BO_ 2566890251 PB_BSMData_0B: 8 BSM
 SG_ VehSpeedRear : 56|8@1+ (1,0) [0|250] "km/h"  PCM
 SG_ BsmRctbFail : 54|2@1+ (1,0) [0|3] ""  PCM
 SG_ BsmAebFail : 52|2@1+ (1,0) [0|3] ""  PCM
 SG_ BsmBtnSts : 50|1@1+ (1,0) [0|1] ""  PCM
 SG_ RollerbenchActvSts : 48|2@1+ (1,0) [0|3] ""  PCM
 SG_ HbaSts : 46|2@1+ (1,0) [0|3] ""  PCM
 SG_ CwaSts : 44|2@1+ (1,0) [0|3] ""  PCM
 SG_ MsrSts : 42|2@1+ (1,0) [0|3] ""  PCM
 SG_ HhSts : 40|2@1+ (1,0) [0|3] ""  PCM
 SG_ VdcSts : 38|2@1+ (1,0) [0|3] ""  PCM
 SG_ AsrSts : 36|2@1+ (1,0) [0|3] ""  PCM
 SG_ AbsSts : 34|2@1+ (1,0) [0|3] ""  PCM
 SG_ EbdSts : 32|2@1+ (1,0) [0|3] ""  PCM
 SG_ Hdc : 28|3@1+ (1,0) [0|7] ""  PCM
 SG_ BrkSig : 26|2@1+ (1,0) [0|3] ""  PCM
 SG_ VehSoftStop : 24|2@1+ (1,0) [0|3] ""  PCM
 SG_ Eol : 31|1@0+ (1,0) [0|1] ""  PCM
 SG_ VehMov : 22|2@1+ (1,0) [0|3] ""  PCM
 SG_ ParkBrkSw : 20|2@1+ (1,0) [0|3] ""  PCM
 SG_ ParkBrkRelsInhSts : 18|2@1+ (1,0) [0|3] ""  PCM
 SG_ ParkBrkAct : 16|2@1+ (1,0) [0|3] ""  PCM
 SG_ XbrSysSts_FFA30B : 14|2@1+ (1,0) [0|3] ""  PCM
 SG_ ParkBrkActFullyActv_FFA30B : 12|2@1+ (1,0) [0|3] ""  PCM

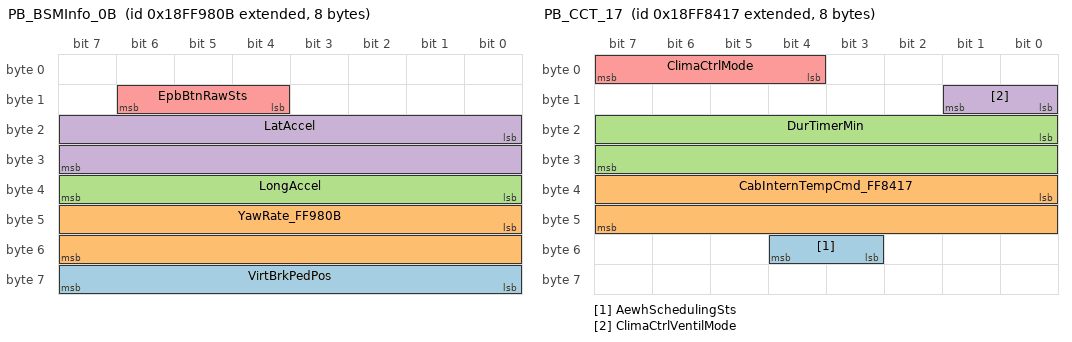
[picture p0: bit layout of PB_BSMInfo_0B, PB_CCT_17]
BO_ 2566887435 PB_BSMInfo_0B: 8 BSM
 SG_ VirtBrkPedPos : 56|8@1+ (0.4,0) [0|100] "%"  PCM
 SG_ YawRate_FF980B : 40|16@1+ (0.0001220703125,-3.92) [-3.92|3.92] "rad/s"  PCM
 SG_ LongAccel : 32|8@1+ (0.1,-12.5) [-12.5|12.5] "m/s�"  PCM
 SG_ LatAccel : 16|16@1+ (0.00048828125,-15.687) [-15.687|15.687] "m/s�"  PCM
 SG_ EpbBtnRawSts : 12|3@1+ (1,0) [0|7] ""  PCM

BO_ 2566854382 PB_CabotageRelData_EE: 32 DTCO
 SG_ LoadType : 248|8@1+ (1,0) [0|255] ""  PCM
 SG_ LastOpPlaceRecAuthenticationSts : 240|8@1+ (1,0) [0|255] ""  PCM
 SG_ LastOpPlaceRecLong : 216|24@1+ (1,180000) [-180000|180001] ""  PCM
 SG_ LastOpPlaceRecLat : 192|24@1+ (1,90000) [-90000|90001] ""  PCM
 SG_ LastOpPlaceRecGnssAccur : 184|8@1+ (1,0) [1|100] ""  PCM
 SG_ LastOpPlaceRecTs : 152|32@1+ (1,0) [0|4211081215] "sec"  PCM
 SG_ LastOpType : 144|8@1+ (1,0) [0|255] ""  PCM
 SG_ LastOpTimeStamp : 112|32@1+ (1,0) [0|4211081215] "sec"  PCM
 SG_ LastBorderCrossingPlaceRecAuthen : 104|8@1+ (1,0) [0|255] ""  PCM
 SG_ LastBorderCrossingPlaceRecLong : 80|24@1+ (1,180000) [-180000|180001] ""  PCM
 SG_ LastBorderCrossingPlaceRecLat : 56|24@1+ (1,90000) [-90000|90001] ""  PCM
 SG_ LastBorderCrossingPlaceRecGnssAc : 48|8@1+ (1,0) [1|100] ""  PCM
 SG_ LastBorderCrossingPlaceRecTs : 16|32@1+ (1,0) [0|4211081215] "sec"  PCM
 SG_ LastCntryEntered : 8|8@1+ (1,0) [0|255] ""  PCM
 SG_ LastCntryLeft : 0|8@1+ (1,0) [0|255] ""  PCM

BO_ 2566897985 PB_CallLog_41: 666 NIS_RDR
 SG_ CallLogIx10Txt : 120|8@1+ (1,0) [0|255] "ASCII"  PCM
 SG_ CallLogIx9Txt : 112|8@1+ (1,0) [0|255] "ASCII"  PCM
 SG_ CallLogIx8Txt : 104|8@1+ (1,0) [0|255] "ASCII"  PCM
 SG_ CallLogIx7Txt : 96|8@1+ (1,0) [0|255] "ASCII"  PCM
 SG_ CallLogIx6Txt : 88|8@1+ (1,0) [0|255] "ASCII"  PCM
 SG_ CallLogIx5Txt : 80|8@1+ (1,0) [0|255] "ASCII"  PCM
 SG_ CallLogIx4Txt : 72|8@1+ (1,0) [0|255] "ASCII"  PCM
 SG_ CallLogIx3Txt : 64|8@1+ (1,0) [0|255] "ASCII"  PCM
 SG_ CallLogIx2Txt : 56|8@1+ (1,0) [0|255] "ASCII"  PCM
 SG_ CallLogIx1Txt : 48|8@1+ (1,0) [0|255] "ASCII"  PCM
 SG_ CallLogIx10Type : 44|4@1+ (1,0) [0|15] ""  PCM
 SG_ CallLogIx9Type : 40|4@1+ (1,0) [0|15] ""  PCM
 SG_ CallLogIx8Type : 36|4@1+ (1,0) [0|15] ""  PCM
 SG_ CallLogIx7Type : 32|4@1+ (1,0) [0|15] ""  PCM
 SG_ CallLogIx6Type : 28|4@1+ (1,0) [0|15] ""  PCM
 SG_ CallLogIx5Type : 24|4@1+ (1,0) [0|15] ""  PCM
 SG_ CallLogIx4Type : 20|4@1+ (1,0) [0|15] ""  PCM
 SG_ CallLogIx3Type : 16|4@1+ (1,0) [0|15] ""  PCM
 SG_ CallLogIx2Type : 12|4@1+ (1,0) [0|15] ""  PCM
 SG_ CallLogIx1Type : 8|4@1+ (1,0) [0|15] ""  PCM
 SG_ CallLogEntriesNum : 4|4@1+ (1,0) [0|15] ""  PCM
 SG_ DevIx : 2|2@1+ (1,0) [0|3] ""  PCM
 SG_ TelephoneConn : 0|2@1+ (1,0) [0|3] ""  PCM

BO_ 2566882327 PB_CCT_17: 8 ICC
 SG_ AewhSchedulingSts : 51|2@1+ (1,0) [0|3] ""  PCM
 SG_ CabInternTempCmd_FF8417 : 32|16@1+ (0.03125,-273) [-273|1734.96875] "�C"  PCM
 SG_ DurTimerMin : 16|16@1+ (1,0) [0|64255] "min"  PCM
 SG_ ClimaCtrlVentilMode : 8|2@1+ (1,0) [0|3] ""  PCM
 SG_ ClimaCtrlMode : 4|4@1+ (1,0) [0|15] ""  PCM

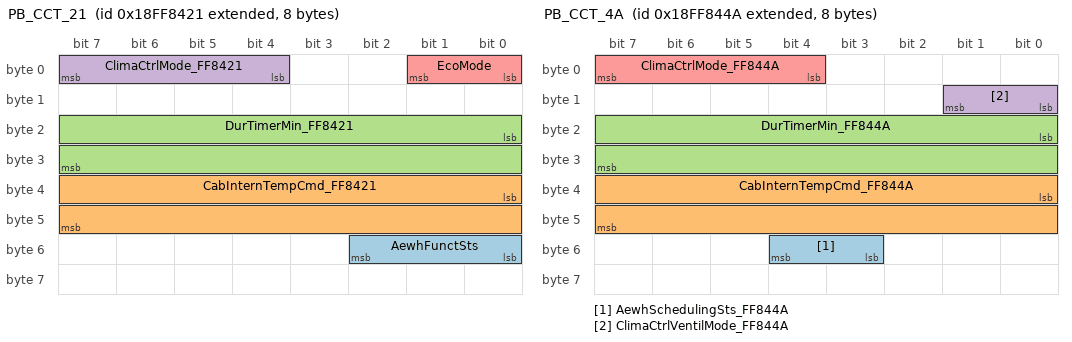
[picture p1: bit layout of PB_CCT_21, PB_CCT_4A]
BO_ 2566882337 PB_CCT_21: 8 BCM
 SG_ AewhFunctSts : 48|3@1+ (1,0) [0|7] ""  PCM
 SG_ CabInternTempCmd_FF8421 : 32|16@1+ (0.03125,-273) [-273|1734.96875] "�C"  PCM
 SG_ DurTimerMin_FF8421 : 16|16@1+ (1,0) [0|64255] "min"  PCM
 SG_ ClimaCtrlMode_FF8421 : 4|4@1+ (1,0) [0|15] ""  PCM
 SG_ EcoMode : 0|2@1+ (1,0) [0|3] ""  PCM

BO_ 2566882378 PB_CCT_4A: 8 PCM
 SG_ AewhSchedulingSts_FF844A : 51|2@1+ (1,0) [0|3] "" Vector__XXX
 SG_ CabInternTempCmd_FF844A : 32|16@1+ (0.03125,-273) [-273|1734.96875] "�C" Vector__XXX
 SG_ DurTimerMin_FF844A : 16|16@1+ (1,0) [0|64255] "min" Vector__XXX
 SG_ ClimaCtrlVentilMode_FF844A : 8|2@1+ (1,0) [0|3] "" Vector__XXX
 SG_ ClimaCtrlMode_FF844A : 4|4@1+ (1,0) [0|15] "" Vector__XXX

BO_ 2583654960 PB_CDCInfo_30: 8 CDC
 SG_ CdcActvMode : 0|4@1+ (1,0) [0|15] ""  PCM

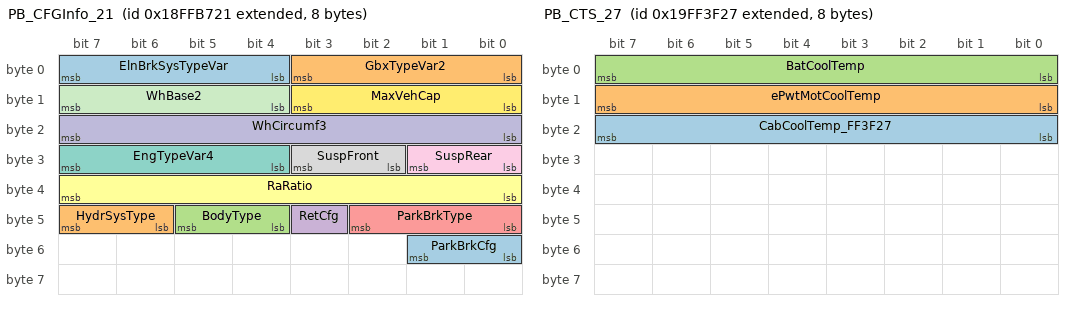
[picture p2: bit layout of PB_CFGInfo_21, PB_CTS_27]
BO_ 2566895393 PB_CFGInfo_21: 8 BCM
 SG_ ParkBrkCfg : 48|2@1+ (1,0) [0|3] ""  PCM
 SG_ HydrSysType : 46|2@1+ (1,0) [0|3] ""  PCM
 SG_ BodyType : 44|2@1+ (1,0) [0|3] ""  PCM
 SG_ RetCfg : 43|1@1+ (1,0) [0|1] ""  PCM
 SG_ ParkBrkType : 40|3@1+ (1,0) [0|7] ""  PCM
 SG_ RaRatio : 32|8@1+ (0.02,2.9) [2.9|8] ""  PCM
 SG_ EngTypeVar4 : 28|4@1+ (1,0) [0|15] ""  PCM
 SG_ SuspFront : 26|2@1+ (1,0) [0|3] ""  PCM
 SG_ SuspRear : 24|2@1+ (1,0) [0|3] ""  PCM
 SG_ WhCircumf3 : 16|8@1+ (5,1840) [1845|3115] "mm"  PCM
 SG_ WhBase2 : 12|4@1+ (1,0) [0|15] ""  PCM
 SG_ MaxVehCap : 8|4@1+ (1,0) [0|15] ""  PCM
 SG_ ElnBrkSysTypeVar : 4|4@1+ (1,0) [0|15] ""  PCM
 SG_ GbxTypeVar2 : 0|4@1+ (1,0) [0|15] ""  PCM

BO_ 2650777478 PB_CHGTC_86: 20 NODE_86
 SG_ ChgBelowNeg20_h : 144|16@1+ (1,0) [0|65535] "h"  PCM
 SG_ ChgBelowNeg10_h : 128|16@1+ (1,0) [0|65535] "h"  PCM
 SG_ ChgBelow0_h : 112|16@1+ (1,0) [0|65535] "h"  PCM
 SG_ ChgOver0_h : 96|16@1+ (1,0) [0|65535] "h"  PCM
 SG_ ChgOver15_h : 80|16@1+ (1,0) [0|65535] "h"  PCM
 SG_ ChgOver30_h : 64|16@1+ (1,0) [0|65535] "h"  PCM
 SG_ ChgOver35_h : 48|16@1+ (1,0) [0|65535] "h"  PCM
 SG_ ChgOver40_h : 32|16@1+ (1,0) [0|65535] "h"  PCM
 SG_ ChgOver45_h : 16|16@1+ (1,0) [0|65535] "h"  PCM
 SG_ ChgOver55_h : 0|16@1+ (1,0) [0|65535] "h"  PCM

BO_ 2650777479 PB_CHGTC_87: 20 NODE_87
 SG_ ChgBelowNeg20_h_FFA787 : 144|16@1+ (1,0) [0|65535] "h"  PCM
 SG_ ChgBelowNeg10_h_FFA787 : 128|16@1+ (1,0) [0|65535] "h"  PCM
 SG_ ChgBelow0_h_FFA787 : 112|16@1+ (1,0) [0|65535] "h"  PCM
 SG_ ChgOver0_h_FFA787 : 96|16@1+ (1,0) [0|65535] "h"  PCM
 SG_ ChgOver15_h_FFA787 : 80|16@1+ (1,0) [0|65535] "h"  PCM
 SG_ ChgOver30_h_FFA787 : 64|16@1+ (1,0) [0|65535] "h"  PCM
 SG_ ChgOver35_h_FFA787 : 48|16@1+ (1,0) [0|65535] "h"  PCM
 SG_ ChgOver40_h_FFA787 : 32|16@1+ (1,0) [0|65535] "h"  PCM
 SG_ ChgOver45_h_FFA787 : 16|16@1+ (1,0) [0|65535] "h"  PCM
 SG_ ChgOver55_h_FFA787 : 0|16@1+ (1,0) [0|65535] "h"  PCM

BO_ 2650777588 PB_CHGTC_F4: 20 NODE_F4
 SG_ ChgBelowNeg20_h_FFA7F4 : 144|16@1+ (1,0) [0|65535] "h"  PCM
 SG_ ChgBelowNeg10_h_FFA7F4 : 128|16@1+ (1,0) [0|65535] "h"  PCM
 SG_ ChgBelow0_h_FFA7F4 : 112|16@1+ (1,0) [0|65535] "h"  PCM
 SG_ ChgOver0_h_FFA7F4 : 96|16@1+ (1,0) [0|65535] "h"  PCM
 SG_ ChgOver15_h_FFA7F4 : 80|16@1+ (1,0) [0|65535] "h"  PCM
 SG_ ChgOver30_h_FFA7F4 : 64|16@1+ (1,0) [0|65535] "h"  PCM
 SG_ ChgOver35_h_FFA7F4 : 48|16@1+ (1,0) [0|65535] "h"  PCM
 SG_ ChgOver40_h_FFA7F4 : 32|16@1+ (1,0) [0|65535] "h"  PCM
 SG_ ChgOver45_h_FFA7F4 : 16|16@1+ (1,0) [0|65535] "h"  PCM
 SG_ ChgOver55_h_FFA7F4 : 0|16@1+ (1,0) [0|65535] "h"  PCM

BO_ 2650777589 PB_CHGTC_F5: 20 NODE_F5
 SG_ ChgBelowNeg20_h_FFA7F5 : 144|16@1+ (1,0) [0|65535] "h"  PCM
 SG_ ChgBelowNeg10_h_FFA7F5 : 128|16@1+ (1,0) [0|65535] "h"  PCM
 SG_ ChgBelow0_h_FFA7F5 : 112|16@1+ (1,0) [0|65535] "h"  PCM
 SG_ ChgOver0_h_FFA7F5 : 96|16@1+ (1,0) [0|65535] "h"  PCM
 SG_ ChgOver15_h_FFA7F5 : 80|16@1+ (1,0) [0|65535] "h"  PCM
 SG_ ChgOver30_h_FFA7F5 : 64|16@1+ (1,0) [0|65535] "h"  PCM
 SG_ ChgOver35_h_FFA7F5 : 48|16@1+ (1,0) [0|65535] "h"  PCM
 SG_ ChgOver40_h_FFA7F5 : 32|16@1+ (1,0) [0|65535] "h"  PCM
 SG_ ChgOver45_h_FFA7F5 : 16|16@1+ (1,0) [0|65535] "h"  PCM
 SG_ ChgOver55_h_FFA7F5 : 0|16@1+ (1,0) [0|65535] "h"  PCM

BO_ 2650777590 PB_CHGTC_F6: 20 NODE_F6
 SG_ ChgBelowNeg20_h_FFA7F6 : 144|16@1+ (1,0) [0|65535] "h"  PCM
 SG_ ChgBelowNeg10_h_FFA7F6 : 128|16@1+ (1,0) [0|65535] "h"  PCM
 SG_ ChgBelow0_h_FFA7F6 : 112|16@1+ (1,0) [0|65535] "h"  PCM
 SG_ ChgOver0_h_FFA7F6 : 96|16@1+ (1,0) [0|65535] "h"  PCM
 SG_ ChgOver15_h_FFA7F6 : 80|16@1+ (1,0) [0|65535] "h"  PCM
 SG_ ChgOver30_h_FFA7F6 : 64|16@1+ (1,0) [0|65535] "h"  PCM
 SG_ ChgOver35_h_FFA7F6 : 48|16@1+ (1,0) [0|65535] "h"  PCM
 SG_ ChgOver40_h_FFA7F6 : 32|16@1+ (1,0) [0|65535] "h"  PCM
 SG_ ChgOver45_h_FFA7F6 : 16|16@1+ (1,0) [0|65535] "h"  PCM
 SG_ ChgOver55_h_FFA7F6 : 0|16@1+ (1,0) [0|65535] "h"  PCM

BO_ 2583641895 PB_CTS_27: 8 VCM
 SG_ CabCoolTemp_FF3F27 : 16|8@1+ (1,-40) [-40|210] "�C"  PCM
 SG_ ePwtMotCoolTemp : 8|8@1+ (1,-40) [-40|210] "�C"  PCM
 SG_ BatCoolTemp : 0|8@1+ (1,-40) [-40|210] "�C"  PCM

BO_ 2566910273 PB_DevInf_41: 67 NIS_RDR
 SG_ DevName : 8|8@1+ (1,0) [0|255] "ASCII"  PCM
 SG_ DevIx_FFF141 : 0|2@1+ (1,0) [0|3] ""  PCM

BO_ 2566883879 PB_DPD_27: 8 VCM
 SG_ RngDeterminationRstFdbk : 24|2@1+ (1,0) [0|3] ""  PCM
 SG_ DrivProfIdFdbk : 19|3@1+ (1,0) [0|7] ""  PCM

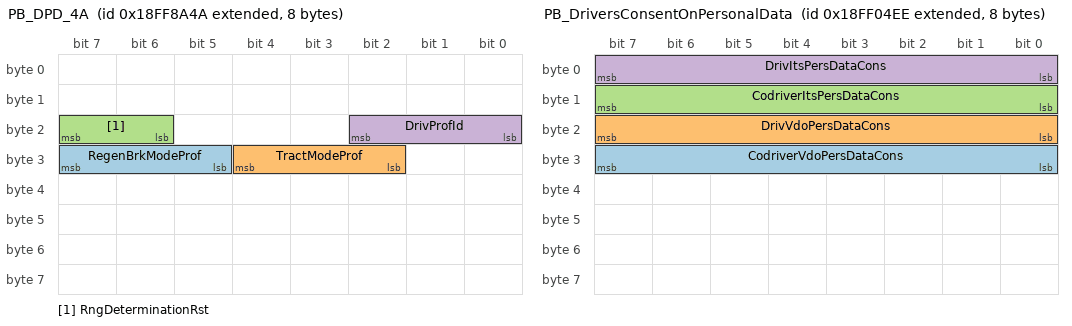
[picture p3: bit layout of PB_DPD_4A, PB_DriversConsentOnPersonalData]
BO_ 2566883914 PB_DPD_4A: 8 PCM
 SG_ RegenBrkModeProf : 29|3@1+ (1,0) [0|7] "" Vector__XXX
 SG_ TractModeProf : 26|3@1+ (1,0) [0|7] "" Vector__XXX
 SG_ RngDeterminationRst : 22|2@1+ (1,0) [0|3] "" Vector__XXX
 SG_ DrivProfId : 16|3@1+ (1,0) [0|7] "" Vector__XXX

BO_ 2566849774 PB_DriversConsentOnPersonalData: 8 DTCO
 SG_ CodriverVdoPersDataCons : 24|8@1+ (1,0) [0|250] ""  PCM
 SG_ DrivVdoPersDataCons : 16|8@1+ (1,0) [0|250] ""  PCM
 SG_ CodriverItsPersDataCons : 8|8@1+ (1,0) [0|250] ""  PCM
 SG_ DrivItsPersDataCons : 0|8@1+ (1,0) [0|250] ""  PCM

BO_ 2566865994 PB_Dse_4A: 40 PCM
 SG_ DseIxBenf_10 : 312|8@1+ (1,0) [0|100] "" Vector__XXX
 SG_ DseIxVal_10 : 304|8@1+ (1,0) [0|100] "" Vector__XXX
 SG_ DseIxFrzSts_10 : 298|2@1+ (1,0) [0|3] "" Vector__XXX
 SG_ DseIxTrend_10 : 296|2@1+ (1,0) [0|3] "" Vector__XXX
 SG_ DseIxBenf_9 : 288|8@1+ (1,0) [0|100] "" Vector__XXX
 SG_ DseIxVal_9 : 280|8@1+ (1,0) [0|100] "" Vector__XXX
 SG_ DseIxFrzSts_9 : 274|2@1+ (1,0) [0|3] "" Vector__XXX
 SG_ DseIxTrend_9 : 272|2@1+ (1,0) [0|3] "" Vector__XXX
 SG_ DseIxBenf_8 : 264|8@1+ (1,0) [0|100] "" Vector__XXX
 SG_ DseIxVal_8 : 256|8@1+ (1,0) [0|100] "" Vector__XXX
 SG_ DseIxFrzSts_8 : 250|2@1+ (1,0) [0|3] "" Vector__XXX
 SG_ DseIxTrend_8 : 248|2@1+ (1,0) [0|3] "" Vector__XXX
 SG_ DseIxBenf_7 : 240|8@1+ (1,0) [0|100] "" Vector__XXX
 SG_ DseIxVal_7 : 232|8@1+ (1,0) [0|100] "" Vector__XXX
 SG_ DseIxFrzSts_7 : 226|2@1+ (1,0) [0|3] "" Vector__XXX
 SG_ DseIxTrend_7 : 224|2@1+ (1,0) [0|3] "" Vector__XXX
 SG_ DseIxBenf_6 : 216|8@1+ (1,0) [0|100] "" Vector__XXX
 SG_ DseIxVal_6 : 208|8@1+ (1,0) [0|100] "" Vector__XXX
 SG_ DseIxFrzSts_6 : 202|2@1+ (1,0) [0|3] "" Vector__XXX
 SG_ DseIxTrend_6 : 200|2@1+ (1,0) [0|3] "" Vector__XXX
 SG_ DseIxBenf_5 : 192|8@1+ (1,0) [0|100] "" Vector__XXX
 SG_ DseIxVal_5 : 184|8@1+ (1,0) [0|100] "" Vector__XXX
 SG_ DseIxFrzSts_5 : 178|2@1+ (1,0) [0|3] "" Vector__XXX
 SG_ DseIxTrend_5 : 176|2@1+ (1,0) [0|3] "" Vector__XXX
 SG_ DseIxBenf_4 : 168|8@1+ (1,0) [0|100] "" Vector__XXX
 SG_ DseIxVal_4 : 160|8@1+ (1,0) [0|100] "" Vector__XXX
 SG_ DseIxFrzSts_4 : 154|2@1+ (1,0) [0|3] "" Vector__XXX
 SG_ DseIxTrend_4 : 152|2@1+ (1,0) [0|3] "" Vector__XXX
 SG_ DseIxBenf_3_EngUse : 144|8@1+ (1,0) [0|100] "" Vector__XXX
 SG_ DseIxVal_3_EngUse : 136|8@1+ (1,0) [0|100] "" Vector__XXX
 SG_ DseIxFrzSts_3_EngUse : 130|2@1+ (1,0) [0|3] "" Vector__XXX
 SG_ DseIxTrend_3_EngUse : 128|2@1+ (1,0) [0|3] "" Vector__XXX
 SG_ DseIxBenf_2_Decel : 120|8@1+ (1,0) [0|100] "" Vector__XXX
 SG_ DseIxVal_2_Decel : 112|8@1+ (1,0) [0|100] "" Vector__XXX
 SG_ DseIxFrzSts_2_Decel : 106|2@1+ (1,0) [0|3] "" Vector__XXX
 SG_ DseIxTrend_2_Decel : 104|2@1+ (1,0) [0|3] "" Vector__XXX
 SG_ DseIxBenf_1_Accel : 96|8@1+ (1,0) [0|100] "" Vector__XXX
 SG_ DseIxVal_1_Accel : 88|8@1+ (1,0) [0|100] "" Vector__XXX
 SG_ DseIxFrzSts_1_Accel : 82|2@1+ (1,0) [0|3] "" Vector__XXX
 SG_ DseIxTrend_1_Accel : 80|2@1+ (1,0) [0|3] "" Vector__XXX
 SG_ DseEvalTime : 64|16@1+ (1,0) [0|64255] "s" Vector__XXX
 SG_ DseEvalDist : 48|16@1+ (0.1,0) [0|6425.5] "km" Vector__XXX
 SG_ DseStartMissTs : 16|32@1+ (1,0) [0|4211081215] "" Vector__XXX
 SG_ DsePopupIx : 8|8@1+ (1,0) [0|100] "" Vector__XXX
 SG_ DsePopupIcon : 4|4@1+ (1,0) [0|15] "" Vector__XXX
 SG_ DseSts : 0|4@1+ (1,0) [0|15] "" Vector__XXX

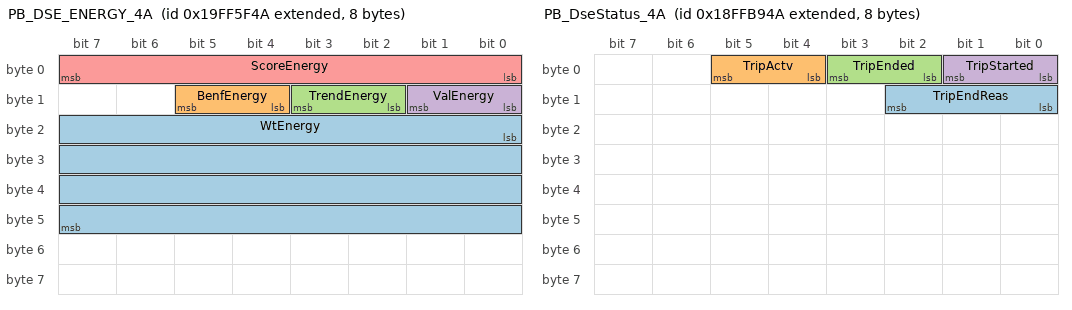
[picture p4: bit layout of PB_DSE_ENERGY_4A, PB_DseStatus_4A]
BO_ 2583650122 PB_DSE_ENERGY_4A: 8 PCM
 SG_ WtEnergy : 16|32@1+ (1,-1) [-1|4294967294] "" Vector__XXX
 SG_ BenfEnergy : 12|2@1+ (1,0) [0|3] "" Vector__XXX
 SG_ TrendEnergy : 10|2@1+ (1,-1) [-1|2] "" Vector__XXX
 SG_ ValEnergy : 8|2@1+ (1,0) [0|3] "" Vector__XXX
 SG_ ScoreEnergy : 0|8@1+ (1,-1) [-1|254] "" Vector__XXX

BO_ 2566895690 PB_DseStart_4A: 8 PCM
 SG_ TsTripStart : 32|32@1+ (1,946684800) [946684800|5157766015] "count" Vector__XXX
 SG_ OdoTripStart : 0|32@1+ (5,-1) [-1|21055406074] "m" Vector__XXX

BO_ 2566895946 PB_DseStatus_4A: 8 PCM
 SG_ TripEndReas : 8|3@1+ (1,0) [0|7] "" Vector__XXX
 SG_ TripActv : 4|2@1+ (1,0) [0|3] "" Vector__XXX
 SG_ TripEnded : 2|2@1+ (1,0) [0|3] "" Vector__XXX
 SG_ TripStarted : 0|2@1+ (1,0) [0|3] "" Vector__XXX

BO_ 2650777222 PB_DSGTC_86: 20 NODE_86
 SG_ DsgBelowNeg20_h : 144|16@1+ (1,0) [0|65535] "h"  PCM
 SG_ DsgBelowNeg10_h : 128|16@1+ (1,0) [0|65535] "h"  PCM
 SG_ DsgBelow0_h : 112|16@1+ (1,0) [0|65535] "h"  PCM
 SG_ DsgOver0_h : 96|16@1+ (1,0) [0|65535] "h"  PCM
 SG_ DsgOver15_h : 80|16@1+ (1,0) [0|65535] "h"  PCM
 SG_ DsgOver30_h : 64|16@1+ (1,0) [0|65535] "h"  PCM
 SG_ DsgOver35_h : 48|16@1+ (1,0) [0|65535] "h"  PCM
 SG_ DsgOver40_h : 32|16@1+ (1,0) [0|65535] "h"  PCM
 SG_ DsgOver45_h : 16|16@1+ (1,0) [0|65535] "h"  PCM
 SG_ DsgOver55_h : 0|16@1+ (1,0) [0|65535] "h"  PCM

BO_ 2650777223 PB_DSGTC_87: 20 NODE_87
 SG_ DsgBelowNeg20_h_FFA687 : 144|16@1+ (1,0) [0|65535] "h"  PCM
 SG_ DsgBelowNeg10_h_FFA687 : 128|16@1+ (1,0) [0|65535] "h"  PCM
 SG_ DsgBelow0_h_FFA687 : 112|16@1+ (1,0) [0|65535] "h"  PCM
 SG_ DsgOver0_h_FFA687 : 96|16@1+ (1,0) [0|65535] "h"  PCM
 SG_ DsgOver15_h_FFA687 : 80|16@1+ (1,0) [0|65535] "h"  PCM
 SG_ DsgOver30_h_FFA687 : 64|16@1+ (1,0) [0|65535] "h"  PCM
 SG_ DsgOver35_h_FFA687 : 48|16@1+ (1,0) [0|65535] "h"  PCM
 SG_ DsgOver40_h_FFA687 : 32|16@1+ (1,0) [0|65535] "h"  PCM
 SG_ DsgOver45_h_FFA687 : 16|16@1+ (1,0) [0|65535] "h"  PCM
 SG_ DsgOver55_h_FFA687 : 0|16@1+ (1,0) [0|65535] "h"  PCM

BO_ 2650777332 PB_DSGTC_F4: 20 NODE_F4
 SG_ DsgBelowNeg20_h_FFA6F4 : 144|16@1+ (1,0) [0|65535] "h"  PCM
 SG_ DsgBelowNeg10_h_FFA6F4 : 128|16@1+ (1,0) [0|65535] "h"  PCM
 SG_ DsgBelow0_h_FFA6F4 : 112|16@1+ (1,0) [0|65535] "h"  PCM
 SG_ DsgOver0_h_FFA6F4 : 96|16@1+ (1,0) [0|65535] "h"  PCM
 SG_ DsgOver15_h_FFA6F4 : 80|16@1+ (1,0) [0|65535] "h"  PCM
 SG_ DsgOver30_h_FFA6F4 : 64|16@1+ (1,0) [0|65535] "h"  PCM
 SG_ DsgOver35_h_FFA6F4 : 48|16@1+ (1,0) [0|65535] "h"  PCM
 SG_ DsgOver40_h_FFA6F4 : 32|16@1+ (1,0) [0|65535] "h"  PCM
 SG_ DsgOver45_h_FFA6F4 : 16|16@1+ (1,0) [0|65535] "h"  PCM
 SG_ DsgOver55_h_FFA6F4 : 0|16@1+ (1,0) [0|65535] "h"  PCM

BO_ 2650777333 PB_DSGTC_F5: 20 NODE_F5
 SG_ DsgBelowNeg20_h_FFA6F5 : 144|16@1+ (1,0) [0|65535] "h"  PCM
 SG_ DsgBelowNeg10_h_FFA6F5 : 128|16@1+ (1,0) [0|65535] "h"  PCM
 SG_ DsgBelow0_h_FFA6F5 : 112|16@1+ (1,0) [0|65535] "h"  PCM
 SG_ DsgOver0_h_FFA6F5 : 96|16@1+ (1,0) [0|65535] "h"  PCM
 SG_ DsgOver15_h_FFA6F5 : 80|16@1+ (1,0) [0|65535] "h"  PCM
 SG_ DsgOver30_h_FFA6F5 : 64|16@1+ (1,0) [0|65535] "h"  PCM
 SG_ DsgOver35_h_FFA6F5 : 48|16@1+ (1,0) [0|65535] "h"  PCM
 SG_ DsgOver40_h_FFA6F5 : 32|16@1+ (1,0) [0|65535] "h"  PCM
 SG_ DsgOver45_h_FFA6F5 : 16|16@1+ (1,0) [0|65535] "h"  PCM
 SG_ DsgOver55_h_FFA6F5 : 0|16@1+ (1,0) [0|65535] "h"  PCM

BO_ 2650777334 PB_DSGTC_F6: 20 NODE_F6
 SG_ DsgBelowNeg20_h_FFA6F6 : 144|16@1+ (1,0) [0|65535] "h"  PCM
 SG_ DsgBelowNeg10_h_FFA6F6 : 128|16@1+ (1,0) [0|65535] "h"  PCM
 SG_ DsgBelow0_h_FFA6F6 : 112|16@1+ (1,0) [0|65535] "h"  PCM
 SG_ DsgOver0_h_FFA6F6 : 96|16@1+ (1,0) [0|65535] "h"  PCM
 SG_ DsgOver15_h_FFA6F6 : 80|16@1+ (1,0) [0|65535] "h"  PCM
 SG_ DsgOver30_h_FFA6F6 : 64|16@1+ (1,0) [0|65535] "h"  PCM
 SG_ DsgOver35_h_FFA6F6 : 48|16@1+ (1,0) [0|65535] "h"  PCM
 SG_ DsgOver40_h_FFA6F6 : 32|16@1+ (1,0) [0|65535] "h"  PCM
 SG_ DsgOver45_h_FFA6F6 : 16|16@1+ (1,0) [0|65535] "h"  PCM
 SG_ DsgOver55_h_FFA6F6 : 0|16@1+ (1,0) [0|65535] "h"  PCM

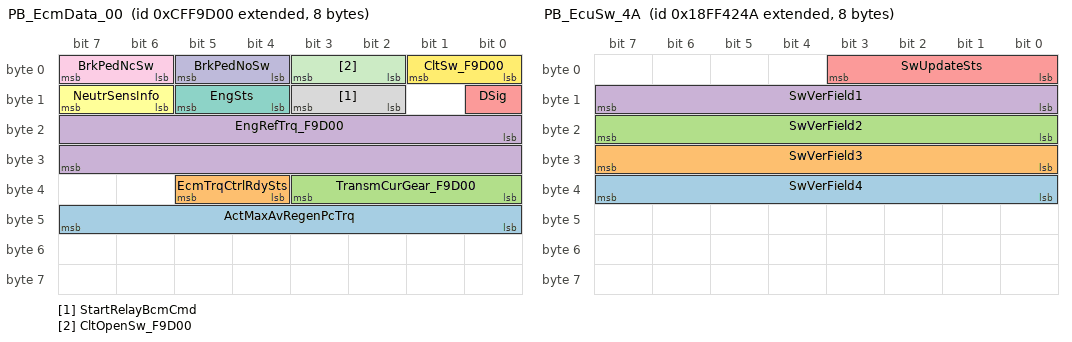
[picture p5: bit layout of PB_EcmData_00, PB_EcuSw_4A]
BO_ 2365562112 PB_EcmData_00: 8 ECM
 SG_ ActMaxAvRegenPcTrq : 40|8@1+ (0.4,0) [0|100] "%"  PCM
 SG_ EcmTrqCtrlRdySts : 36|2@1+ (1,0) [0|3] ""  PCM
 SG_ TransmCurGear_F9D00 : 32|4@1+ (1,0) [0|15] ""  PCM
 SG_ EngRefTrq_F9D00 : 16|16@1+ (1,0) [0|64255] "Nm"  PCM
 SG_ DSig : 8|1@0+ (1,0) [0|1] ""  PCM
 SG_ NeutrSensInfo : 14|2@1+ (1,0) [0|3] ""  PCM
 SG_ EngSts : 12|2@1+ (1,0) [0|3] ""  PCM
 SG_ StartRelayBcmCmd : 10|2@1+ (1,0) [0|3] ""  PCM
 SG_ BrkPedNcSw : 6|2@1+ (1,0) [0|3] ""  PCM
 SG_ BrkPedNoSw : 4|2@1+ (1,0) [0|3] ""  PCM
 SG_ CltOpenSw_F9D00 : 2|2@1+ (1,0) [0|3] ""  PCM
 SG_ CltSw_F9D00 : 0|2@1+ (1,0) [0|3] ""  PCM

BO_ 2566865482 PB_EcuSw_4A: 8 PCM
 SG_ SwVerField4 : 32|8@1+ (1,0) [0|250] "" Vector__XXX
 SG_ SwVerField3 : 24|8@1+ (1,0) [0|250] "" Vector__XXX
 SG_ SwVerField2 : 16|8@1+ (1,0) [0|250] "" Vector__XXX
 SG_ SwVerField1 : 8|8@1+ (1,0) [0|250] "" Vector__XXX
 SG_ SwUpdateSts : 0|4@1+ (1,0) [0|15] "" Vector__XXX

BO_ 2583638311 PB_ED1_27: 8 VCM
 SG_ TotHvacEnergyConsHeatBat : 32|32@1+ (0.1,0) [0|421108121.5] "kWh"  PCM
 SG_ TotHvacEnergyConsHeatCab : 0|32@1+ (0.1,0) [0|421108121.5] "kWh"  PCM

BO_ 2583638567 PB_ED2_27: 8 VCM
 SG_ TotEnergyRecharged : 32|32@1+ (0.1,0) [0|421108121.5] "kWh"  PCM
 SG_ TotHvacEnergyConsCool : 0|32@1+ (0.1,0) [0|421108121.5] "kWh"  PCM

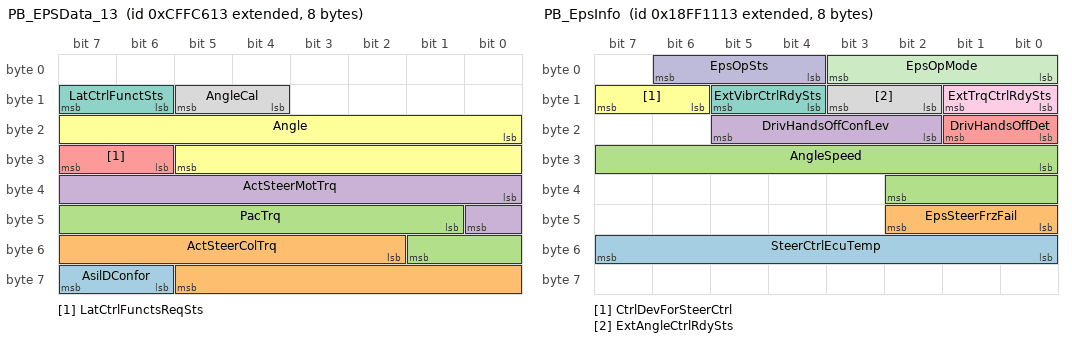
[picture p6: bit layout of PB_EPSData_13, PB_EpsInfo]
BO_ 2365572627 PB_EPSData_13: 8 NODE_13
 SG_ AsilDConfor : 62|2@1+ (1,0) [0|3] ""  PCM
 SG_ ActSteerColTrq : 50|12@1+ (0.005,-10) [-10|10.075] "Nm"  PCM
 SG_ PacTrq : 41|9@1+ (0.04,-10) [-10|10.24] "Nm"  PCM
 SG_ ActSteerMotTrq : 32|9@1+ (0.04,-10) [-10|10.24] "Nm"  PCM
 SG_ LatCtrlFunctsReqSts : 30|2@1+ (1,0) [0|3] ""  PCM
 SG_ Angle : 16|14@1+ (0.1,-818.9) [-818.9|818.9] "deg"  PCM
 SG_ LatCtrlFunctSts : 14|2@1+ (1,0) [0|3] ""  PCM
 SG_ AngleCal : 12|2@1+ (1,0) [0|3] ""  PCM

BO_ 2566852883 PB_EpsInfo: 8 NODE_13
 SG_ SteerCtrlEcuTemp : 48|8@1+ (1,-40) [-40|210] "�C"  PCM
 SG_ EpsSteerFrzFail : 40|3@1+ (1,0) [0|7] ""  PCM
 SG_ AngleSpeed : 24|11@1+ (1,-1021) [-1021|1021] "deg/s"  PCM
 SG_ DrivHandsOffConfLev : 18|4@1+ (1,0) [0|15] ""  PCM
 SG_ DrivHandsOffDet : 16|2@1+ (1,0) [0|3] ""  PCM
 SG_ CtrlDevForSteerCtrl : 14|2@1+ (1,0) [0|3] ""  PCM
 SG_ ExtVibrCtrlRdySts : 12|2@1+ (1,0) [0|3] ""  PCM
 SG_ ExtAngleCtrlRdySts : 10|2@1+ (1,0) [0|3] ""  PCM
 SG_ ExtTrqCtrlRdySts : 8|2@1+ (1,0) [0|3] ""  PCM
 SG_ EpsOpSts : 4|3@1+ (1,0) [0|7] ""  PCM
 SG_ EpsOpMode : 0|4@1+ (1,0) [0|15] ""  PCM

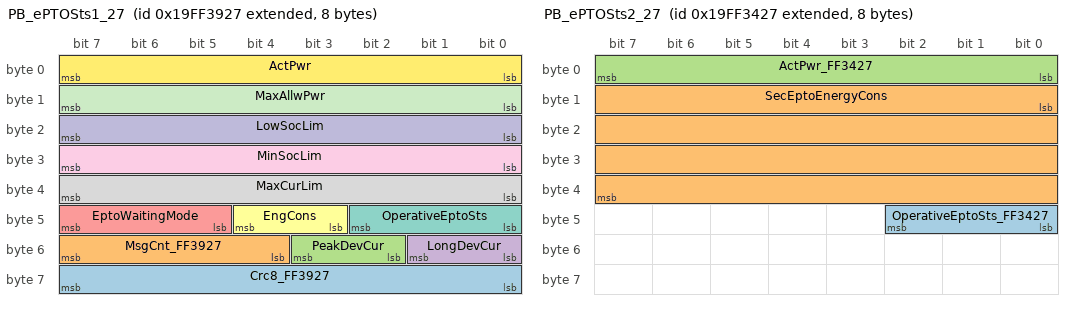
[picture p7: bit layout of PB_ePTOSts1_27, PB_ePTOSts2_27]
BO_ 2583640359 PB_ePTOSts1_27: 8 VCM
 SG_ Crc8_FF3927 : 56|8@1+ (1,0) [0|255] ""  PCM
 SG_ MsgCnt_FF3927 : 52|4@1+ (1,0) [0|15] "count"  PCM
 SG_ PeakDevCur : 50|2@1+ (1,0) [0|3] ""  PCM
 SG_ LongDevCur : 48|2@1+ (1,0) [0|3] ""  PCM
 SG_ EptoWaitingMode : 45|3@1+ (1,0) [0|7] ""  PCM
 SG_ EngCons : 43|2@1+ (1,0) [0|3] ""  PCM
 SG_ OperativeEptoSts : 40|3@1+ (1,0) [0|7] ""  PCM
 SG_ MaxCurLim : 32|8@1+ (0.5,0) [0|125] "A"  PCM
 SG_ MinSocLim : 24|8@1+ (0.4,0) [0|100] "%"  PCM
 SG_ LowSocLim : 16|8@1+ (0.4,0) [0|100] "%"  PCM
 SG_ MaxAllwPwr : 8|8@1+ (0.5,0) [0|125] "kW"  PCM
 SG_ ActPwr : 0|8@1+ (0.5,0) [0|125] "kW"  PCM

BO_ 2583639079 PB_ePTOSts2_27: 8 VCM
 SG_ OperativeEptoSts_FF3427 : 40|3@1+ (1,0) [0|7] ""  PCM
 SG_ SecEptoEnergyCons : 8|32@1+ (0.1,0) [0|421108121.5] "kWh"  PCM
 SG_ ActPwr_FF3427 : 0|8@1+ (0.5,0) [0|125] "kW"  PCM

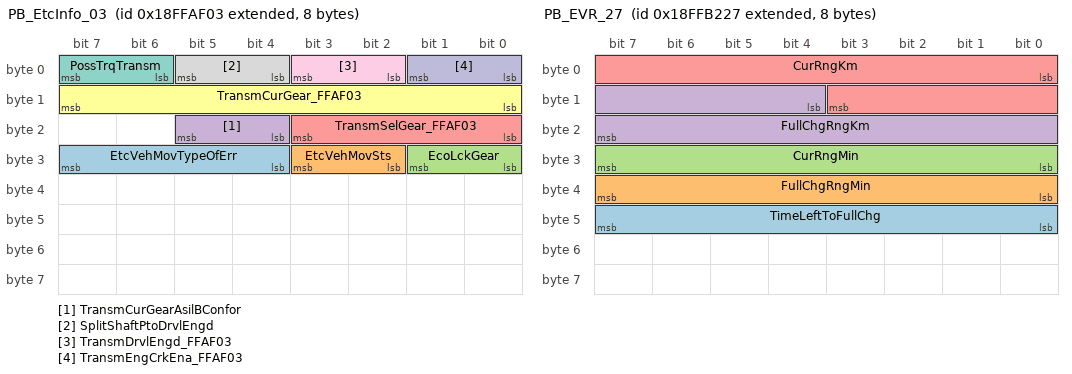
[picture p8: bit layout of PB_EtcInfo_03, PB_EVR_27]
BO_ 2566893315 PB_EtcInfo_03: 8 AI_G5_TCM
 SG_ EtcVehMovTypeOfErr : 28|4@1+ (1,0) [0|15] ""  PCM
 SG_ EtcVehMovSts : 26|2@1+ (1,0) [0|3] ""  PCM
 SG_ EcoLckGear : 24|2@1+ (1,0) [0|3] ""  PCM
 SG_ TransmCurGearAsilBConfor : 20|2@1+ (1,0) [0|3] ""  PCM
 SG_ TransmSelGear_FFAF03 : 16|4@1+ (1,0) [0|15] ""  PCM
 SG_ TransmCurGear_FFAF03 : 8|8@1+ (1,-125) [-125|125] "gear value"  PCM
 SG_ PossTrqTransm : 6|2@1+ (1,0) [0|3] ""  PCM
 SG_ SplitShaftPtoDrvlEngd : 4|2@1+ (1,0) [0|3] ""  PCM
 SG_ TransmDrvlEngd_FFAF03 : 2|2@1+ (1,0) [0|3] ""  PCM
 SG_ TransmEngCrkEna_FFAF03 : 0|2@1+ (1,0) [0|3] ""  PCM

BO_ 2566894119 PB_EVR_27: 8 VCM
 SG_ TimeLeftToFullChg : 40|8@1+ (5,0) [0|1250] "min"  PCM
 SG_ FullChgRngMin : 32|8@1+ (2,0) [0|500] "min"  PCM
 SG_ CurRngMin : 24|8@1+ (2,0) [0|500] "min"  PCM
 SG_ FullChgRngKm : 12|12@1+ (1,0) [0|4095] "km"  PCM
 SG_ CurRngKm : 0|12@1+ (1,0) [0|4095] "km"  PCM

BO_ 2566886730 PB_FMRS_4A: 8 PCM
 SG_ FmsIAccMan_AutoCfg : 48|3@1+ (1,0) [0|7] "" Vector__XXX
 SG_ FmsIsaAcousticWarnCfg : 46|2@1+ (1,0) [0|3] "" Vector__XXX
 SG_ FmsISACfg : 44|2@1+ (1,0) [0|3] "" Vector__XXX
 SG_ FmsLkaCfg : 42|2@1+ (1,0) [0|3] "" Vector__XXX
 SG_ FmsAhbcCfg : 40|2@1+ (1,0) [0|3] "" Vector__XXX
 SG_ FmsIsaSpeedLimCfg : 37|3@1+ (1,0) [0|7] "" Vector__XXX
 SG_ FmsAebsSensCfg : 34|3@1+ (1,0) [0|7] "" Vector__XXX
 SG_ FmsDistWarnCfg : 32|2@1+ (1,0) [0|3] "" Vector__XXX
 SG_ FmsAEBSCfg : 30|2@1+ (1,0) [0|3] "" Vector__XXX
 SG_ FmsDdawSensCfg : 28|2@1+ (1,0) [0|3] "" Vector__XXX
 SG_ FmsDdawWarnCfg : 26|2@1+ (1,0) [0|3] "" Vector__XXX
 SG_ FmsDoorOpenWarnFunctCfg : 24|2@1+ (1,0) [0|3] "" Vector__XXX
 SG_ FmsBsisAcousticWarnCfg : 22|2@1+ (1,0) [0|3] "" Vector__XXX
 SG_ FmsMoisFunctCfg : 20|2@1+ (1,0) [0|3] "" Vector__XXX
 SG_ FmsRCTFunctCfg : 18|2@1+ (1,0) [0|3] "" Vector__XXX
 SG_ FmsRCTAcousticWarnCfg : 16|2@1+ (1,0) [0|3] "" Vector__XXX
 SG_ FmsBlindSpotFunctCfg : 14|2@1+ (1,0) [0|3] "" Vector__XXX
 SG_ FmsBlindSpotAcousticWarnCfg : 12|2@1+ (1,0) [0|3] "" Vector__XXX

BO_ 2566886935 PB_FMRSF_17: 8 ICC
 SG_ IsaSpeedLimCfgFmsFdbk : 48|2@1+ (1,0) [0|3] ""  PCM
 SG_ IAccCfgFmsFdbk : 44|2@1+ (1,0) [0|3] ""  PCM
 SG_ IsaAcousticWarnCfgFmsFdbk : 42|2@1+ (1,0) [0|3] ""  PCM
 SG_ ISACfgFmsFdbk : 40|2@1+ (1,0) [0|3] ""  PCM
 SG_ LkaCfgFmsFdbk : 38|2@1+ (1,0) [0|3] ""  PCM
 SG_ AhbcCfgFmsFdbk : 36|2@1+ (1,0) [0|3] ""  PCM
 SG_ DistWarnCfgFmsFdbk : 34|2@1+ (1,0) [0|3] ""  PCM
 SG_ AebsSensCfgFmsFdbk : 32|2@1+ (1,0) [0|3] ""  PCM
 SG_ AEBSCfgFmsFdbk : 30|2@1+ (1,0) [0|3] ""  PCM
 SG_ DdawSensCfgFmsFdbk : 28|2@1+ (1,0) [0|3] ""  PCM
 SG_ DdawWarnCfgFmsFdbk : 26|2@1+ (1,0) [0|3] ""  PCM
 SG_ DoorOpenWarnFunctCfgFmsFdbk : 24|2@1+ (1,0) [0|3] ""  PCM
 SG_ BsisAcousticWarnCfgFmsFdbk : 22|2@1+ (1,0) [0|3] ""  PCM
 SG_ MoisFunctCfgFmsFdbk : 20|2@1+ (1,0) [0|3] ""  PCM
 SG_ RCTAFunctCfgFmsFdbk : 18|2@1+ (1,0) [0|3] ""  PCM
 SG_ RCTAcousticWarnCfgFmsFdbk : 16|2@1+ (1,0) [0|3] ""  PCM
 SG_ BlindSpotFunctCfgFmsFdbk : 14|2@1+ (1,0) [0|3] ""  PCM
 SG_ BlindSpotAcousticWarnCfgFmsFdbk : 12|2@1+ (1,0) [0|3] ""  PCM

BO_ 2583655201 PB_GenCtrl_21: 8 BCM
 SG_ WndLifterLeftSts : 61|3@1+ (1,0) [0|7] ""  PCM
 SG_ WndLifterRightSts : 58|3@1+ (1,0) [0|7] ""  PCM
 SG_ LowBatDev : 56|2@1+ (1,0) [0|3] ""  PCM
 SG_ TurnSigSw_FF7321 : 52|4@1+ (1,0) [0|15] ""  PCM
 SG_ HandBrkSts : 50|2@1+ (1,0) [0|3] ""  PCM
 SG_ LckUnlckReqSrc : 48|2@1+ (1,0) [0|3] ""  PCM
 SG_ ParkBrkCmd : 43|2@1+ (1,0) [0|3] ""  PCM
 SG_ DevSts : 40|3@1+ (1,0) [0|7] ""  PCM
 SG_ KeyCylSts : 38|2@1+ (1,0) [0|3] ""  PCM
 SG_ OpenStsOfDoor7 : 36|2@1+ (1,0) [0|3] ""  PCM
 SG_ LckStsOfDoor7 : 34|2@1+ (1,0) [0|3] ""  PCM
 SG_ OpenStsOfDoor6 : 32|2@1+ (1,0) [0|3] ""  PCM
 SG_ OpenStsOfDoor5 : 30|2@1+ (1,0) [0|3] ""  PCM
 SG_ OpenStsOfDoor4 : 28|2@1+ (1,0) [0|3] ""  PCM
 SG_ OpenStsOfDoor3 : 26|2@1+ (1,0) [0|3] ""  PCM
 SG_ OpenStsOfDoor2 : 24|2@1+ (1,0) [0|3] ""  PCM
 SG_ OpenStsOfDoor1 : 22|2@1+ (1,0) [0|3] ""  PCM
 SG_ LckStsOfDoor5 : 20|2@1+ (1,0) [0|3] ""  PCM
 SG_ LckStsOfDoor4 : 18|2@1+ (1,0) [0|3] ""  PCM
 SG_ LckStsOfDoor3 : 16|2@1+ (1,0) [0|3] ""  PCM
 SG_ LckStsOfDoor2 : 14|2@1+ (1,0) [0|3] ""  PCM
 SG_ LckStsOfDoor1 : 12|2@1+ (1,0) [0|3] ""  PCM

CM_ SG_ 2566890251 ParkBrkSw "- 01 when the operator (or an external source) requests Park Brake activation
-  EPB Button Status";
CM_ SG_ 2566890251 ParkBrkRelsInhSts "- 01b when release is inhibited because Service Brake has not been applied";
CM_ SG_ 2566890251 ParkBrkActFullyActv_FFA30B "- EPB Status";
CM_ SG_ 2566887435 YawRate_FF980B "- Compensated Yaw Rate Value";
CM_ BO_ 2566897985 "- All log items always sent, for text only delimiter for if empty
-  Multipacket message handled by SAE Transport Protocol with Connection and Control Flow (J1939/21, par 5.10, with TP.CM RTS/CTS/EndOfMsgAck/Conn_Abor)
-  Sent at each Ignition on and after any log change. Retried up to 3 times, every 1s if not acknowledged (Transport Protocol EndOfMsgAck/).
-  Transport Protocol packets sent every 10ms
-  Variable Message Length, maximum value used for dbc generation";
CM_ SG_ 2566897985 CallLogIx10Txt "- Variable signal length, 8 bits used for dbc generation only";
CM_ SG_ 2566897985 CallLogIx9Txt "- Variable signal length, 8 bits used for dbc generation only";
CM_ SG_ 2566897985 CallLogIx8Txt "- Variable signal length, 8 bits used for dbc generation only";
CM_ SG_ 2566897985 CallLogIx7Txt "- Variable signal length, 8 bits used for dbc generation only";
CM_ SG_ 2566897985 CallLogIx6Txt "- Variable signal length, 8 bits used for dbc generation only";
CM_ SG_ 2566897985 CallLogIx5Txt "- Variable signal length, 8 bits used for dbc generation only";
CM_ SG_ 2566897985 CallLogIx4Txt "- Variable signal length, 8 bits used for dbc generation only";
CM_ SG_ 2566897985 CallLogIx3Txt "- Variable signal length, 8 bits used for dbc generation only";
CM_ SG_ 2566897985 CallLogIx2Txt "- Variable signal length, 8 bits used for dbc generation only";
CM_ SG_ 2566897985 CallLogIx1Txt "- Variable signal length, 8 bits used for dbc generation only";
CM_ SG_ 2566910273 DevName "- Variable signal length, 8 bits used for dbc generation only";
CM_ BO_ 2566865994 "- Multipacket message handled by SAE Transport Protocol (J1939/21, par 5.10, Multipacket Broadcast with TP.CM/BAM, TP.DT)";
CM_ BO_ 2365562112 "- 10 ms or 20 ms as calibration on MY24
-  Disabled as calibration on MY21";
CM_ BO_ 2583640359 "- Primary ePTO Data";
CM_ SG_ 2583640359 Crc8_FF3927 "- CRC only - No Data ID Applied";
CM_ SG_ 2583640359 PeakDevCur "- Primary ePTO";
CM_ SG_ 2583640359 LongDevCur "- Primary ePTO";
CM_ SG_ 2583640359 EptoWaitingMode "- Primary ePTO";
CM_ SG_ 2583640359 EngCons "- Primary ePTO";
CM_ SG_ 2583640359 OperativeEptoSts "- Primary ePTO";
CM_ SG_ 2583640359 MaxCurLim "- Primary ePTO";
CM_ SG_ 2583640359 MinSocLim "- Primary ePTO";
CM_ SG_ 2583640359 LowSocLim "- Primary ePTO";
CM_ SG_ 2583640359 MaxAllwPwr "- Primary ePTO";
CM_ SG_ 2583640359 ActPwr "- Primary ePTO";
CM_ BO_ 2583639079 "- Secondary ePTO Data";
CM_ SG_ 2583639079 OperativeEptoSts_FF3427 "- Secondary ePTO";
CM_ SG_ 2583639079 SecEptoEnergyCons "- Secondary ePTO";
CM_ SG_ 2583639079 ActPwr_FF3427 "- Secondary ePTO";
CM_ SG_ 2583655201 HandBrkSts "- Hand Brake + EPB Status";
CM_ SG_ 2583655201 LckUnlckReqSrc "- not used";
CM_ SG_ 2583655201 OpenStsOfDoor7 "- 6-th Door (not Used)";
CM_ SG_ 2583655201 LckStsOfDoor7 "- 6-th Door (not Used)";
CM_ SG_ 2583655201 OpenStsOfDoor6 "- Bonnet Door";
CM_ SG_ 2583655201 OpenStsOfDoor5 "- Hinged/Rear Door";
CM_ SG_ 2583655201 OpenStsOfDoor4 "- Lateral Door Passenger Side/Roto Door";
CM_ SG_ 2583655201 OpenStsOfDoor3 "- Lateral Door Driver Side";
CM_ SG_ 2583655201 OpenStsOfDoor2 "- Passenger Door";
CM_ SG_ 2583655201 OpenStsOfDoor1 "- Driver Door";
CM_ SG_ 2583655201 LckStsOfDoor5 "- Hinged/Rear Door";
CM_ SG_ 2583655201 LckStsOfDoor4 "- Lateral Door Passenger Side/Roto Door";
CM_ SG_ 2583655201 LckStsOfDoor3 "- Lateral Door Driver Side";
CM_ SG_ 2583655201 LckStsOfDoor2 "- Passenger Door";
CM_ SG_ 2583655201 LckStsOfDoor1 "- Driver Door";
BA_DEF_ BO_  "CI_MsgDefinition" STRING ;
BA_DEF_ BO_  "CI_MsgId" INT 0 2147483647;
BA_DEF_ BO_  "CI_MsgName" STRING ;
BA_DEF_ BO_  "GenMsgCycleTime" INT 0 3600000;
BA_DEF_ BO_  "GenMsgCycleTimeFast" INT 0 3600000;
BA_DEF_ BO_  "GenMsgDelayTime" INT 0 3600000;
BA_DEF_ BO_  "GenMsgILSupport" ENUM  "No","Yes";
BA_DEF_ BO_  "GenMsgNrOfRepetition" INT 0 1000000;
BA_DEF_ BO_  "GenMsgRequestable" INT 0 1;
BA_DEF_ BO_  "GenMsgSendType" ENUM  "cyclic","NotUsed","NotUsed","NotUsed","NotUsed","NotUsed","NotUsed","IfActive","noMsgSendType";
BA_DEF_ BO_  "GenMsgStartDelayTime" INT 0 100000;
BA_DEF_ BO_  "TpJ1939VarDlc" ENUM  "No","Yes";
BA_DEF_ BO_  "VFrameFormat" ENUM  "StandardCAN","ExtendedCAN","reserved","J1939PG";
BA_DEF_ SG_  "CI_ParId" STRING ;
BA_DEF_ SG_  "CI_SigId" INT 0 2147483647;
BA_DEF_ SG_  "CI_SigName" STRING ;
BA_DEF_ SG_  "GenSigEVName" STRING ;
BA_DEF_ SG_  "GenSigILSupport" ENUM  "No","Yes";
BA_DEF_ SG_  "GenSigInactiveValue" INT 0 2147483647;
BA_DEF_ SG_  "GenSigSendType" ENUM  "Cyclic","OnWrite","OnWriteWithRepetition","OnChange","OnChangeWithRepetition","IfActive","IfActiveWithRepetition","NoSigSendType";
BA_DEF_ SG_  "GenSigStartValue" INT 0 2147483647;
BA_DEF_ SG_  "GenSigTimeoutTime_PCM" INT 0 3600000;
BA_DEF_ SG_  "GenSigTimeoutTime_SGW" INT 0 3600000;
BA_DEF_ SG_  "SPN" INT 0 524287;
BA_DEF_ SG_  "SigType" ENUM  "Default","Range","RangeSigned","ASCII","Discrete","Control","ReferencePGN","DTC","StringDelimiter","StringLength","StringLengthControl";
BA_DEF_DEF_  "CI_MsgDefinition" "";
BA_DEF_DEF_  "CI_MsgId" 0;
BA_DEF_DEF_  "CI_MsgName" "";
BA_DEF_DEF_  "GenMsgCycleTime" 0;
BA_DEF_DEF_  "GenMsgCycleTimeFast" 0;
BA_DEF_DEF_  "GenMsgDelayTime" 1;
BA_DEF_DEF_  "GenMsgILSupport" "Yes";
BA_DEF_DEF_  "GenMsgNrOfRepetition" 0;
BA_DEF_DEF_  "GenMsgRequestable" 0;
BA_DEF_DEF_  "GenMsgSendType" "noMsgSendType";
BA_DEF_DEF_  "GenMsgStartDelayTime" 0;
BA_DEF_DEF_  "TpJ1939VarDlc" "No";
BA_DEF_DEF_  "VFrameFormat" "J1939PG";
BA_DEF_DEF_  "CI_ParId" "";
BA_DEF_DEF_  "CI_SigId" 0;
BA_DEF_DEF_  "CI_SigName" "";
BA_DEF_DEF_  "GenSigEVName" "Env@Nodename_@Signame";
BA_DEF_DEF_  "GenSigILSupport" "Yes";
BA_DEF_DEF_  "GenSigInactiveValue" 0;
BA_DEF_DEF_  "GenSigSendType" "NoSigSendType";
BA_DEF_DEF_  "GenSigStartValue" 0;
BA_DEF_DEF_  "GenSigTimeoutTime_PCM" 0;
BA_DEF_DEF_  "GenSigTimeoutTime_SGW" 0;
BA_DEF_DEF_  "SPN" 0;
BA_DEF_DEF_  "SigType" "Default";
BA_ "CI_MsgDefinition" BO_ 2566890251 "Iveco Proprietary";
BA_ "CI_MsgId" BO_ 2566890251 42742;
BA_ "CI_MsgName" BO_ 2566890251 "PB_BSMData_0B - Proprietary B - Braking System Module Data";
BA_ "GenMsgCycleTime" BO_ 2566890251 100;
BA_ "GenMsgCycleTimeFast" BO_ 2566890251 100;
BA_ "GenMsgDelayTime" BO_ 2566890251 20;
BA_ "GenMsgSendType" BO_ 2566890251 0;
BA_ "GenMsgStartDelayTime" BO_ 2566890251 82;
BA_ "CI_MsgDefinition" BO_ 2566887435 "Iveco Proprietary";
BA_ "CI_MsgId" BO_ 2566887435 42734;
BA_ "CI_MsgName" BO_ 2566887435 "PB_BSMInfo_0B - Proprietary B - Braking System Module Information";
BA_ "GenMsgCycleTime" BO_ 2566887435 20;
BA_ "GenMsgCycleTimeFast" BO_ 2566887435 20;
BA_ "GenMsgDelayTime" BO_ 2566887435 10;
BA_ "GenMsgSendType" BO_ 2566887435 0;
BA_ "GenMsgStartDelayTime" BO_ 2566887435 24;
BA_ "CI_MsgDefinition" BO_ 2566854382 "Continental Proprietary";
BA_ "CI_MsgId" BO_ 2566854382 45718;
BA_ "CI_MsgName" BO_ 2566854382 "PB_CabotageRelData_EE - Proprietary B - Cabotage Related Data";
BA_ "GenMsgCycleTime" BO_ 2566854382 60000;
BA_ "GenMsgCycleTimeFast" BO_ 2566854382 60000;
BA_ "GenMsgDelayTime" BO_ 2566854382 500;
BA_ "GenMsgSendType" BO_ 2566854382 0;
BA_ "GenMsgStartDelayTime" BO_ 2566854382 364;
BA_ "CI_MsgDefinition" BO_ 2566897985 "Iveco Proprietary";
BA_ "CI_MsgId" BO_ 2566897985 44865;
BA_ "CI_MsgName" BO_ 2566897985 "PB_CallLog_41 - Telephone Call Log";
BA_ "GenMsgDelayTime" BO_ 2566897985 1000;
BA_ "TpJ1939VarDlc" BO_ 2566897985 1;
BA_ "CI_MsgDefinition" BO_ 2566882327 "Iveco Proprietary";
BA_ "CI_MsgId" BO_ 2566882327 44592;
BA_ "CI_MsgName" BO_ 2566882327 "PB_CCT_17 - Proprietary B - Climate Control Timer";
BA_ "GenMsgDelayTime" BO_ 2566882327 100;
BA_ "CI_MsgDefinition" BO_ 2566882337 "Iveco Proprietary";
BA_ "CI_MsgId" BO_ 2566882337 8602;
BA_ "CI_MsgName" BO_ 2566882337 "PB_CCT_21 - Proprietary B - Climate Control Timer";
BA_ "GenMsgCycleTime" BO_ 2566882337 1000;
BA_ "GenMsgCycleTimeFast" BO_ 2566882337 1000;
BA_ "GenMsgDelayTime" BO_ 2566882337 100;
BA_ "GenMsgSendType" BO_ 2566882337 0;
BA_ "GenMsgStartDelayTime" BO_ 2566882337 255;
BA_ "CI_MsgDefinition" BO_ 2566882378 "Iveco Proprietary";
BA_ "CI_MsgId" BO_ 2566882378 43765;
BA_ "CI_MsgName" BO_ 2566882378 "PB_CCT_4A - Proprietary B - Climate Control Timer";
BA_ "GenMsgDelayTime" BO_ 2566882378 100;
BA_ "CI_MsgDefinition" BO_ 2583654960 "Iveco Daily";
BA_ "CI_MsgId" BO_ 2583654960 35141;
BA_ "CI_MsgName" BO_ 2583654960 "PB_CDCInfo_30 - Proprietary B - CDC Information";
BA_ "GenMsgCycleTime" BO_ 2583654960 10000;
BA_ "GenMsgCycleTimeFast" BO_ 2583654960 10000;
BA_ "GenMsgDelayTime" BO_ 2583654960 100;
BA_ "GenMsgSendType" BO_ 2583654960 0;
BA_ "GenMsgStartDelayTime" BO_ 2583654960 363;
BA_ "CI_MsgDefinition" BO_ 2566895393 "Iveco Daily Proprietary";
BA_ "CI_MsgId" BO_ 2566895393 42163;
BA_ "CI_MsgName" BO_ 2566895393 "PB_CFGInfo_21 - Proprietary B - Configuration Information";
BA_ "GenMsgCycleTime" BO_ 2566895393 2000;
BA_ "GenMsgCycleTimeFast" BO_ 2566895393 2000;
BA_ "GenMsgDelayTime" BO_ 2566895393 1000;
BA_ "GenMsgSendType" BO_ 2566895393 0;
BA_ "GenMsgStartDelayTime" BO_ 2566895393 331;
BA_ "CI_MsgDefinition" BO_ 2650777478 "Iveco Daily Electric";
BA_ "CI_MsgId" BO_ 2650777478 44131;
BA_ "CI_MsgName" BO_ 2650777478 "PB_CHGTC_86 - Proprietary B - CHG Time Counter";
BA_ "GenMsgCycleTime" BO_ 2650777478 600000;
BA_ "GenMsgCycleTimeFast" BO_ 2650777478 600000;
BA_ "GenMsgDelayTime" BO_ 2650777478 300000;
BA_ "GenMsgSendType" BO_ 2650777478 0;
BA_ "GenMsgStartDelayTime" BO_ 2650777478 392;
BA_ "CI_MsgDefinition" BO_ 2650777479 "Iveco Daily Electric";
BA_ "CI_MsgId" BO_ 2650777479 44142;
BA_ "CI_MsgName" BO_ 2650777479 "PB_CHGTC_87 - Proprietary B - CHG Time Counter";
BA_ "GenMsgCycleTime" BO_ 2650777479 600000;
BA_ "GenMsgCycleTimeFast" BO_ 2650777479 600000;
BA_ "GenMsgDelayTime" BO_ 2650777479 300000;
BA_ "GenMsgSendType" BO_ 2650777479 0;
BA_ "GenMsgStartDelayTime" BO_ 2650777479 393;
BA_ "CI_MsgDefinition" BO_ 2650777588 "Iveco Daily Electric";
BA_ "CI_MsgId" BO_ 2650777588 44098;
BA_ "CI_MsgName" BO_ 2650777588 "PB_CHGTC_F4 - Proprietary B - CHG Time Counter";
BA_ "GenMsgCycleTime" BO_ 2650777588 600000;
BA_ "GenMsgCycleTimeFast" BO_ 2650777588 600000;
BA_ "GenMsgDelayTime" BO_ 2650777588 300000;
BA_ "GenMsgSendType" BO_ 2650777588 0;
BA_ "GenMsgStartDelayTime" BO_ 2650777588 394;
BA_ "CI_MsgDefinition" BO_ 2650777589 "Iveco Daily Electric";
BA_ "CI_MsgId" BO_ 2650777589 44109;
BA_ "CI_MsgName" BO_ 2650777589 "PB_CHGTC_F5 - Proprietary B - CHG Time Counter";
BA_ "GenMsgCycleTime" BO_ 2650777589 600000;
BA_ "GenMsgCycleTimeFast" BO_ 2650777589 600000;
BA_ "GenMsgDelayTime" BO_ 2650777589 300000;
BA_ "GenMsgSendType" BO_ 2650777589 0;
BA_ "GenMsgStartDelayTime" BO_ 2650777589 395;
BA_ "CI_MsgDefinition" BO_ 2650777590 "Iveco Daily Electric";
BA_ "CI_MsgId" BO_ 2650777590 44120;
BA_ "CI_MsgName" BO_ 2650777590 "PB_CHGTC_F6 - Proprietary B - CHG Time Counter";
BA_ "GenMsgCycleTime" BO_ 2650777590 600000;
BA_ "GenMsgCycleTimeFast" BO_ 2650777590 600000;
BA_ "GenMsgDelayTime" BO_ 2650777590 300000;
BA_ "GenMsgSendType" BO_ 2650777590 0;
BA_ "GenMsgStartDelayTime" BO_ 2650777590 396;
BA_ "CI_MsgDefinition" BO_ 2583641895 "Iveco Daily Electric";
BA_ "CI_MsgId" BO_ 2583641895 39846;
BA_ "CI_MsgName" BO_ 2583641895 "PB_CTS_27 - Proprietary B - Coefficient Sensor Temperature";
BA_ "GenMsgCycleTime" BO_ 2583641895 1000;
BA_ "GenMsgCycleTimeFast" BO_ 2583641895 1000;
BA_ "GenMsgDelayTime" BO_ 2583641895 500;
BA_ "GenMsgSendType" BO_ 2583641895 0;
BA_ "GenMsgStartDelayTime" BO_ 2583641895 286;
BA_ "CI_MsgDefinition" BO_ 2566910273 "Iveco Proprietary";
BA_ "CI_MsgId" BO_ 2566910273 42152;
BA_ "CI_MsgName" BO_ 2566910273 "PB_DevInf_41 - Proprietary B - Device Information";
BA_ "GenMsgDelayTime" BO_ 2566910273 500;
BA_ "TpJ1939VarDlc" BO_ 2566910273 1;
BA_ "CI_MsgDefinition" BO_ 2566883879 "Iveco Proprietary";
BA_ "CI_MsgId" BO_ 2566883879 45734;
BA_ "CI_MsgName" BO_ 2566883879 "PB_DPD_27 - Proprietary B - Driver Profile Data";
BA_ "GenMsgCycleTime" BO_ 2566883879 2000;
BA_ "GenMsgCycleTimeFast" BO_ 2566883879 2000;
BA_ "GenMsgDelayTime" BO_ 2566883879 100;
BA_ "GenMsgSendType" BO_ 2566883879 0;
BA_ "GenMsgStartDelayTime" BO_ 2566883879 329;
BA_ "CI_MsgDefinition" BO_ 2566883914 "Iveco Proprietary";
BA_ "CI_MsgId" BO_ 2566883914 45713;
BA_ "CI_MsgName" BO_ 2566883914 "PB_DPD_4A - Proprietary B - Driver Profile Data";
BA_ "GenMsgDelayTime" BO_ 2566883914 100;
BA_ "CI_MsgDefinition" BO_ 2566849774 "Continental Proprietary";
BA_ "CI_MsgId" BO_ 2566849774 1776;
BA_ "CI_MsgName" BO_ 2566849774 "PB_DriversConsentOnPersonalData - DriversConsentOnPersonalData (Continental Proprietary)";
BA_ "CI_MsgDefinition" BO_ 2566865994 "Iveco Proprietary";
BA_ "CI_MsgId" BO_ 2566865994 4921;
BA_ "CI_MsgName" BO_ 2566865994 "PB_Dse_4A - Proprietary B - Driving Style Evaluation";
BA_ "GenMsgCycleTimeFast" BO_ 2566865994 10000;
BA_ "GenMsgDelayTime" BO_ 2566865994 1000;
BA_ "GenMsgSendType" BO_ 2566865994 0;
BA_ "GenMsgStartDelayTime" BO_ 2566865994 44;
BA_ "TpJ1939VarDlc" BO_ 2566865994 1;
BA_ "CI_MsgDefinition" BO_ 2583650122 "Iveco Daily Electric";
BA_ "CI_MsgId" BO_ 2583650122 39150;
BA_ "CI_MsgName" BO_ 2583650122 "PB_DSE_ENERGY_4A - Proprietary B - Driving Style Evaluation ENERGY";
BA_ "GenMsgCycleTimeFast" BO_ 2583650122 1000;
BA_ "GenMsgDelayTime" BO_ 2583650122 500;
BA_ "GenMsgSendType" BO_ 2583650122 0;
BA_ "GenMsgStartDelayTime" BO_ 2583650122 32;
BA_ "CI_MsgDefinition" BO_ 2566895690 "Iveco Proprietary";
BA_ "CI_MsgId" BO_ 2566895690 4973;
BA_ "CI_MsgName" BO_ 2566895690 "PB_DseStart_4A - Proprietary B - DSE Start";
BA_ "GenMsgCycleTimeFast" BO_ 2566895690 1000;
BA_ "GenMsgDelayTime" BO_ 2566895690 500;
BA_ "GenMsgStartDelayTime" BO_ 2566895690 26;
BA_ "CI_MsgDefinition" BO_ 2566895946 "Iveco Proprietary";
BA_ "CI_MsgId" BO_ 2566895946 4968;
BA_ "CI_MsgName" BO_ 2566895946 "PB_DseStatus_4A - Proprietary B - DSE Status";
BA_ "GenMsgCycleTimeFast" BO_ 2566895946 1000;
BA_ "GenMsgDelayTime" BO_ 2566895946 500;
BA_ "GenMsgStartDelayTime" BO_ 2566895946 28;
BA_ "CI_MsgDefinition" BO_ 2650777222 "Iveco Daily Electric";
BA_ "CI_MsgId" BO_ 2650777222 44076;
BA_ "CI_MsgName" BO_ 2650777222 "PB_DSGTC_86 - Proprietary B - DSG Time Counter";
BA_ "GenMsgCycleTime" BO_ 2650777222 600000;
BA_ "GenMsgCycleTimeFast" BO_ 2650777222 600000;
BA_ "GenMsgDelayTime" BO_ 2650777222 300000;
BA_ "GenMsgSendType" BO_ 2650777222 0;
BA_ "GenMsgStartDelayTime" BO_ 2650777222 386;
BA_ "CI_MsgDefinition" BO_ 2650777223 "Iveco Daily Electric";
BA_ "CI_MsgId" BO_ 2650777223 44087;
BA_ "CI_MsgName" BO_ 2650777223 "PB_DSGTC_87 - Proprietary B - DSG Time Counter";
BA_ "GenMsgCycleTime" BO_ 2650777223 600000;
BA_ "GenMsgCycleTimeFast" BO_ 2650777223 600000;
BA_ "GenMsgDelayTime" BO_ 2650777223 300000;
BA_ "GenMsgSendType" BO_ 2650777223 0;
BA_ "GenMsgStartDelayTime" BO_ 2650777223 387;
BA_ "CI_MsgDefinition" BO_ 2650777332 "Iveco Daily Electric";
BA_ "CI_MsgId" BO_ 2650777332 44043;
BA_ "CI_MsgName" BO_ 2650777332 "PB_DSGTC_F4 - Proprietary B - DSG Time Counter";
BA_ "GenMsgCycleTime" BO_ 2650777332 600000;
BA_ "GenMsgCycleTimeFast" BO_ 2650777332 600000;
BA_ "GenMsgDelayTime" BO_ 2650777332 300000;
BA_ "GenMsgSendType" BO_ 2650777332 0;
BA_ "GenMsgStartDelayTime" BO_ 2650777332 388;
BA_ "CI_MsgDefinition" BO_ 2650777333 "Iveco Daily Electric";
BA_ "CI_MsgId" BO_ 2650777333 44054;
BA_ "CI_MsgName" BO_ 2650777333 "PB_DSGTC_F5 - Proprietary B - DSG Time Counter";
BA_ "GenMsgCycleTime" BO_ 2650777333 600000;
BA_ "GenMsgCycleTimeFast" BO_ 2650777333 600000;
BA_ "GenMsgDelayTime" BO_ 2650777333 300000;
BA_ "GenMsgSendType" BO_ 2650777333 0;
BA_ "GenMsgStartDelayTime" BO_ 2650777333 389;
BA_ "CI_MsgDefinition" BO_ 2650777334 "Iveco Daily Electric";
BA_ "CI_MsgId" BO_ 2650777334 44065;
BA_ "CI_MsgName" BO_ 2650777334 "PB_DSGTC_F6 - Proprietary B - DSG Time Counter";
BA_ "GenMsgCycleTime" BO_ 2650777334 600000;
BA_ "GenMsgCycleTimeFast" BO_ 2650777334 600000;
BA_ "GenMsgDelayTime" BO_ 2650777334 300000;
BA_ "GenMsgSendType" BO_ 2650777334 0;
BA_ "GenMsgStartDelayTime" BO_ 2650777334 391;
BA_ "CI_MsgDefinition" BO_ 2365562112 "Iveco Proprietary";
BA_ "CI_MsgId" BO_ 2365562112 39852;
BA_ "CI_MsgName" BO_ 2365562112 "PB_EcmData_00 - Proprietary B - Ecm Data";
BA_ "GenMsgCycleTime" BO_ 2365562112 10;
BA_ "GenMsgCycleTimeFast" BO_ 2365562112 10;
BA_ "GenMsgDelayTime" BO_ 2365562112 5;
BA_ "GenMsgSendType" BO_ 2365562112 0;
BA_ "GenMsgStartDelayTime" BO_ 2365562112 6;
BA_ "CI_MsgDefinition" BO_ 2566865482 "Iveco Proprietary";
BA_ "CI_MsgId" BO_ 2566865482 4915;
BA_ "CI_MsgName" BO_ 2566865482 "PB_EcuSw_4A - Proprietary B - ECU Software Information";
BA_ "GenMsgCycleTime" BO_ 2566865482 10000;
BA_ "GenMsgCycleTimeFast" BO_ 2566865482 10000;
BA_ "GenMsgDelayTime" BO_ 2566865482 1000;
BA_ "GenMsgSendType" BO_ 2566865482 0;
BA_ "GenMsgStartDelayTime" BO_ 2566865482 42;
BA_ "CI_MsgDefinition" BO_ 2583638311 "Iveco Daily Electric";
BA_ "CI_MsgId" BO_ 2583638311 41811;
BA_ "CI_MsgName" BO_ 2583638311 "PB_ED1_27 - Proprietary B - Energy Data 1";
BA_ "GenMsgCycleTime" BO_ 2583638311 10000;
BA_ "GenMsgCycleTimeFast" BO_ 2583638311 10000;
BA_ "GenMsgDelayTime" BO_ 2583638311 5000;
BA_ "GenMsgSendType" BO_ 2583638311 0;
BA_ "GenMsgStartDelayTime" BO_ 2583638311 357;
BA_ "CI_MsgDefinition" BO_ 2583638567 "Iveco Daily Electric";
BA_ "CI_MsgId" BO_ 2583638567 41814;
BA_ "CI_MsgName" BO_ 2583638567 "PB_ED2_27 - Proprietary B - Energy Data 2";
BA_ "GenMsgCycleTime" BO_ 2583638567 10000;
BA_ "GenMsgCycleTimeFast" BO_ 2583638567 10000;
BA_ "GenMsgDelayTime" BO_ 2583638567 5000;
BA_ "GenMsgSendType" BO_ 2583638567 0;
BA_ "GenMsgStartDelayTime" BO_ 2583638567 358;
BA_ "CI_MsgDefinition" BO_ 2365572627 "Iveco Daily Proprietary";
BA_ "CI_MsgId" BO_ 2365572627 42157;
BA_ "CI_MsgName" BO_ 2365572627 "PB_EPSData_13 - Proprietary B - Electronic Power Steering Data";
BA_ "GenMsgCycleTime" BO_ 2365572627 10;
BA_ "GenMsgCycleTimeFast" BO_ 2365572627 10;
BA_ "GenMsgDelayTime" BO_ 2365572627 5;
BA_ "GenMsgSendType" BO_ 2365572627 0;
BA_ "GenMsgStartDelayTime" BO_ 2365572627 8;
BA_ "CI_MsgDefinition" BO_ 2566852883 "Iveco Proprietary";
BA_ "CI_MsgId" BO_ 2566852883 43734;
BA_ "CI_MsgName" BO_ 2566852883 "PB_EpsInfo - Proprietary B - Electronic Power Steering Info";
BA_ "GenMsgCycleTime" BO_ 2566852883 50;
BA_ "GenMsgCycleTimeFast" BO_ 2566852883 50;
BA_ "GenMsgDelayTime" BO_ 2566852883 25;
BA_ "GenMsgSendType" BO_ 2566852883 0;
BA_ "GenMsgStartDelayTime" BO_ 2566852883 43;
BA_ "CI_MsgDefinition" BO_ 2583640359 "Iveco Daily Electric";
BA_ "CI_MsgId" BO_ 2583640359 45659;
BA_ "CI_MsgName" BO_ 2583640359 "PB_ePTOSts1_27 - Proprietary B - ePTO Status 1";
BA_ "GenMsgCycleTime" BO_ 2583640359 250;
BA_ "GenMsgCycleTimeFast" BO_ 2583640359 250;
BA_ "GenMsgDelayTime" BO_ 2583640359 125;
BA_ "GenMsgSendType" BO_ 2583640359 0;
BA_ "GenMsgStartDelayTime" BO_ 2583640359 121;
BA_ "CI_MsgDefinition" BO_ 2583639079 "Iveco Daily Electric";
BA_ "CI_MsgId" BO_ 2583639079 45660;
BA_ "CI_MsgName" BO_ 2583639079 "PB_ePTOSts2_27 - Proprietary B - ePTO Status 2";
BA_ "GenMsgCycleTime" BO_ 2583639079 250;
BA_ "GenMsgCycleTimeFast" BO_ 2583639079 250;
BA_ "GenMsgDelayTime" BO_ 2583639079 125;
BA_ "GenMsgSendType" BO_ 2583639079 0;
BA_ "GenMsgStartDelayTime" BO_ 2583639079 119;
BA_ "CI_MsgDefinition" BO_ 2566893315 "Iveco Proprietary";
BA_ "CI_MsgId" BO_ 2566893315 33409;
BA_ "CI_MsgName" BO_ 2566893315 "PB_EtcInfo_03 - Proprietary B - ETC Information";
BA_ "GenMsgCycleTime" BO_ 2566893315 100;
BA_ "GenMsgCycleTimeFast" BO_ 2566893315 100;
BA_ "GenMsgDelayTime" BO_ 2566893315 50;
BA_ "GenMsgSendType" BO_ 2566893315 0;
BA_ "GenMsgStartDelayTime" BO_ 2566893315 84;
BA_ "CI_MsgDefinition" BO_ 2566894119 "Iveco Proprietary";
BA_ "CI_MsgId" BO_ 2566894119 4065;
BA_ "CI_MsgName" BO_ 2566894119 "PB_EVR_27 - Electric Vehicle Range";
BA_ "GenMsgCycleTime" BO_ 2566894119 1000;
BA_ "GenMsgCycleTimeFast" BO_ 2566894119 1000;
BA_ "GenMsgDelayTime" BO_ 2566894119 100;
BA_ "GenMsgSendType" BO_ 2566894119 0;
BA_ "GenMsgStartDelayTime" BO_ 2566894119 263;
BA_ "CI_MsgDefinition" BO_ 2566886730 "Iveco Proprietary";
BA_ "CI_MsgId" BO_ 2566886730 44527;
BA_ "CI_MsgName" BO_ 2566886730 "PB_FMRS_4A - Proprietary B - Fleet Manager Remote Settings";
BA_ "GenMsgDelayTime" BO_ 2566886730 100;
BA_ "CI_MsgDefinition" BO_ 2566886935 "Iveco Proprietary";
BA_ "CI_MsgId" BO_ 2566886935 44548;
BA_ "CI_MsgName" BO_ 2566886935 "PB_FMRSF_17 - Proprietary B - Fleet Manager Remote Settings Feedback";
BA_ "GenMsgCycleTime" BO_ 2566886935 1000;
BA_ "GenMsgCycleTimeFast" BO_ 2566886935 1000;
BA_ "GenMsgDelayTime" BO_ 2566886935 100;
BA_ "GenMsgSendType" BO_ 2566886935 0;
BA_ "GenMsgStartDelayTime" BO_ 2566886935 257;
BA_ "CI_MsgDefinition" BO_ 2583655201 "Iveco Daily";
BA_ "CI_MsgId" BO_ 2583655201 41937;
BA_ "CI_MsgName" BO_ 2583655201 "PB_GenCtrl_21 - Proprietary B - Generic Controls";
BA_ "GenMsgCycleTime" BO_ 2583655201 100;
BA_ "GenMsgCycleTimeFast" BO_ 2583655201 100;
BA_ "GenMsgDelayTime" BO_ 2583655201 50;
BA_ "GenMsgSendType" BO_ 2583655201 0;
BA_ "GenMsgStartDelayTime" BO_ 2583655201 95;
BA_ "CI_ParId" SG_ 2566890251 VehSpeedRear "ID2306";
BA_ "CI_SigId" SG_ 2566890251 VehSpeedRear 42761;
BA_ "CI_SigName" SG_ 2566890251 VehSpeedRear "Vehicle Speed Rear";
BA_ "GenSigSendType" SG_ 2566890251 VehSpeedRear 3;
BA_ "GenSigTimeoutTime_PCM" SG_ 2566890251 VehSpeedRear 500;
BA_ "SigType" SG_ 2566890251 VehSpeedRear 1;
BA_ "CI_ParId" SG_ 2566890251 BsmRctbFail "ID2431";
BA_ "CI_SigId" SG_ 2566890251 BsmRctbFail 44426;
BA_ "CI_SigName" SG_ 2566890251 BsmRctbFail "BSM RCTB Failure Status";
BA_ "GenSigSendType" SG_ 2566890251 BsmRctbFail 3;
BA_ "GenSigTimeoutTime_PCM" SG_ 2566890251 BsmRctbFail 500;
BA_ "SigType" SG_ 2566890251 BsmRctbFail 4;
BA_ "CI_ParId" SG_ 2566890251 BsmAebFail "ID2430";
BA_ "CI_SigId" SG_ 2566890251 BsmAebFail 44425;
BA_ "CI_SigName" SG_ 2566890251 BsmAebFail "BSM AEB Failure Status";
BA_ "GenSigSendType" SG_ 2566890251 BsmAebFail 3;
BA_ "GenSigTimeoutTime_PCM" SG_ 2566890251 BsmAebFail 500;
BA_ "SigType" SG_ 2566890251 BsmAebFail 4;
BA_ "CI_ParId" SG_ 2566890251 BsmBtnSts "ID2383";
BA_ "CI_SigId" SG_ 2566890251 BsmBtnSts 42760;
BA_ "CI_SigName" SG_ 2566890251 BsmBtnSts "BSM Button Status";
BA_ "GenSigSendType" SG_ 2566890251 BsmBtnSts 3;
BA_ "GenSigTimeoutTime_PCM" SG_ 2566890251 BsmBtnSts 500;
BA_ "CI_ParId" SG_ 2566890251 RollerbenchActvSts "ID2307";
BA_ "CI_SigId" SG_ 2566890251 RollerbenchActvSts 42759;
BA_ "CI_SigName" SG_ 2566890251 RollerbenchActvSts "RollerBench Active Status";
BA_ "GenSigSendType" SG_ 2566890251 RollerbenchActvSts 3;
BA_ "GenSigTimeoutTime_PCM" SG_ 2566890251 RollerbenchActvSts 500;
BA_ "SigType" SG_ 2566890251 RollerbenchActvSts 4;
BA_ "CI_ParId" SG_ 2566890251 HbaSts "ID2382";
BA_ "CI_SigId" SG_ 2566890251 HbaSts 42758;
BA_ "CI_SigName" SG_ 2566890251 HbaSts "HBA Status";
BA_ "GenSigSendType" SG_ 2566890251 HbaSts 3;
BA_ "GenSigTimeoutTime_PCM" SG_ 2566890251 HbaSts 500;
BA_ "SigType" SG_ 2566890251 HbaSts 4;
BA_ "CI_ParId" SG_ 2566890251 CwaSts "ID2381";
BA_ "CI_SigId" SG_ 2566890251 CwaSts 42757;
BA_ "CI_SigName" SG_ 2566890251 CwaSts "CWA Status";
BA_ "GenSigSendType" SG_ 2566890251 CwaSts 3;
BA_ "GenSigTimeoutTime_PCM" SG_ 2566890251 CwaSts 500;
BA_ "SigType" SG_ 2566890251 CwaSts 4;
BA_ "CI_ParId" SG_ 2566890251 MsrSts "ID2380";
BA_ "CI_SigId" SG_ 2566890251 MsrSts 42756;
BA_ "CI_SigName" SG_ 2566890251 MsrSts "MSR Status";
BA_ "GenSigSendType" SG_ 2566890251 MsrSts 3;
BA_ "GenSigTimeoutTime_PCM" SG_ 2566890251 MsrSts 500;
BA_ "SigType" SG_ 2566890251 MsrSts 4;
BA_ "CI_ParId" SG_ 2566890251 HhSts "ID2379";
BA_ "CI_SigId" SG_ 2566890251 HhSts 42755;
BA_ "CI_SigName" SG_ 2566890251 HhSts "Hill Holder Status";
BA_ "GenSigSendType" SG_ 2566890251 HhSts 3;
BA_ "GenSigTimeoutTime_PCM" SG_ 2566890251 HhSts 500;
BA_ "SigType" SG_ 2566890251 HhSts 4;
BA_ "CI_ParId" SG_ 2566890251 VdcSts "ID2378";
BA_ "CI_SigId" SG_ 2566890251 VdcSts 42754;
BA_ "CI_SigName" SG_ 2566890251 VdcSts "VDC Status";
BA_ "GenSigSendType" SG_ 2566890251 VdcSts 3;
BA_ "GenSigTimeoutTime_PCM" SG_ 2566890251 VdcSts 500;
BA_ "SigType" SG_ 2566890251 VdcSts 4;
BA_ "CI_ParId" SG_ 2566890251 AsrSts "ID2377";
BA_ "CI_SigId" SG_ 2566890251 AsrSts 42753;
BA_ "CI_SigName" SG_ 2566890251 AsrSts "ASR Status";
BA_ "GenSigSendType" SG_ 2566890251 AsrSts 3;
BA_ "GenSigTimeoutTime_PCM" SG_ 2566890251 AsrSts 500;
BA_ "SigType" SG_ 2566890251 AsrSts 4;
BA_ "CI_ParId" SG_ 2566890251 AbsSts "ID2376";
BA_ "CI_SigId" SG_ 2566890251 AbsSts 42752;
BA_ "CI_SigName" SG_ 2566890251 AbsSts "ABS Status";
BA_ "GenSigSendType" SG_ 2566890251 AbsSts 3;
BA_ "GenSigTimeoutTime_PCM" SG_ 2566890251 AbsSts 500;
BA_ "SigType" SG_ 2566890251 AbsSts 4;
BA_ "CI_ParId" SG_ 2566890251 EbdSts "ID2375";
BA_ "CI_SigId" SG_ 2566890251 EbdSts 42751;
BA_ "CI_SigName" SG_ 2566890251 EbdSts "EBD Status";
BA_ "GenSigSendType" SG_ 2566890251 EbdSts 3;
BA_ "GenSigTimeoutTime_PCM" SG_ 2566890251 EbdSts 500;
BA_ "SigType" SG_ 2566890251 EbdSts 4;
BA_ "CI_ParId" SG_ 2566890251 Hdc "I398";
BA_ "CI_SigId" SG_ 2566890251 Hdc 42749;
BA_ "CI_SigName" SG_ 2566890251 Hdc "Hill Descent Control";
BA_ "GenSigSendType" SG_ 2566890251 Hdc 3;
BA_ "GenSigTimeoutTime_PCM" SG_ 2566890251 Hdc 500;
BA_ "CI_ParId" SG_ 2566890251 BrkSig "I809";
BA_ "CI_SigId" SG_ 2566890251 BrkSig 42748;
BA_ "CI_SigName" SG_ 2566890251 BrkSig "Brake Signal";
BA_ "GenSigSendType" SG_ 2566890251 BrkSig 3;
BA_ "GenSigTimeoutTime_PCM" SG_ 2566890251 BrkSig 500;
BA_ "SigType" SG_ 2566890251 BrkSig 4;
BA_ "CI_ParId" SG_ 2566890251 VehSoftStop "I255";
BA_ "CI_SigId" SG_ 2566890251 VehSoftStop 42747;
BA_ "CI_SigName" SG_ 2566890251 VehSoftStop "Vehicle Soft Stop";
BA_ "GenSigSendType" SG_ 2566890251 VehSoftStop 3;
BA_ "GenSigTimeoutTime_PCM" SG_ 2566890251 VehSoftStop 500;
BA_ "SigType" SG_ 2566890251 VehSoftStop 4;
BA_ "CI_ParId" SG_ 2566890251 Eol "ID0308";
BA_ "CI_SigId" SG_ 2566890251 Eol 42750;
BA_ "CI_SigName" SG_ 2566890251 Eol "EOL";
BA_ "GenSigSendType" SG_ 2566890251 Eol 3;
BA_ "GenSigTimeoutTime_PCM" SG_ 2566890251 Eol 500;
BA_ "CI_ParId" SG_ 2566890251 VehMov "I185";
BA_ "CI_SigId" SG_ 2566890251 VehMov 42746;
BA_ "CI_SigName" SG_ 2566890251 VehMov "Vehicle Moving";
BA_ "GenSigSendType" SG_ 2566890251 VehMov 3;
BA_ "GenSigTimeoutTime_PCM" SG_ 2566890251 VehMov 500;
BA_ "SigType" SG_ 2566890251 VehMov 4;
BA_ "CI_ParId" SG_ 2566890251 ParkBrkSw "70";
BA_ "CI_SigId" SG_ 2566890251 ParkBrkSw 42745;
BA_ "CI_SigName" SG_ 2566890251 ParkBrkSw "Parking Brake Switch";
BA_ "GenSigSendType" SG_ 2566890251 ParkBrkSw 3;
BA_ "GenSigTimeoutTime_PCM" SG_ 2566890251 ParkBrkSw 500;
BA_ "SPN" SG_ 2566890251 ParkBrkSw 70;
BA_ "SigType" SG_ 2566890251 ParkBrkSw 4;
BA_ "CI_ParId" SG_ 2566890251 ParkBrkRelsInhSts "3808";
BA_ "CI_SigId" SG_ 2566890251 ParkBrkRelsInhSts 42744;
BA_ "CI_SigName" SG_ 2566890251 ParkBrkRelsInhSts "Park Brake Release Inhibit Status";
BA_ "GenSigSendType" SG_ 2566890251 ParkBrkRelsInhSts 3;
BA_ "GenSigTimeoutTime_PCM" SG_ 2566890251 ParkBrkRelsInhSts 500;
BA_ "SPN" SG_ 2566890251 ParkBrkRelsInhSts 3808;
BA_ "SigType" SG_ 2566890251 ParkBrkRelsInhSts 4;
BA_ "CI_ParId" SG_ 2566890251 ParkBrkAct "619";
BA_ "CI_SigId" SG_ 2566890251 ParkBrkAct 42743;
BA_ "CI_SigName" SG_ 2566890251 ParkBrkAct "Parking Brake Actuator";
BA_ "GenSigSendType" SG_ 2566890251 ParkBrkAct 3;
BA_ "GenSigTimeoutTime_PCM" SG_ 2566890251 ParkBrkAct 500;
BA_ "SPN" SG_ 2566890251 ParkBrkAct 619;
BA_ "SigType" SG_ 2566890251 ParkBrkAct 4;
BA_ "CI_ParId" SG_ 2566890251 XbrSysSts_FFA30B "2917";
BA_ "CI_SigId" SG_ 2566890251 XbrSysSts_FFA30B 44311;
BA_ "CI_SigName" SG_ 2566890251 XbrSysSts_FFA30B "XBR System State";
BA_ "GenSigSendType" SG_ 2566890251 XbrSysSts_FFA30B 3;
BA_ "GenSigTimeoutTime_PCM" SG_ 2566890251 XbrSysSts_FFA30B 500;
BA_ "SPN" SG_ 2566890251 XbrSysSts_FFA30B 2917;
BA_ "SigType" SG_ 2566890251 XbrSysSts_FFA30B 4;
BA_ "CI_ParId" SG_ 2566890251 ParkBrkActFullyActv_FFA30B "5275";
BA_ "CI_SigId" SG_ 2566890251 ParkBrkActFullyActv_FFA30B 44310;
BA_ "CI_SigName" SG_ 2566890251 ParkBrkActFullyActv_FFA30B "Parking Brake Actuator Fully Activated";
BA_ "GenSigSendType" SG_ 2566890251 ParkBrkActFullyActv_FFA30B 3;
BA_ "GenSigTimeoutTime_PCM" SG_ 2566890251 ParkBrkActFullyActv_FFA30B 500;
BA_ "SPN" SG_ 2566890251 ParkBrkActFullyActv_FFA30B 5275;
BA_ "SigType" SG_ 2566890251 ParkBrkActFullyActv_FFA30B 4;
BA_ "CI_ParId" SG_ 2566887435 VirtBrkPedPos "ID2314";
BA_ "CI_SigId" SG_ 2566887435 VirtBrkPedPos 42791;
BA_ "CI_SigName" SG_ 2566887435 VirtBrkPedPos "Virtual Brake Pedal Position";
BA_ "GenSigTimeoutTime_PCM" SG_ 2566887435 VirtBrkPedPos 500;
BA_ "SigType" SG_ 2566887435 VirtBrkPedPos 1;
BA_ "CI_ParId" SG_ 2566887435 YawRate_FF980B "1808";
BA_ "CI_SigId" SG_ 2566887435 YawRate_FF980B 42739;
BA_ "CI_SigName" SG_ 2566887435 YawRate_FF980B "Yaw Rate";
BA_ "GenSigTimeoutTime_PCM" SG_ 2566887435 YawRate_FF980B 500;
BA_ "SPN" SG_ 2566887435 YawRate_FF980B 1808;
BA_ "SigType" SG_ 2566887435 YawRate_FF980B 1;
BA_ "CI_ParId" SG_ 2566887435 LongAccel "1810";
BA_ "CI_SigId" SG_ 2566887435 LongAccel 42738;
BA_ "CI_SigName" SG_ 2566887435 LongAccel "Longitudinal Acceleration";
BA_ "GenSigTimeoutTime_PCM" SG_ 2566887435 LongAccel 500;
BA_ "SPN" SG_ 2566887435 LongAccel 1810;
BA_ "SigType" SG_ 2566887435 LongAccel 1;
BA_ "CI_ParId" SG_ 2566887435 LatAccel "1809";
BA_ "CI_SigId" SG_ 2566887435 LatAccel 42737;
BA_ "CI_SigName" SG_ 2566887435 LatAccel "Lateral Acceleration";
BA_ "GenSigTimeoutTime_PCM" SG_ 2566887435 LatAccel 500;
BA_ "SPN" SG_ 2566887435 LatAccel 1809;
BA_ "SigType" SG_ 2566887435 LatAccel 1;
BA_ "CI_ParId" SG_ 2566887435 EpbBtnRawSts "ID2555";
BA_ "CI_SigId" SG_ 2566887435 EpbBtnRawSts 45122;
BA_ "CI_SigName" SG_ 2566887435 EpbBtnRawSts "EPB Button Raw Status";
BA_ "GenSigTimeoutTime_PCM" SG_ 2566887435 EpbBtnRawSts 500;
BA_ "CI_ParId" SG_ 2566854382 LoadType "V576";
BA_ "CI_SigId" SG_ 2566854382 LoadType 45733;
BA_ "CI_SigName" SG_ 2566854382 LoadType "Load Type";
BA_ "GenSigSendType" SG_ 2566854382 LoadType 3;
BA_ "GenSigTimeoutTime_PCM" SG_ 2566854382 LoadType 300000;
BA_ "CI_ParId" SG_ 2566854382 LastOpPlaceRecAuthenticationSts "V575";
BA_ "CI_SigId" SG_ 2566854382 LastOpPlaceRecAuthenticationSts 45732;
BA_ "CI_SigName" SG_ 2566854382 LastOpPlaceRecAuthenticationSts "Last Operation Place Record - Authentication Status";
BA_ "GenSigSendType" SG_ 2566854382 LastOpPlaceRecAuthenticationSts 3;
BA_ "GenSigTimeoutTime_PCM" SG_ 2566854382 LastOpPlaceRecAuthenticationSts 300000;
BA_ "CI_ParId" SG_ 2566854382 LastOpPlaceRecLong "V574";
BA_ "CI_SigId" SG_ 2566854382 LastOpPlaceRecLong 45731;
BA_ "CI_SigName" SG_ 2566854382 LastOpPlaceRecLong "Last Operation Place Record - Longitude";
BA_ "GenSigSendType" SG_ 2566854382 LastOpPlaceRecLong 3;
BA_ "GenSigTimeoutTime_PCM" SG_ 2566854382 LastOpPlaceRecLong 300000;
BA_ "CI_ParId" SG_ 2566854382 LastOpPlaceRecLat "V573";
BA_ "CI_SigId" SG_ 2566854382 LastOpPlaceRecLat 45730;
BA_ "CI_SigName" SG_ 2566854382 LastOpPlaceRecLat "Last Operation Place Record - Latitude";
BA_ "GenSigSendType" SG_ 2566854382 LastOpPlaceRecLat 3;
BA_ "GenSigTimeoutTime_PCM" SG_ 2566854382 LastOpPlaceRecLat 300000;
BA_ "CI_ParId" SG_ 2566854382 LastOpPlaceRecGnssAccur "V572";
BA_ "CI_SigId" SG_ 2566854382 LastOpPlaceRecGnssAccur 45729;
BA_ "CI_SigName" SG_ 2566854382 LastOpPlaceRecGnssAccur "Last Operation Place Record - GNSS Accuracy";
BA_ "GenSigSendType" SG_ 2566854382 LastOpPlaceRecGnssAccur 3;
BA_ "GenSigStartValue" SG_ 2566854382 LastOpPlaceRecGnssAccur 1;
BA_ "GenSigTimeoutTime_PCM" SG_ 2566854382 LastOpPlaceRecGnssAccur 300000;
BA_ "CI_ParId" SG_ 2566854382 LastOpPlaceRecTs "V571";
BA_ "CI_SigId" SG_ 2566854382 LastOpPlaceRecTs 45728;
BA_ "CI_SigName" SG_ 2566854382 LastOpPlaceRecTs "Last Operation Place Record - Timestamp";
BA_ "GenSigSendType" SG_ 2566854382 LastOpPlaceRecTs 3;
BA_ "GenSigTimeoutTime_PCM" SG_ 2566854382 LastOpPlaceRecTs 300000;
BA_ "SigType" SG_ 2566854382 LastOpPlaceRecTs 1;
BA_ "CI_ParId" SG_ 2566854382 LastOpType "V570";
BA_ "CI_SigId" SG_ 2566854382 LastOpType 45727;
BA_ "CI_SigName" SG_ 2566854382 LastOpType "Last Operation Type";
BA_ "GenSigSendType" SG_ 2566854382 LastOpType 3;
BA_ "GenSigTimeoutTime_PCM" SG_ 2566854382 LastOpType 300000;
BA_ "CI_ParId" SG_ 2566854382 LastOpTimeStamp "V569";
BA_ "CI_SigId" SG_ 2566854382 LastOpTimeStamp 45726;
BA_ "CI_SigName" SG_ 2566854382 LastOpTimeStamp "Last Operation Time Stamp";
BA_ "GenSigSendType" SG_ 2566854382 LastOpTimeStamp 3;
BA_ "GenSigTimeoutTime_PCM" SG_ 2566854382 LastOpTimeStamp 300000;
BA_ "SigType" SG_ 2566854382 LastOpTimeStamp 1;
BA_ "CI_ParId" SG_ 2566854382 LastBorderCrossingPlaceRecAuthen "V568";
BA_ "CI_SigId" SG_ 2566854382 LastBorderCrossingPlaceRecAuthen 45725;
BA_ "CI_SigName" SG_ 2566854382 LastBorderCrossingPlaceRecAuthen "Last Border Crossing Place Record - Authentication Status";
BA_ "GenSigSendType" SG_ 2566854382 LastBorderCrossingPlaceRecAuthen 3;
BA_ "GenSigTimeoutTime_PCM" SG_ 2566854382 LastBorderCrossingPlaceRecAuthen 300000;
BA_ "CI_ParId" SG_ 2566854382 LastBorderCrossingPlaceRecLong "V567";
BA_ "CI_SigId" SG_ 2566854382 LastBorderCrossingPlaceRecLong 45724;
BA_ "CI_SigName" SG_ 2566854382 LastBorderCrossingPlaceRecLong "Last Border Crossing Place Record - Longitude";
BA_ "GenSigSendType" SG_ 2566854382 LastBorderCrossingPlaceRecLong 3;
BA_ "GenSigTimeoutTime_PCM" SG_ 2566854382 LastBorderCrossingPlaceRecLong 300000;
BA_ "CI_ParId" SG_ 2566854382 LastBorderCrossingPlaceRecLat "V566";
BA_ "CI_SigId" SG_ 2566854382 LastBorderCrossingPlaceRecLat 45723;
BA_ "CI_SigName" SG_ 2566854382 LastBorderCrossingPlaceRecLat "Last Border Crossing Place Record - Latitude";
BA_ "GenSigSendType" SG_ 2566854382 LastBorderCrossingPlaceRecLat 3;
BA_ "GenSigTimeoutTime_PCM" SG_ 2566854382 LastBorderCrossingPlaceRecLat 300000;
BA_ "CI_ParId" SG_ 2566854382 LastBorderCrossingPlaceRecGnssAc "V565";
BA_ "CI_SigId" SG_ 2566854382 LastBorderCrossingPlaceRecGnssAc 45722;
BA_ "CI_SigName" SG_ 2566854382 LastBorderCrossingPlaceRecGnssAc "Last Border Crossing Place Record - GNSS Accuracy";
BA_ "GenSigSendType" SG_ 2566854382 LastBorderCrossingPlaceRecGnssAc 3;
BA_ "GenSigStartValue" SG_ 2566854382 LastBorderCrossingPlaceRecGnssAc 1;
BA_ "GenSigTimeoutTime_PCM" SG_ 2566854382 LastBorderCrossingPlaceRecGnssAc 300000;
BA_ "CI_ParId" SG_ 2566854382 LastBorderCrossingPlaceRecTs "V564";
BA_ "CI_SigId" SG_ 2566854382 LastBorderCrossingPlaceRecTs 45721;
BA_ "CI_SigName" SG_ 2566854382 LastBorderCrossingPlaceRecTs "Last Border Crossing Place Record - Timestamp";
BA_ "GenSigSendType" SG_ 2566854382 LastBorderCrossingPlaceRecTs 3;
BA_ "GenSigTimeoutTime_PCM" SG_ 2566854382 LastBorderCrossingPlaceRecTs 300000;
BA_ "SigType" SG_ 2566854382 LastBorderCrossingPlaceRecTs 1;
BA_ "CI_ParId" SG_ 2566854382 LastCntryEntered "V563";
BA_ "CI_SigId" SG_ 2566854382 LastCntryEntered 45720;
BA_ "CI_SigName" SG_ 2566854382 LastCntryEntered "Last Country Entered";
BA_ "GenSigSendType" SG_ 2566854382 LastCntryEntered 3;
BA_ "GenSigTimeoutTime_PCM" SG_ 2566854382 LastCntryEntered 300000;
BA_ "CI_ParId" SG_ 2566854382 LastCntryLeft "V562";
BA_ "CI_SigId" SG_ 2566854382 LastCntryLeft 45719;
BA_ "CI_SigName" SG_ 2566854382 LastCntryLeft "Last Country Left";
BA_ "GenSigSendType" SG_ 2566854382 LastCntryLeft 3;
BA_ "GenSigTimeoutTime_PCM" SG_ 2566854382 LastCntryLeft 300000;
BA_ "CI_ParId" SG_ 2566897985 CallLogIx10Txt "I482";
BA_ "CI_SigId" SG_ 2566897985 CallLogIx10Txt 44875;
BA_ "CI_SigName" SG_ 2566897985 CallLogIx10Txt "Call Log Index 10 Text";
BA_ "SigType" SG_ 2566897985 CallLogIx10Txt 8;
BA_ "CI_ParId" SG_ 2566897985 CallLogIx9Txt "I481";
BA_ "CI_SigId" SG_ 2566897985 CallLogIx9Txt 44874;
BA_ "CI_SigName" SG_ 2566897985 CallLogIx9Txt "Call Log Index 9 Text";
BA_ "SigType" SG_ 2566897985 CallLogIx9Txt 8;
BA_ "CI_ParId" SG_ 2566897985 CallLogIx8Txt "I480";
BA_ "CI_SigId" SG_ 2566897985 CallLogIx8Txt 44873;
BA_ "CI_SigName" SG_ 2566897985 CallLogIx8Txt "Call Log Index 8 Text";
BA_ "SigType" SG_ 2566897985 CallLogIx8Txt 8;
BA_ "CI_ParId" SG_ 2566897985 CallLogIx7Txt "I479";
BA_ "CI_SigId" SG_ 2566897985 CallLogIx7Txt 44872;
BA_ "CI_SigName" SG_ 2566897985 CallLogIx7Txt "Call Log Index 7 Text";
BA_ "SigType" SG_ 2566897985 CallLogIx7Txt 8;
BA_ "CI_ParId" SG_ 2566897985 CallLogIx6Txt "I478";
BA_ "CI_SigId" SG_ 2566897985 CallLogIx6Txt 44871;
BA_ "CI_SigName" SG_ 2566897985 CallLogIx6Txt "Call Log Index 6 Text";
BA_ "SigType" SG_ 2566897985 CallLogIx6Txt 8;
BA_ "CI_ParId" SG_ 2566897985 CallLogIx5Txt "I477";
BA_ "CI_SigId" SG_ 2566897985 CallLogIx5Txt 44870;
BA_ "CI_SigName" SG_ 2566897985 CallLogIx5Txt "Call Log Index 5 Text";
BA_ "SigType" SG_ 2566897985 CallLogIx5Txt 8;
BA_ "CI_ParId" SG_ 2566897985 CallLogIx4Txt "I476";
BA_ "CI_SigId" SG_ 2566897985 CallLogIx4Txt 44869;
BA_ "CI_SigName" SG_ 2566897985 CallLogIx4Txt "Call Log Index 4 Text";
BA_ "SigType" SG_ 2566897985 CallLogIx4Txt 8;
BA_ "CI_ParId" SG_ 2566897985 CallLogIx3Txt "I475";
BA_ "CI_SigId" SG_ 2566897985 CallLogIx3Txt 44868;
BA_ "CI_SigName" SG_ 2566897985 CallLogIx3Txt "Call Log Index 3 Text";
BA_ "SigType" SG_ 2566897985 CallLogIx3Txt 8;
BA_ "CI_ParId" SG_ 2566897985 CallLogIx2Txt "I474";
BA_ "CI_SigId" SG_ 2566897985 CallLogIx2Txt 44867;
BA_ "CI_SigName" SG_ 2566897985 CallLogIx2Txt "Call Log Index 2 Text";
BA_ "SigType" SG_ 2566897985 CallLogIx2Txt 8;
BA_ "CI_ParId" SG_ 2566897985 CallLogIx1Txt "I473";
BA_ "CI_SigId" SG_ 2566897985 CallLogIx1Txt 44866;
BA_ "CI_SigName" SG_ 2566897985 CallLogIx1Txt "Call Log Index 1 Text";
BA_ "SigType" SG_ 2566897985 CallLogIx1Txt 8;
BA_ "CI_ParId" SG_ 2566897985 CallLogIx10Type "I472";
BA_ "CI_SigId" SG_ 2566897985 CallLogIx10Type 9738;
BA_ "CI_SigName" SG_ 2566897985 CallLogIx10Type "Call Log Index 10 Type";
BA_ "CI_ParId" SG_ 2566897985 CallLogIx9Type "I471";
BA_ "CI_SigId" SG_ 2566897985 CallLogIx9Type 9737;
BA_ "CI_SigName" SG_ 2566897985 CallLogIx9Type "Call Log Index 9 Type";
BA_ "CI_ParId" SG_ 2566897985 CallLogIx8Type "I470";
BA_ "CI_SigId" SG_ 2566897985 CallLogIx8Type 9736;
BA_ "CI_SigName" SG_ 2566897985 CallLogIx8Type "Call Log Index 8 Type";
BA_ "CI_ParId" SG_ 2566897985 CallLogIx7Type "I469";
BA_ "CI_SigId" SG_ 2566897985 CallLogIx7Type 9735;
BA_ "CI_SigName" SG_ 2566897985 CallLogIx7Type "Call Log Index 7 Type";
BA_ "CI_ParId" SG_ 2566897985 CallLogIx6Type "I468";
BA_ "CI_SigId" SG_ 2566897985 CallLogIx6Type 9734;
BA_ "CI_SigName" SG_ 2566897985 CallLogIx6Type "Call Log Index 6 Type";
BA_ "CI_ParId" SG_ 2566897985 CallLogIx5Type "I467";
BA_ "CI_SigId" SG_ 2566897985 CallLogIx5Type 9733;
BA_ "CI_SigName" SG_ 2566897985 CallLogIx5Type "Call Log Index 5 Type";
BA_ "CI_ParId" SG_ 2566897985 CallLogIx4Type "I466";
BA_ "CI_SigId" SG_ 2566897985 CallLogIx4Type 9732;
BA_ "CI_SigName" SG_ 2566897985 CallLogIx4Type "Call Log Index 4 Type";
BA_ "CI_ParId" SG_ 2566897985 CallLogIx3Type "I465";
BA_ "CI_SigId" SG_ 2566897985 CallLogIx3Type 9731;
BA_ "CI_SigName" SG_ 2566897985 CallLogIx3Type "Call Log Index 3 Type";
BA_ "CI_ParId" SG_ 2566897985 CallLogIx2Type "I464";
BA_ "CI_SigId" SG_ 2566897985 CallLogIx2Type 9730;
BA_ "CI_SigName" SG_ 2566897985 CallLogIx2Type "Call Log Index 2 Type";
BA_ "CI_ParId" SG_ 2566897985 CallLogIx1Type "I463";
BA_ "CI_SigId" SG_ 2566897985 CallLogIx1Type 9729;
BA_ "CI_SigName" SG_ 2566897985 CallLogIx1Type "Call Log Index 1 Type";
BA_ "CI_ParId" SG_ 2566897985 CallLogEntriesNum "I462";
BA_ "CI_SigId" SG_ 2566897985 CallLogEntriesNum 9728;
BA_ "CI_SigName" SG_ 2566897985 CallLogEntriesNum "Call Log Entries Number";
BA_ "CI_ParId" SG_ 2566897985 DevIx "I1001";
BA_ "CI_SigId" SG_ 2566897985 DevIx 42034;
BA_ "CI_SigName" SG_ 2566897985 DevIx "Device Index";
BA_ "SigType" SG_ 2566897985 DevIx 4;
BA_ "CI_ParId" SG_ 2566897985 TelephoneConn "I461";
BA_ "CI_SigId" SG_ 2566897985 TelephoneConn 9727;
BA_ "CI_SigName" SG_ 2566897985 TelephoneConn "Telephone Connected";
BA_ "SigType" SG_ 2566897985 TelephoneConn 4;
BA_ "CI_ParId" SG_ 2566882327 AewhSchedulingSts "ID2547";
BA_ "CI_SigId" SG_ 2566882327 AewhSchedulingSts 44886;
BA_ "CI_SigName" SG_ 2566882327 AewhSchedulingSts "AEWH Scheduling Status";
BA_ "SigType" SG_ 2566882327 AewhSchedulingSts 4;
BA_ "CI_ParId" SG_ 2566882327 CabInternTempCmd_FF8417 "1691";
BA_ "CI_SigId" SG_ 2566882327 CabInternTempCmd_FF8417 8594;
BA_ "CI_SigName" SG_ 2566882327 CabInternTempCmd_FF8417 "Cab Interior Temperature Command";
BA_ "SPN" SG_ 2566882327 CabInternTempCmd_FF8417 1691;
BA_ "SigType" SG_ 2566882327 CabInternTempCmd_FF8417 1;
BA_ "CI_ParId" SG_ 2566882327 DurTimerMin "I496";
BA_ "CI_SigId" SG_ 2566882327 DurTimerMin 8593;
BA_ "CI_SigName" SG_ 2566882327 DurTimerMin "Duration Timer, Minutes";
BA_ "SigType" SG_ 2566882327 DurTimerMin 1;
BA_ "CI_ParId" SG_ 2566882327 ClimaCtrlVentilMode "I495";
BA_ "CI_SigId" SG_ 2566882327 ClimaCtrlVentilMode 8590;
BA_ "CI_SigName" SG_ 2566882327 ClimaCtrlVentilMode "Climate Control Ventilation Mode";
BA_ "SigType" SG_ 2566882327 ClimaCtrlVentilMode 4;
BA_ "CI_ParId" SG_ 2566882327 ClimaCtrlMode "I494";
BA_ "CI_SigId" SG_ 2566882327 ClimaCtrlMode 8589;
BA_ "CI_SigName" SG_ 2566882327 ClimaCtrlMode "Climate Control Mode";
BA_ "CI_ParId" SG_ 2566882337 AewhFunctSts "ID2546";
BA_ "CI_SigId" SG_ 2566882337 AewhFunctSts 44885;
BA_ "CI_SigName" SG_ 2566882337 AewhFunctSts "AEWH Functional Status";
BA_ "GenSigSendType" SG_ 2566882337 AewhFunctSts 3;
BA_ "GenSigTimeoutTime_PCM" SG_ 2566882337 AewhFunctSts 5000;
BA_ "CI_ParId" SG_ 2566882337 CabInternTempCmd_FF8421 "1691";
BA_ "CI_SigId" SG_ 2566882337 CabInternTempCmd_FF8421 8609;
BA_ "CI_SigName" SG_ 2566882337 CabInternTempCmd_FF8421 "Cab Interior Temperature Command";
BA_ "GenSigSendType" SG_ 2566882337 CabInternTempCmd_FF8421 3;
BA_ "GenSigTimeoutTime_PCM" SG_ 2566882337 CabInternTempCmd_FF8421 5000;
BA_ "SPN" SG_ 2566882337 CabInternTempCmd_FF8421 1691;
BA_ "SigType" SG_ 2566882337 CabInternTempCmd_FF8421 1;
BA_ "CI_ParId" SG_ 2566882337 DurTimerMin_FF8421 "I496";
BA_ "CI_SigId" SG_ 2566882337 DurTimerMin_FF8421 8608;
BA_ "CI_SigName" SG_ 2566882337 DurTimerMin_FF8421 "Duration Timer, Minutes";
BA_ "GenSigSendType" SG_ 2566882337 DurTimerMin_FF8421 3;
BA_ "GenSigTimeoutTime_PCM" SG_ 2566882337 DurTimerMin_FF8421 5000;
BA_ "SigType" SG_ 2566882337 DurTimerMin_FF8421 1;
BA_ "CI_ParId" SG_ 2566882337 ClimaCtrlMode_FF8421 "I494";
BA_ "CI_SigId" SG_ 2566882337 ClimaCtrlMode_FF8421 8604;
BA_ "CI_SigName" SG_ 2566882337 ClimaCtrlMode_FF8421 "Climate Control Mode";
BA_ "GenSigSendType" SG_ 2566882337 ClimaCtrlMode_FF8421 3;
BA_ "GenSigTimeoutTime_PCM" SG_ 2566882337 ClimaCtrlMode_FF8421 5000;
BA_ "CI_ParId" SG_ 2566882337 EcoMode "I808";
BA_ "CI_SigId" SG_ 2566882337 EcoMode 8603;
BA_ "CI_SigName" SG_ 2566882337 EcoMode "Eco Mode";
BA_ "GenSigSendType" SG_ 2566882337 EcoMode 3;
BA_ "GenSigTimeoutTime_PCM" SG_ 2566882337 EcoMode 5000;
BA_ "SigType" SG_ 2566882337 EcoMode 4;
BA_ "CI_ParId" SG_ 2566882378 AewhSchedulingSts_FF844A "ID2547";
BA_ "CI_SigId" SG_ 2566882378 AewhSchedulingSts_FF844A 44887;
BA_ "CI_SigName" SG_ 2566882378 AewhSchedulingSts_FF844A "AEWH Scheduling Status";
BA_ "SigType" SG_ 2566882378 AewhSchedulingSts_FF844A 4;
BA_ "CI_ParId" SG_ 2566882378 CabInternTempCmd_FF844A "1691";
BA_ "CI_SigId" SG_ 2566882378 CabInternTempCmd_FF844A 8601;
BA_ "CI_SigName" SG_ 2566882378 CabInternTempCmd_FF844A "Cab Interior Temperature Command";
BA_ "SPN" SG_ 2566882378 CabInternTempCmd_FF844A 1691;
BA_ "SigType" SG_ 2566882378 CabInternTempCmd_FF844A 1;
BA_ "CI_ParId" SG_ 2566882378 DurTimerMin_FF844A "I496";
BA_ "CI_SigId" SG_ 2566882378 DurTimerMin_FF844A 8600;
BA_ "CI_SigName" SG_ 2566882378 DurTimerMin_FF844A "Duration Timer, Minutes";
BA_ "SigType" SG_ 2566882378 DurTimerMin_FF844A 1;
BA_ "CI_ParId" SG_ 2566882378 ClimaCtrlVentilMode_FF844A "I495";
BA_ "CI_SigId" SG_ 2566882378 ClimaCtrlVentilMode_FF844A 8597;
BA_ "CI_SigName" SG_ 2566882378 ClimaCtrlVentilMode_FF844A "Climate Control Ventilation Mode";
BA_ "SigType" SG_ 2566882378 ClimaCtrlVentilMode_FF844A 4;
BA_ "CI_ParId" SG_ 2566882378 ClimaCtrlMode_FF844A "I494";
BA_ "CI_SigId" SG_ 2566882378 ClimaCtrlMode_FF844A 8596;
BA_ "CI_SigName" SG_ 2566882378 ClimaCtrlMode_FF844A "Climate Control Mode";
BA_ "CI_ParId" SG_ 2583654960 CdcActvMode "ID0978";
BA_ "CI_SigId" SG_ 2583654960 CdcActvMode 35142;
BA_ "CI_SigName" SG_ 2583654960 CdcActvMode "CDC Active Mode";
BA_ "GenSigSendType" SG_ 2583654960 CdcActvMode 3;
BA_ "GenSigTimeoutTime_PCM" SG_ 2583654960 CdcActvMode 50000;
BA_ "CI_ParId" SG_ 2566895393 ParkBrkCfg "ID2185";
BA_ "CI_SigId" SG_ 2566895393 ParkBrkCfg 42177;
BA_ "CI_SigName" SG_ 2566895393 ParkBrkCfg "Parking Brake Configuration";
BA_ "GenSigTimeoutTime_PCM" SG_ 2566895393 ParkBrkCfg 10000;
BA_ "SigType" SG_ 2566895393 ParkBrkCfg 4;
BA_ "CI_ParId" SG_ 2566895393 HydrSysType "ID2183";
BA_ "CI_SigId" SG_ 2566895393 HydrSysType 42176;
BA_ "CI_SigName" SG_ 2566895393 HydrSysType "Hydraulic System Type";
BA_ "GenSigTimeoutTime_PCM" SG_ 2566895393 HydrSysType 10000;
BA_ "SigType" SG_ 2566895393 HydrSysType 4;
BA_ "CI_ParId" SG_ 2566895393 BodyType "ID2182";
BA_ "CI_SigId" SG_ 2566895393 BodyType 42175;
BA_ "CI_SigName" SG_ 2566895393 BodyType "Body Type";
BA_ "GenSigTimeoutTime_PCM" SG_ 2566895393 BodyType 10000;
BA_ "SigType" SG_ 2566895393 BodyType 4;
BA_ "CI_ParId" SG_ 2566895393 RetCfg "ID2181";
BA_ "CI_SigId" SG_ 2566895393 RetCfg 42174;
BA_ "CI_SigName" SG_ 2566895393 RetCfg "Retarder Configuration";
BA_ "GenSigTimeoutTime_PCM" SG_ 2566895393 RetCfg 10000;
BA_ "CI_ParId" SG_ 2566895393 ParkBrkType "ID2180";
BA_ "CI_SigId" SG_ 2566895393 ParkBrkType 42173;
BA_ "CI_SigName" SG_ 2566895393 ParkBrkType "Parking Brake Type";
BA_ "GenSigTimeoutTime_PCM" SG_ 2566895393 ParkBrkType 10000;
BA_ "CI_ParId" SG_ 2566895393 RaRatio "ID2184";
BA_ "CI_SigId" SG_ 2566895393 RaRatio 42172;
BA_ "CI_SigName" SG_ 2566895393 RaRatio "Rear Axle Ratio";
BA_ "GenSigTimeoutTime_PCM" SG_ 2566895393 RaRatio 10000;
BA_ "CI_ParId" SG_ 2566895393 EngTypeVar4 "ID2179";
BA_ "CI_SigId" SG_ 2566895393 EngTypeVar4 42171;
BA_ "CI_SigName" SG_ 2566895393 EngTypeVar4 "Engine Type Variant 4";
BA_ "GenSigTimeoutTime_PCM" SG_ 2566895393 EngTypeVar4 10000;
BA_ "CI_ParId" SG_ 2566895393 SuspFront "ID2178";
BA_ "CI_SigId" SG_ 2566895393 SuspFront 42170;
BA_ "CI_SigName" SG_ 2566895393 SuspFront "Suspension Front";
BA_ "GenSigTimeoutTime_PCM" SG_ 2566895393 SuspFront 10000;
BA_ "SigType" SG_ 2566895393 SuspFront 4;
BA_ "CI_ParId" SG_ 2566895393 SuspRear "ID2177";
BA_ "CI_SigId" SG_ 2566895393 SuspRear 42169;
BA_ "CI_SigName" SG_ 2566895393 SuspRear "Suspension Rear";
BA_ "GenSigTimeoutTime_PCM" SG_ 2566895393 SuspRear 10000;
BA_ "SigType" SG_ 2566895393 SuspRear 4;
BA_ "CI_ParId" SG_ 2566895393 WhCircumf3 "ID2176";
BA_ "CI_SigId" SG_ 2566895393 WhCircumf3 42168;
BA_ "CI_SigName" SG_ 2566895393 WhCircumf3 "Wheel Circumference 3";
BA_ "GenSigStartValue" SG_ 2566895393 WhCircumf3 1;
BA_ "GenSigTimeoutTime_PCM" SG_ 2566895393 WhCircumf3 10000;
BA_ "SigType" SG_ 2566895393 WhCircumf3 1;
BA_ "CI_ParId" SG_ 2566895393 WhBase2 "ID2175";
BA_ "CI_SigId" SG_ 2566895393 WhBase2 42167;
BA_ "CI_SigName" SG_ 2566895393 WhBase2 "Wheel Base 2";
BA_ "GenSigTimeoutTime_PCM" SG_ 2566895393 WhBase2 10000;
BA_ "CI_ParId" SG_ 2566895393 MaxVehCap "ID2174";
BA_ "CI_SigId" SG_ 2566895393 MaxVehCap 42166;
BA_ "CI_SigName" SG_ 2566895393 MaxVehCap "Max Vehicle Capacity";
BA_ "GenSigTimeoutTime_PCM" SG_ 2566895393 MaxVehCap 10000;
BA_ "CI_ParId" SG_ 2566895393 ElnBrkSysTypeVar "ID2173";
BA_ "CI_SigId" SG_ 2566895393 ElnBrkSysTypeVar 42165;
BA_ "CI_SigName" SG_ 2566895393 ElnBrkSysTypeVar "Electronic Brake System Type Variant";
BA_ "GenSigTimeoutTime_PCM" SG_ 2566895393 ElnBrkSysTypeVar 10000;
BA_ "CI_ParId" SG_ 2566895393 GbxTypeVar2 "ID2172";
BA_ "CI_SigId" SG_ 2566895393 GbxTypeVar2 42164;
BA_ "CI_SigName" SG_ 2566895393 GbxTypeVar2 "GearBox Type Variant 2";
BA_ "GenSigTimeoutTime_PCM" SG_ 2566895393 GbxTypeVar2 10000;
BA_ "CI_ParId" SG_ 2650777478 ChgBelowNeg20_h "MV031";
BA_ "CI_SigId" SG_ 2650777478 ChgBelowNeg20_h 44141;
BA_ "CI_SigName" SG_ 2650777478 ChgBelowNeg20_h "ChgBelowNeg20_h";
BA_ "GenSigTimeoutTime_PCM" SG_ 2650777478 ChgBelowNeg20_h 3000000;
BA_ "SigType" SG_ 2650777478 ChgBelowNeg20_h 1;
BA_ "CI_ParId" SG_ 2650777478 ChgBelowNeg10_h "MV030";
BA_ "CI_SigId" SG_ 2650777478 ChgBelowNeg10_h 44140;
BA_ "CI_SigName" SG_ 2650777478 ChgBelowNeg10_h "ChgBelowNeg10_h";
BA_ "GenSigTimeoutTime_PCM" SG_ 2650777478 ChgBelowNeg10_h 3000000;
BA_ "SigType" SG_ 2650777478 ChgBelowNeg10_h 1;
BA_ "CI_ParId" SG_ 2650777478 ChgBelow0_h "MV029";
BA_ "CI_SigId" SG_ 2650777478 ChgBelow0_h 44139;
BA_ "CI_SigName" SG_ 2650777478 ChgBelow0_h "ChgBelow0_h";
BA_ "GenSigTimeoutTime_PCM" SG_ 2650777478 ChgBelow0_h 3000000;
BA_ "SigType" SG_ 2650777478 ChgBelow0_h 1;
BA_ "CI_ParId" SG_ 2650777478 ChgOver0_h "MV028";
BA_ "CI_SigId" SG_ 2650777478 ChgOver0_h 44138;
BA_ "CI_SigName" SG_ 2650777478 ChgOver0_h "ChgOver0_h";
BA_ "GenSigTimeoutTime_PCM" SG_ 2650777478 ChgOver0_h 3000000;
BA_ "SigType" SG_ 2650777478 ChgOver0_h 1;
BA_ "CI_ParId" SG_ 2650777478 ChgOver15_h "MV027";
BA_ "CI_SigId" SG_ 2650777478 ChgOver15_h 44137;
BA_ "CI_SigName" SG_ 2650777478 ChgOver15_h "ChgOver15_h";
BA_ "GenSigTimeoutTime_PCM" SG_ 2650777478 ChgOver15_h 3000000;
BA_ "SigType" SG_ 2650777478 ChgOver15_h 1;
BA_ "CI_ParId" SG_ 2650777478 ChgOver30_h "MV026";
BA_ "CI_SigId" SG_ 2650777478 ChgOver30_h 44136;
BA_ "CI_SigName" SG_ 2650777478 ChgOver30_h "ChgOver30_h";
BA_ "GenSigTimeoutTime_PCM" SG_ 2650777478 ChgOver30_h 3000000;
BA_ "SigType" SG_ 2650777478 ChgOver30_h 1;
BA_ "CI_ParId" SG_ 2650777478 ChgOver35_h "MV025";
BA_ "CI_SigId" SG_ 2650777478 ChgOver35_h 44135;
BA_ "CI_SigName" SG_ 2650777478 ChgOver35_h "ChgOver35_h";
BA_ "GenSigTimeoutTime_PCM" SG_ 2650777478 ChgOver35_h 3000000;
BA_ "SigType" SG_ 2650777478 ChgOver35_h 1;
BA_ "CI_ParId" SG_ 2650777478 ChgOver40_h "MV024";
BA_ "CI_SigId" SG_ 2650777478 ChgOver40_h 44134;
BA_ "CI_SigName" SG_ 2650777478 ChgOver40_h "ChgOver40_h";
BA_ "GenSigTimeoutTime_PCM" SG_ 2650777478 ChgOver40_h 3000000;
BA_ "SigType" SG_ 2650777478 ChgOver40_h 1;
BA_ "CI_ParId" SG_ 2650777478 ChgOver45_h "MV023";
BA_ "CI_SigId" SG_ 2650777478 ChgOver45_h 44133;
BA_ "CI_SigName" SG_ 2650777478 ChgOver45_h "ChgOver45_h";
BA_ "GenSigTimeoutTime_PCM" SG_ 2650777478 ChgOver45_h 3000000;
BA_ "SigType" SG_ 2650777478 ChgOver45_h 1;
BA_ "CI_ParId" SG_ 2650777478 ChgOver55_h "MV022";
BA_ "CI_SigId" SG_ 2650777478 ChgOver55_h 44132;
BA_ "CI_SigName" SG_ 2650777478 ChgOver55_h "ChgOver55_h";
BA_ "GenSigTimeoutTime_PCM" SG_ 2650777478 ChgOver55_h 3000000;
BA_ "SigType" SG_ 2650777478 ChgOver55_h 1;
BA_ "CI_ParId" SG_ 2650777479 ChgBelowNeg20_h_FFA787 "MV031";
BA_ "CI_SigId" SG_ 2650777479 ChgBelowNeg20_h_FFA787 44152;
BA_ "CI_SigName" SG_ 2650777479 ChgBelowNeg20_h_FFA787 "ChgBelowNeg20_h";
BA_ "GenSigTimeoutTime_PCM" SG_ 2650777479 ChgBelowNeg20_h_FFA787 3000000;
BA_ "SigType" SG_ 2650777479 ChgBelowNeg20_h_FFA787 1;
BA_ "CI_ParId" SG_ 2650777479 ChgBelowNeg10_h_FFA787 "MV030";
BA_ "CI_SigId" SG_ 2650777479 ChgBelowNeg10_h_FFA787 44151;
BA_ "CI_SigName" SG_ 2650777479 ChgBelowNeg10_h_FFA787 "ChgBelowNeg10_h";
BA_ "GenSigTimeoutTime_PCM" SG_ 2650777479 ChgBelowNeg10_h_FFA787 3000000;
BA_ "SigType" SG_ 2650777479 ChgBelowNeg10_h_FFA787 1;
BA_ "CI_ParId" SG_ 2650777479 ChgBelow0_h_FFA787 "MV029";
BA_ "CI_SigId" SG_ 2650777479 ChgBelow0_h_FFA787 44150;
BA_ "CI_SigName" SG_ 2650777479 ChgBelow0_h_FFA787 "ChgBelow0_h";
BA_ "GenSigTimeoutTime_PCM" SG_ 2650777479 ChgBelow0_h_FFA787 3000000;
BA_ "SigType" SG_ 2650777479 ChgBelow0_h_FFA787 1;
BA_ "CI_ParId" SG_ 2650777479 ChgOver0_h_FFA787 "MV028";
BA_ "CI_SigId" SG_ 2650777479 ChgOver0_h_FFA787 44149;
BA_ "CI_SigName" SG_ 2650777479 ChgOver0_h_FFA787 "ChgOver0_h";
BA_ "GenSigTimeoutTime_PCM" SG_ 2650777479 ChgOver0_h_FFA787 3000000;
BA_ "SigType" SG_ 2650777479 ChgOver0_h_FFA787 1;
BA_ "CI_ParId" SG_ 2650777479 ChgOver15_h_FFA787 "MV027";
BA_ "CI_SigId" SG_ 2650777479 ChgOver15_h_FFA787 44148;
BA_ "CI_SigName" SG_ 2650777479 ChgOver15_h_FFA787 "ChgOver15_h";
BA_ "GenSigTimeoutTime_PCM" SG_ 2650777479 ChgOver15_h_FFA787 3000000;
BA_ "SigType" SG_ 2650777479 ChgOver15_h_FFA787 1;
BA_ "CI_ParId" SG_ 2650777479 ChgOver30_h_FFA787 "MV026";
BA_ "CI_SigId" SG_ 2650777479 ChgOver30_h_FFA787 44147;
BA_ "CI_SigName" SG_ 2650777479 ChgOver30_h_FFA787 "ChgOver30_h";
BA_ "GenSigTimeoutTime_PCM" SG_ 2650777479 ChgOver30_h_FFA787 3000000;
BA_ "SigType" SG_ 2650777479 ChgOver30_h_FFA787 1;
BA_ "CI_ParId" SG_ 2650777479 ChgOver35_h_FFA787 "MV025";
BA_ "CI_SigId" SG_ 2650777479 ChgOver35_h_FFA787 44146;
BA_ "CI_SigName" SG_ 2650777479 ChgOver35_h_FFA787 "ChgOver35_h";
BA_ "GenSigTimeoutTime_PCM" SG_ 2650777479 ChgOver35_h_FFA787 3000000;
BA_ "SigType" SG_ 2650777479 ChgOver35_h_FFA787 1;
BA_ "CI_ParId" SG_ 2650777479 ChgOver40_h_FFA787 "MV024";
BA_ "CI_SigId" SG_ 2650777479 ChgOver40_h_FFA787 44145;
BA_ "CI_SigName" SG_ 2650777479 ChgOver40_h_FFA787 "ChgOver40_h";
BA_ "GenSigTimeoutTime_PCM" SG_ 2650777479 ChgOver40_h_FFA787 3000000;
BA_ "SigType" SG_ 2650777479 ChgOver40_h_FFA787 1;
BA_ "CI_ParId" SG_ 2650777479 ChgOver45_h_FFA787 "MV023";
BA_ "CI_SigId" SG_ 2650777479 ChgOver45_h_FFA787 44144;
BA_ "CI_SigName" SG_ 2650777479 ChgOver45_h_FFA787 "ChgOver45_h";
BA_ "GenSigTimeoutTime_PCM" SG_ 2650777479 ChgOver45_h_FFA787 3000000;
BA_ "SigType" SG_ 2650777479 ChgOver45_h_FFA787 1;
BA_ "CI_ParId" SG_ 2650777479 ChgOver55_h_FFA787 "MV022";
BA_ "CI_SigId" SG_ 2650777479 ChgOver55_h_FFA787 44143;
BA_ "CI_SigName" SG_ 2650777479 ChgOver55_h_FFA787 "ChgOver55_h";
BA_ "GenSigTimeoutTime_PCM" SG_ 2650777479 ChgOver55_h_FFA787 3000000;
BA_ "SigType" SG_ 2650777479 ChgOver55_h_FFA787 1;
BA_ "CI_ParId" SG_ 2650777588 ChgBelowNeg20_h_FFA7F4 "MV031";
BA_ "CI_SigId" SG_ 2650777588 ChgBelowNeg20_h_FFA7F4 44108;
BA_ "CI_SigName" SG_ 2650777588 ChgBelowNeg20_h_FFA7F4 "ChgBelowNeg20_h";
BA_ "GenSigTimeoutTime_PCM" SG_ 2650777588 ChgBelowNeg20_h_FFA7F4 3000000;
BA_ "SigType" SG_ 2650777588 ChgBelowNeg20_h_FFA7F4 1;
BA_ "CI_ParId" SG_ 2650777588 ChgBelowNeg10_h_FFA7F4 "MV030";
BA_ "CI_SigId" SG_ 2650777588 ChgBelowNeg10_h_FFA7F4 44107;
BA_ "CI_SigName" SG_ 2650777588 ChgBelowNeg10_h_FFA7F4 "ChgBelowNeg10_h";
BA_ "GenSigTimeoutTime_PCM" SG_ 2650777588 ChgBelowNeg10_h_FFA7F4 3000000;
BA_ "SigType" SG_ 2650777588 ChgBelowNeg10_h_FFA7F4 1;
BA_ "CI_ParId" SG_ 2650777588 ChgBelow0_h_FFA7F4 "MV029";
BA_ "CI_SigId" SG_ 2650777588 ChgBelow0_h_FFA7F4 44106;
BA_ "CI_SigName" SG_ 2650777588 ChgBelow0_h_FFA7F4 "ChgBelow0_h";
BA_ "GenSigTimeoutTime_PCM" SG_ 2650777588 ChgBelow0_h_FFA7F4 3000000;
BA_ "SigType" SG_ 2650777588 ChgBelow0_h_FFA7F4 1;
BA_ "CI_ParId" SG_ 2650777588 ChgOver0_h_FFA7F4 "MV028";
BA_ "CI_SigId" SG_ 2650777588 ChgOver0_h_FFA7F4 44105;
BA_ "CI_SigName" SG_ 2650777588 ChgOver0_h_FFA7F4 "ChgOver0_h";
BA_ "GenSigTimeoutTime_PCM" SG_ 2650777588 ChgOver0_h_FFA7F4 3000000;
BA_ "SigType" SG_ 2650777588 ChgOver0_h_FFA7F4 1;
BA_ "CI_ParId" SG_ 2650777588 ChgOver15_h_FFA7F4 "MV027";
BA_ "CI_SigId" SG_ 2650777588 ChgOver15_h_FFA7F4 44104;
BA_ "CI_SigName" SG_ 2650777588 ChgOver15_h_FFA7F4 "ChgOver15_h";
BA_ "GenSigTimeoutTime_PCM" SG_ 2650777588 ChgOver15_h_FFA7F4 3000000;
BA_ "SigType" SG_ 2650777588 ChgOver15_h_FFA7F4 1;
BA_ "CI_ParId" SG_ 2650777588 ChgOver30_h_FFA7F4 "MV026";
BA_ "CI_SigId" SG_ 2650777588 ChgOver30_h_FFA7F4 44103;
BA_ "CI_SigName" SG_ 2650777588 ChgOver30_h_FFA7F4 "ChgOver30_h";
BA_ "GenSigTimeoutTime_PCM" SG_ 2650777588 ChgOver30_h_FFA7F4 3000000;
BA_ "SigType" SG_ 2650777588 ChgOver30_h_FFA7F4 1;
BA_ "CI_ParId" SG_ 2650777588 ChgOver35_h_FFA7F4 "MV025";
BA_ "CI_SigId" SG_ 2650777588 ChgOver35_h_FFA7F4 44102;
BA_ "CI_SigName" SG_ 2650777588 ChgOver35_h_FFA7F4 "ChgOver35_h";
BA_ "GenSigTimeoutTime_PCM" SG_ 2650777588 ChgOver35_h_FFA7F4 3000000;
BA_ "SigType" SG_ 2650777588 ChgOver35_h_FFA7F4 1;
BA_ "CI_ParId" SG_ 2650777588 ChgOver40_h_FFA7F4 "MV024";
BA_ "CI_SigId" SG_ 2650777588 ChgOver40_h_FFA7F4 44101;
BA_ "CI_SigName" SG_ 2650777588 ChgOver40_h_FFA7F4 "ChgOver40_h";
BA_ "GenSigTimeoutTime_PCM" SG_ 2650777588 ChgOver40_h_FFA7F4 3000000;
BA_ "SigType" SG_ 2650777588 ChgOver40_h_FFA7F4 1;
BA_ "CI_ParId" SG_ 2650777588 ChgOver45_h_FFA7F4 "MV023";
BA_ "CI_SigId" SG_ 2650777588 ChgOver45_h_FFA7F4 44100;
BA_ "CI_SigName" SG_ 2650777588 ChgOver45_h_FFA7F4 "ChgOver45_h";
BA_ "GenSigTimeoutTime_PCM" SG_ 2650777588 ChgOver45_h_FFA7F4 3000000;
BA_ "SigType" SG_ 2650777588 ChgOver45_h_FFA7F4 1;
BA_ "CI_ParId" SG_ 2650777588 ChgOver55_h_FFA7F4 "MV022";
BA_ "CI_SigId" SG_ 2650777588 ChgOver55_h_FFA7F4 44099;
BA_ "CI_SigName" SG_ 2650777588 ChgOver55_h_FFA7F4 "ChgOver55_h";
BA_ "GenSigTimeoutTime_PCM" SG_ 2650777588 ChgOver55_h_FFA7F4 3000000;
BA_ "SigType" SG_ 2650777588 ChgOver55_h_FFA7F4 1;
BA_ "CI_ParId" SG_ 2650777589 ChgBelowNeg20_h_FFA7F5 "MV031";
BA_ "CI_SigId" SG_ 2650777589 ChgBelowNeg20_h_FFA7F5 44119;
BA_ "CI_SigName" SG_ 2650777589 ChgBelowNeg20_h_FFA7F5 "ChgBelowNeg20_h";
BA_ "GenSigTimeoutTime_PCM" SG_ 2650777589 ChgBelowNeg20_h_FFA7F5 3000000;
BA_ "SigType" SG_ 2650777589 ChgBelowNeg20_h_FFA7F5 1;
BA_ "CI_ParId" SG_ 2650777589 ChgBelowNeg10_h_FFA7F5 "MV030";
BA_ "CI_SigId" SG_ 2650777589 ChgBelowNeg10_h_FFA7F5 44118;
BA_ "CI_SigName" SG_ 2650777589 ChgBelowNeg10_h_FFA7F5 "ChgBelowNeg10_h";
BA_ "GenSigTimeoutTime_PCM" SG_ 2650777589 ChgBelowNeg10_h_FFA7F5 3000000;
BA_ "SigType" SG_ 2650777589 ChgBelowNeg10_h_FFA7F5 1;
BA_ "CI_ParId" SG_ 2650777589 ChgBelow0_h_FFA7F5 "MV029";
BA_ "CI_SigId" SG_ 2650777589 ChgBelow0_h_FFA7F5 44117;
BA_ "CI_SigName" SG_ 2650777589 ChgBelow0_h_FFA7F5 "ChgBelow0_h";
BA_ "GenSigTimeoutTime_PCM" SG_ 2650777589 ChgBelow0_h_FFA7F5 3000000;
BA_ "SigType" SG_ 2650777589 ChgBelow0_h_FFA7F5 1;
BA_ "CI_ParId" SG_ 2650777589 ChgOver0_h_FFA7F5 "MV028";
BA_ "CI_SigId" SG_ 2650777589 ChgOver0_h_FFA7F5 44116;
BA_ "CI_SigName" SG_ 2650777589 ChgOver0_h_FFA7F5 "ChgOver0_h";
BA_ "GenSigTimeoutTime_PCM" SG_ 2650777589 ChgOver0_h_FFA7F5 3000000;
BA_ "SigType" SG_ 2650777589 ChgOver0_h_FFA7F5 1;
BA_ "CI_ParId" SG_ 2650777589 ChgOver15_h_FFA7F5 "MV027";
BA_ "CI_SigId" SG_ 2650777589 ChgOver15_h_FFA7F5 44115;
BA_ "CI_SigName" SG_ 2650777589 ChgOver15_h_FFA7F5 "ChgOver15_h";
BA_ "GenSigTimeoutTime_PCM" SG_ 2650777589 ChgOver15_h_FFA7F5 3000000;
BA_ "SigType" SG_ 2650777589 ChgOver15_h_FFA7F5 1;
BA_ "CI_ParId" SG_ 2650777589 ChgOver30_h_FFA7F5 "MV026";
BA_ "CI_SigId" SG_ 2650777589 ChgOver30_h_FFA7F5 44114;
BA_ "CI_SigName" SG_ 2650777589 ChgOver30_h_FFA7F5 "ChgOver30_h";
BA_ "GenSigTimeoutTime_PCM" SG_ 2650777589 ChgOver30_h_FFA7F5 3000000;
BA_ "SigType" SG_ 2650777589 ChgOver30_h_FFA7F5 1;
BA_ "CI_ParId" SG_ 2650777589 ChgOver35_h_FFA7F5 "MV025";
BA_ "CI_SigId" SG_ 2650777589 ChgOver35_h_FFA7F5 44113;
BA_ "CI_SigName" SG_ 2650777589 ChgOver35_h_FFA7F5 "ChgOver35_h";
BA_ "GenSigTimeoutTime_PCM" SG_ 2650777589 ChgOver35_h_FFA7F5 3000000;
BA_ "SigType" SG_ 2650777589 ChgOver35_h_FFA7F5 1;
BA_ "CI_ParId" SG_ 2650777589 ChgOver40_h_FFA7F5 "MV024";
BA_ "CI_SigId" SG_ 2650777589 ChgOver40_h_FFA7F5 44112;
BA_ "CI_SigName" SG_ 2650777589 ChgOver40_h_FFA7F5 "ChgOver40_h";
BA_ "GenSigTimeoutTime_PCM" SG_ 2650777589 ChgOver40_h_FFA7F5 3000000;
BA_ "SigType" SG_ 2650777589 ChgOver40_h_FFA7F5 1;
BA_ "CI_ParId" SG_ 2650777589 ChgOver45_h_FFA7F5 "MV023";
BA_ "CI_SigId" SG_ 2650777589 ChgOver45_h_FFA7F5 44111;
BA_ "CI_SigName" SG_ 2650777589 ChgOver45_h_FFA7F5 "ChgOver45_h";
BA_ "GenSigTimeoutTime_PCM" SG_ 2650777589 ChgOver45_h_FFA7F5 3000000;
BA_ "SigType" SG_ 2650777589 ChgOver45_h_FFA7F5 1;
BA_ "CI_ParId" SG_ 2650777589 ChgOver55_h_FFA7F5 "MV022";
BA_ "CI_SigId" SG_ 2650777589 ChgOver55_h_FFA7F5 44110;
BA_ "CI_SigName" SG_ 2650777589 ChgOver55_h_FFA7F5 "ChgOver55_h";
BA_ "GenSigTimeoutTime_PCM" SG_ 2650777589 ChgOver55_h_FFA7F5 3000000;
BA_ "SigType" SG_ 2650777589 ChgOver55_h_FFA7F5 1;
BA_ "CI_ParId" SG_ 2650777590 ChgBelowNeg20_h_FFA7F6 "MV031";
BA_ "CI_SigId" SG_ 2650777590 ChgBelowNeg20_h_FFA7F6 44130;
BA_ "CI_SigName" SG_ 2650777590 ChgBelowNeg20_h_FFA7F6 "ChgBelowNeg20_h";
BA_ "GenSigTimeoutTime_PCM" SG_ 2650777590 ChgBelowNeg20_h_FFA7F6 3000000;
BA_ "SigType" SG_ 2650777590 ChgBelowNeg20_h_FFA7F6 1;
BA_ "CI_ParId" SG_ 2650777590 ChgBelowNeg10_h_FFA7F6 "MV030";
BA_ "CI_SigId" SG_ 2650777590 ChgBelowNeg10_h_FFA7F6 44129;
BA_ "CI_SigName" SG_ 2650777590 ChgBelowNeg10_h_FFA7F6 "ChgBelowNeg10_h";
BA_ "GenSigTimeoutTime_PCM" SG_ 2650777590 ChgBelowNeg10_h_FFA7F6 3000000;
BA_ "SigType" SG_ 2650777590 ChgBelowNeg10_h_FFA7F6 1;
BA_ "CI_ParId" SG_ 2650777590 ChgBelow0_h_FFA7F6 "MV029";
BA_ "CI_SigId" SG_ 2650777590 ChgBelow0_h_FFA7F6 44128;
BA_ "CI_SigName" SG_ 2650777590 ChgBelow0_h_FFA7F6 "ChgBelow0_h";
BA_ "GenSigTimeoutTime_PCM" SG_ 2650777590 ChgBelow0_h_FFA7F6 3000000;
BA_ "SigType" SG_ 2650777590 ChgBelow0_h_FFA7F6 1;
BA_ "CI_ParId" SG_ 2650777590 ChgOver0_h_FFA7F6 "MV028";
BA_ "CI_SigId" SG_ 2650777590 ChgOver0_h_FFA7F6 44127;
BA_ "CI_SigName" SG_ 2650777590 ChgOver0_h_FFA7F6 "ChgOver0_h";
BA_ "GenSigTimeoutTime_PCM" SG_ 2650777590 ChgOver0_h_FFA7F6 3000000;
BA_ "SigType" SG_ 2650777590 ChgOver0_h_FFA7F6 1;
BA_ "CI_ParId" SG_ 2650777590 ChgOver15_h_FFA7F6 "MV027";
BA_ "CI_SigId" SG_ 2650777590 ChgOver15_h_FFA7F6 44126;
BA_ "CI_SigName" SG_ 2650777590 ChgOver15_h_FFA7F6 "ChgOver15_h";
BA_ "GenSigTimeoutTime_PCM" SG_ 2650777590 ChgOver15_h_FFA7F6 3000000;
BA_ "SigType" SG_ 2650777590 ChgOver15_h_FFA7F6 1;
BA_ "CI_ParId" SG_ 2650777590 ChgOver30_h_FFA7F6 "MV026";
BA_ "CI_SigId" SG_ 2650777590 ChgOver30_h_FFA7F6 44125;
BA_ "CI_SigName" SG_ 2650777590 ChgOver30_h_FFA7F6 "ChgOver30_h";
BA_ "GenSigTimeoutTime_PCM" SG_ 2650777590 ChgOver30_h_FFA7F6 3000000;
BA_ "SigType" SG_ 2650777590 ChgOver30_h_FFA7F6 1;
BA_ "CI_ParId" SG_ 2650777590 ChgOver35_h_FFA7F6 "MV025";
BA_ "CI_SigId" SG_ 2650777590 ChgOver35_h_FFA7F6 44124;
BA_ "CI_SigName" SG_ 2650777590 ChgOver35_h_FFA7F6 "ChgOver35_h";
BA_ "GenSigTimeoutTime_PCM" SG_ 2650777590 ChgOver35_h_FFA7F6 3000000;
BA_ "SigType" SG_ 2650777590 ChgOver35_h_FFA7F6 1;
BA_ "CI_ParId" SG_ 2650777590 ChgOver40_h_FFA7F6 "MV024";
BA_ "CI_SigId" SG_ 2650777590 ChgOver40_h_FFA7F6 44123;
BA_ "CI_SigName" SG_ 2650777590 ChgOver40_h_FFA7F6 "ChgOver40_h";
BA_ "GenSigTimeoutTime_PCM" SG_ 2650777590 ChgOver40_h_FFA7F6 3000000;
BA_ "SigType" SG_ 2650777590 ChgOver40_h_FFA7F6 1;
BA_ "CI_ParId" SG_ 2650777590 ChgOver45_h_FFA7F6 "MV023";
BA_ "CI_SigId" SG_ 2650777590 ChgOver45_h_FFA7F6 44122;
BA_ "CI_SigName" SG_ 2650777590 ChgOver45_h_FFA7F6 "ChgOver45_h";
BA_ "GenSigTimeoutTime_PCM" SG_ 2650777590 ChgOver45_h_FFA7F6 3000000;
BA_ "SigType" SG_ 2650777590 ChgOver45_h_FFA7F6 1;
BA_ "CI_ParId" SG_ 2650777590 ChgOver55_h_FFA7F6 "MV022";
BA_ "CI_SigId" SG_ 2650777590 ChgOver55_h_FFA7F6 44121;
BA_ "CI_SigName" SG_ 2650777590 ChgOver55_h_FFA7F6 "ChgOver55_h";
BA_ "GenSigTimeoutTime_PCM" SG_ 2650777590 ChgOver55_h_FFA7F6 3000000;
BA_ "SigType" SG_ 2650777590 ChgOver55_h_FFA7F6 1;
BA_ "CI_ParId" SG_ 2583641895 CabCoolTemp_FF3F27 "ID2025";
BA_ "CI_SigId" SG_ 2583641895 CabCoolTemp_FF3F27 39849;
BA_ "CI_SigName" SG_ 2583641895 CabCoolTemp_FF3F27 "Cabin Coolant Temperature";
BA_ "GenSigTimeoutTime_PCM" SG_ 2583641895 CabCoolTemp_FF3F27 5000;
BA_ "SigType" SG_ 2583641895 CabCoolTemp_FF3F27 1;
BA_ "CI_ParId" SG_ 2583641895 ePwtMotCoolTemp "ID2024";
BA_ "CI_SigId" SG_ 2583641895 ePwtMotCoolTemp 39848;
BA_ "CI_SigName" SG_ 2583641895 ePwtMotCoolTemp "ePowertrain Motor Coolant Temperature";
BA_ "GenSigTimeoutTime_PCM" SG_ 2583641895 ePwtMotCoolTemp 5000;
BA_ "SigType" SG_ 2583641895 ePwtMotCoolTemp 1;
BA_ "CI_ParId" SG_ 2583641895 BatCoolTemp "ID2023";
BA_ "CI_SigId" SG_ 2583641895 BatCoolTemp 39847;
BA_ "CI_SigName" SG_ 2583641895 BatCoolTemp "Battery Coolant Temperature";
BA_ "GenSigTimeoutTime_PCM" SG_ 2583641895 BatCoolTemp 5000;
BA_ "SigType" SG_ 2583641895 BatCoolTemp 1;
BA_ "CI_ParId" SG_ 2566910273 DevName "I1000";
BA_ "CI_SigId" SG_ 2566910273 DevName 42154;
BA_ "CI_SigName" SG_ 2566910273 DevName "Device Name";
BA_ "SigType" SG_ 2566910273 DevName 8;
BA_ "CI_ParId" SG_ 2566910273 DevIx_FFF141 "I1001";
BA_ "CI_SigId" SG_ 2566910273 DevIx_FFF141 42153;
BA_ "CI_SigName" SG_ 2566910273 DevIx_FFF141 "Device Index";
BA_ "SigType" SG_ 2566910273 DevIx_FFF141 4;
BA_ "CI_ParId" SG_ 2566883879 RngDeterminationRstFdbk "ID2616";
BA_ "CI_SigId" SG_ 2566883879 RngDeterminationRstFdbk 45736;
BA_ "CI_SigName" SG_ 2566883879 RngDeterminationRstFdbk "Range Determination Reset Feedback";
BA_ "GenSigSendType" SG_ 2566883879 RngDeterminationRstFdbk 3;
BA_ "GenSigTimeoutTime_PCM" SG_ 2566883879 RngDeterminationRstFdbk 10000;
BA_ "SigType" SG_ 2566883879 RngDeterminationRstFdbk 4;
BA_ "CI_ParId" SG_ 2566883879 DrivProfIdFdbk "ID2615";
BA_ "CI_SigId" SG_ 2566883879 DrivProfIdFdbk 45735;
BA_ "CI_SigName" SG_ 2566883879 DrivProfIdFdbk "Driver Profile ID Feedback";
BA_ "GenSigSendType" SG_ 2566883879 DrivProfIdFdbk 3;
BA_ "GenSigTimeoutTime_PCM" SG_ 2566883879 DrivProfIdFdbk 10000;
BA_ "CI_ParId" SG_ 2566883914 RegenBrkModeProf "ID2614";
BA_ "CI_SigId" SG_ 2566883914 RegenBrkModeProf 45717;
BA_ "CI_SigName" SG_ 2566883914 RegenBrkModeProf "Regenerative Brake Mode Profile";
BA_ "CI_ParId" SG_ 2566883914 TractModeProf "ID2613";
BA_ "CI_SigId" SG_ 2566883914 TractModeProf 45716;
BA_ "CI_SigName" SG_ 2566883914 TractModeProf "Traction Mode Profile";
BA_ "CI_ParId" SG_ 2566883914 RngDeterminationRst "ID2612";
BA_ "CI_SigId" SG_ 2566883914 RngDeterminationRst 45715;
BA_ "CI_SigName" SG_ 2566883914 RngDeterminationRst "Range Determination Reset";
BA_ "SigType" SG_ 2566883914 RngDeterminationRst 4;
BA_ "CI_ParId" SG_ 2566883914 DrivProfId "ID2611";
BA_ "CI_SigId" SG_ 2566883914 DrivProfId 45714;
BA_ "CI_SigName" SG_ 2566883914 DrivProfId "Driver Profile ID";
BA_ "CI_ParId" SG_ 2566849774 CodriverVdoPersDataCons "V098";
BA_ "CI_SigId" SG_ 2566849774 CodriverVdoPersDataCons 1780;
BA_ "CI_SigName" SG_ 2566849774 CodriverVdoPersDataCons "Codriver VDO Personal Data Consent";
BA_ "CI_ParId" SG_ 2566849774 DrivVdoPersDataCons "V097";
BA_ "CI_SigId" SG_ 2566849774 DrivVdoPersDataCons 1779;
BA_ "CI_SigName" SG_ 2566849774 DrivVdoPersDataCons "Driver VDO Personal Data Consent";
BA_ "CI_ParId" SG_ 2566849774 CodriverItsPersDataCons "V096";
BA_ "CI_SigId" SG_ 2566849774 CodriverItsPersDataCons 1778;
BA_ "CI_SigName" SG_ 2566849774 CodriverItsPersDataCons "Codriver ITS Personal Data Consent";
BA_ "CI_ParId" SG_ 2566849774 DrivItsPersDataCons "V095";
BA_ "CI_SigId" SG_ 2566849774 DrivItsPersDataCons 1777;
BA_ "CI_SigName" SG_ 2566849774 DrivItsPersDataCons "Driver ITS Personal Data Consent";
BA_ "CI_ParId" SG_ 2566865994 DseIxBenf_10 "I794";
BA_ "CI_SigId" SG_ 2566865994 DseIxBenf_10 4967;
BA_ "CI_SigName" SG_ 2566865994 DseIxBenf_10 "DSE Index - Benefit � 10";
BA_ "GenSigSendType" SG_ 2566865994 DseIxBenf_10 3;
BA_ "GenSigTimeoutTime_SGW" SG_ 2566865994 DseIxBenf_10 50000;
BA_ "CI_ParId" SG_ 2566865994 DseIxVal_10 "I784";
BA_ "CI_SigId" SG_ 2566865994 DseIxVal_10 4966;
BA_ "CI_SigName" SG_ 2566865994 DseIxVal_10 "DSE Index - Value � 10";
BA_ "GenSigSendType" SG_ 2566865994 DseIxVal_10 3;
BA_ "GenSigTimeoutTime_SGW" SG_ 2566865994 DseIxVal_10 50000;
BA_ "CI_ParId" SG_ 2566865994 DseIxFrzSts_10 "I774";
BA_ "CI_SigId" SG_ 2566865994 DseIxFrzSts_10 4965;
BA_ "CI_SigName" SG_ 2566865994 DseIxFrzSts_10 "DSE Index - Freeze Status � 10";
BA_ "GenSigSendType" SG_ 2566865994 DseIxFrzSts_10 3;
BA_ "GenSigTimeoutTime_SGW" SG_ 2566865994 DseIxFrzSts_10 50000;
BA_ "SigType" SG_ 2566865994 DseIxFrzSts_10 4;
BA_ "CI_ParId" SG_ 2566865994 DseIxTrend_10 "I764";
BA_ "CI_SigId" SG_ 2566865994 DseIxTrend_10 4964;
BA_ "CI_SigName" SG_ 2566865994 DseIxTrend_10 "DSE Index - Trend � 10";
BA_ "GenSigSendType" SG_ 2566865994 DseIxTrend_10 3;
BA_ "GenSigTimeoutTime_SGW" SG_ 2566865994 DseIxTrend_10 50000;
BA_ "SigType" SG_ 2566865994 DseIxTrend_10 4;
BA_ "CI_ParId" SG_ 2566865994 DseIxBenf_9 "I793";
BA_ "CI_SigId" SG_ 2566865994 DseIxBenf_9 4963;
BA_ "CI_SigName" SG_ 2566865994 DseIxBenf_9 "DSE Index - Benefit � 9";
BA_ "GenSigSendType" SG_ 2566865994 DseIxBenf_9 3;
BA_ "GenSigTimeoutTime_SGW" SG_ 2566865994 DseIxBenf_9 50000;
BA_ "CI_ParId" SG_ 2566865994 DseIxVal_9 "I783";
BA_ "CI_SigId" SG_ 2566865994 DseIxVal_9 4962;
BA_ "CI_SigName" SG_ 2566865994 DseIxVal_9 "DSE Index - Value � 9";
BA_ "GenSigSendType" SG_ 2566865994 DseIxVal_9 3;
BA_ "GenSigTimeoutTime_SGW" SG_ 2566865994 DseIxVal_9 50000;
BA_ "CI_ParId" SG_ 2566865994 DseIxFrzSts_9 "I773";
BA_ "CI_SigId" SG_ 2566865994 DseIxFrzSts_9 4961;
BA_ "CI_SigName" SG_ 2566865994 DseIxFrzSts_9 "DSE Index - Freeze Status � 9";
BA_ "GenSigSendType" SG_ 2566865994 DseIxFrzSts_9 3;
BA_ "GenSigTimeoutTime_SGW" SG_ 2566865994 DseIxFrzSts_9 50000;
BA_ "SigType" SG_ 2566865994 DseIxFrzSts_9 4;
BA_ "CI_ParId" SG_ 2566865994 DseIxTrend_9 "I763";
BA_ "CI_SigId" SG_ 2566865994 DseIxTrend_9 4960;
BA_ "CI_SigName" SG_ 2566865994 DseIxTrend_9 "DSE Index - Trend � 9";
BA_ "GenSigSendType" SG_ 2566865994 DseIxTrend_9 3;
BA_ "GenSigTimeoutTime_SGW" SG_ 2566865994 DseIxTrend_9 50000;
BA_ "SigType" SG_ 2566865994 DseIxTrend_9 4;
BA_ "CI_ParId" SG_ 2566865994 DseIxBenf_8 "I792";
BA_ "CI_SigId" SG_ 2566865994 DseIxBenf_8 4959;
BA_ "CI_SigName" SG_ 2566865994 DseIxBenf_8 "DSE Index - Benefit � 8";
BA_ "GenSigSendType" SG_ 2566865994 DseIxBenf_8 3;
BA_ "GenSigTimeoutTime_SGW" SG_ 2566865994 DseIxBenf_8 50000;
BA_ "CI_ParId" SG_ 2566865994 DseIxVal_8 "I782";
BA_ "CI_SigId" SG_ 2566865994 DseIxVal_8 4958;
BA_ "CI_SigName" SG_ 2566865994 DseIxVal_8 "DSE Index - Value � 8";
BA_ "GenSigSendType" SG_ 2566865994 DseIxVal_8 3;
BA_ "GenSigTimeoutTime_SGW" SG_ 2566865994 DseIxVal_8 50000;
BA_ "CI_ParId" SG_ 2566865994 DseIxFrzSts_8 "I772";
BA_ "CI_SigId" SG_ 2566865994 DseIxFrzSts_8 4957;
BA_ "CI_SigName" SG_ 2566865994 DseIxFrzSts_8 "DSE Index - Freeze Status � 8";
BA_ "GenSigSendType" SG_ 2566865994 DseIxFrzSts_8 3;
BA_ "GenSigTimeoutTime_SGW" SG_ 2566865994 DseIxFrzSts_8 50000;
BA_ "SigType" SG_ 2566865994 DseIxFrzSts_8 4;
BA_ "CI_ParId" SG_ 2566865994 DseIxTrend_8 "I762";
BA_ "CI_SigId" SG_ 2566865994 DseIxTrend_8 4956;
BA_ "CI_SigName" SG_ 2566865994 DseIxTrend_8 "DSE Index - Trend � 8";
BA_ "GenSigSendType" SG_ 2566865994 DseIxTrend_8 3;
BA_ "GenSigTimeoutTime_SGW" SG_ 2566865994 DseIxTrend_8 50000;
BA_ "SigType" SG_ 2566865994 DseIxTrend_8 4;
BA_ "CI_ParId" SG_ 2566865994 DseIxBenf_7 "I791";
BA_ "CI_SigId" SG_ 2566865994 DseIxBenf_7 4955;
BA_ "CI_SigName" SG_ 2566865994 DseIxBenf_7 "DSE Index - Benefit � 7";
BA_ "GenSigSendType" SG_ 2566865994 DseIxBenf_7 3;
BA_ "GenSigTimeoutTime_SGW" SG_ 2566865994 DseIxBenf_7 50000;
BA_ "CI_ParId" SG_ 2566865994 DseIxVal_7 "I781";
BA_ "CI_SigId" SG_ 2566865994 DseIxVal_7 4954;
BA_ "CI_SigName" SG_ 2566865994 DseIxVal_7 "DSE Index - Value � 7";
BA_ "GenSigSendType" SG_ 2566865994 DseIxVal_7 3;
BA_ "GenSigTimeoutTime_SGW" SG_ 2566865994 DseIxVal_7 50000;
BA_ "CI_ParId" SG_ 2566865994 DseIxFrzSts_7 "I771";
BA_ "CI_SigId" SG_ 2566865994 DseIxFrzSts_7 4953;
BA_ "CI_SigName" SG_ 2566865994 DseIxFrzSts_7 "DSE Index - Freeze Status � 7";
BA_ "GenSigSendType" SG_ 2566865994 DseIxFrzSts_7 3;
BA_ "GenSigTimeoutTime_SGW" SG_ 2566865994 DseIxFrzSts_7 50000;
BA_ "SigType" SG_ 2566865994 DseIxFrzSts_7 4;
BA_ "CI_ParId" SG_ 2566865994 DseIxTrend_7 "I761";
BA_ "CI_SigId" SG_ 2566865994 DseIxTrend_7 4952;
BA_ "CI_SigName" SG_ 2566865994 DseIxTrend_7 "DSE Index - Trend � 7";
BA_ "GenSigSendType" SG_ 2566865994 DseIxTrend_7 3;
BA_ "GenSigTimeoutTime_SGW" SG_ 2566865994 DseIxTrend_7 50000;
BA_ "SigType" SG_ 2566865994 DseIxTrend_7 4;
BA_ "CI_ParId" SG_ 2566865994 DseIxBenf_6 "I790";
BA_ "CI_SigId" SG_ 2566865994 DseIxBenf_6 4951;
BA_ "CI_SigName" SG_ 2566865994 DseIxBenf_6 "DSE Index - Benefit � 6";
BA_ "GenSigSendType" SG_ 2566865994 DseIxBenf_6 3;
BA_ "GenSigTimeoutTime_SGW" SG_ 2566865994 DseIxBenf_6 50000;
BA_ "CI_ParId" SG_ 2566865994 DseIxVal_6 "I780";
BA_ "CI_SigId" SG_ 2566865994 DseIxVal_6 4950;
BA_ "CI_SigName" SG_ 2566865994 DseIxVal_6 "DSE Index - Value � 6";
BA_ "GenSigSendType" SG_ 2566865994 DseIxVal_6 3;
BA_ "GenSigTimeoutTime_SGW" SG_ 2566865994 DseIxVal_6 50000;
BA_ "CI_ParId" SG_ 2566865994 DseIxFrzSts_6 "I770";
BA_ "CI_SigId" SG_ 2566865994 DseIxFrzSts_6 4949;
BA_ "CI_SigName" SG_ 2566865994 DseIxFrzSts_6 "DSE Index - Freeze Status � 6";
BA_ "GenSigSendType" SG_ 2566865994 DseIxFrzSts_6 3;
BA_ "GenSigTimeoutTime_SGW" SG_ 2566865994 DseIxFrzSts_6 50000;
BA_ "SigType" SG_ 2566865994 DseIxFrzSts_6 4;
BA_ "CI_ParId" SG_ 2566865994 DseIxTrend_6 "I760";
BA_ "CI_SigId" SG_ 2566865994 DseIxTrend_6 4948;
BA_ "CI_SigName" SG_ 2566865994 DseIxTrend_6 "DSE Index - Trend � 6";
BA_ "GenSigSendType" SG_ 2566865994 DseIxTrend_6 3;
BA_ "GenSigTimeoutTime_SGW" SG_ 2566865994 DseIxTrend_6 50000;
BA_ "SigType" SG_ 2566865994 DseIxTrend_6 4;
BA_ "CI_ParId" SG_ 2566865994 DseIxBenf_5 "I789";
BA_ "CI_SigId" SG_ 2566865994 DseIxBenf_5 4947;
BA_ "CI_SigName" SG_ 2566865994 DseIxBenf_5 "DSE Index - Benefit � 5";
BA_ "GenSigSendType" SG_ 2566865994 DseIxBenf_5 3;
BA_ "GenSigTimeoutTime_SGW" SG_ 2566865994 DseIxBenf_5 50000;
BA_ "CI_ParId" SG_ 2566865994 DseIxVal_5 "I779";
BA_ "CI_SigId" SG_ 2566865994 DseIxVal_5 4946;
BA_ "CI_SigName" SG_ 2566865994 DseIxVal_5 "DSE Index - Value � 5";
BA_ "GenSigSendType" SG_ 2566865994 DseIxVal_5 3;
BA_ "GenSigTimeoutTime_SGW" SG_ 2566865994 DseIxVal_5 50000;
BA_ "CI_ParId" SG_ 2566865994 DseIxFrzSts_5 "I769";
BA_ "CI_SigId" SG_ 2566865994 DseIxFrzSts_5 4945;
BA_ "CI_SigName" SG_ 2566865994 DseIxFrzSts_5 "DSE Index - Freeze Status � 5";
BA_ "GenSigSendType" SG_ 2566865994 DseIxFrzSts_5 3;
BA_ "GenSigTimeoutTime_SGW" SG_ 2566865994 DseIxFrzSts_5 50000;
BA_ "SigType" SG_ 2566865994 DseIxFrzSts_5 4;
BA_ "CI_ParId" SG_ 2566865994 DseIxTrend_5 "I759";
BA_ "CI_SigId" SG_ 2566865994 DseIxTrend_5 4944;
BA_ "CI_SigName" SG_ 2566865994 DseIxTrend_5 "DSE Index - Trend � 5";
BA_ "GenSigSendType" SG_ 2566865994 DseIxTrend_5 3;
BA_ "GenSigTimeoutTime_SGW" SG_ 2566865994 DseIxTrend_5 50000;
BA_ "SigType" SG_ 2566865994 DseIxTrend_5 4;
BA_ "CI_ParId" SG_ 2566865994 DseIxBenf_4 "I788";
BA_ "CI_SigId" SG_ 2566865994 DseIxBenf_4 4943;
BA_ "CI_SigName" SG_ 2566865994 DseIxBenf_4 "DSE Index - Benefit � 4";
BA_ "GenSigSendType" SG_ 2566865994 DseIxBenf_4 3;
BA_ "GenSigTimeoutTime_SGW" SG_ 2566865994 DseIxBenf_4 50000;
BA_ "CI_ParId" SG_ 2566865994 DseIxVal_4 "I778";
BA_ "CI_SigId" SG_ 2566865994 DseIxVal_4 4942;
BA_ "CI_SigName" SG_ 2566865994 DseIxVal_4 "DSE Index - Value � 4";
BA_ "GenSigSendType" SG_ 2566865994 DseIxVal_4 3;
BA_ "GenSigTimeoutTime_SGW" SG_ 2566865994 DseIxVal_4 50000;
BA_ "CI_ParId" SG_ 2566865994 DseIxFrzSts_4 "I768";
BA_ "CI_SigId" SG_ 2566865994 DseIxFrzSts_4 4941;
BA_ "CI_SigName" SG_ 2566865994 DseIxFrzSts_4 "DSE Index - Freeze Status � 4";
BA_ "GenSigSendType" SG_ 2566865994 DseIxFrzSts_4 3;
BA_ "GenSigTimeoutTime_SGW" SG_ 2566865994 DseIxFrzSts_4 50000;
BA_ "SigType" SG_ 2566865994 DseIxFrzSts_4 4;
BA_ "CI_ParId" SG_ 2566865994 DseIxTrend_4 "I758";
BA_ "CI_SigId" SG_ 2566865994 DseIxTrend_4 4940;
BA_ "CI_SigName" SG_ 2566865994 DseIxTrend_4 "DSE Index - Trend � 4";
BA_ "GenSigSendType" SG_ 2566865994 DseIxTrend_4 3;
BA_ "GenSigTimeoutTime_SGW" SG_ 2566865994 DseIxTrend_4 50000;
BA_ "SigType" SG_ 2566865994 DseIxTrend_4 4;
BA_ "CI_ParId" SG_ 2566865994 DseIxBenf_3_EngUse "I787";
BA_ "CI_SigId" SG_ 2566865994 DseIxBenf_3_EngUse 4939;
BA_ "CI_SigName" SG_ 2566865994 DseIxBenf_3_EngUse "DSE Index - Benefit � 3 � Engine Use";
BA_ "GenSigSendType" SG_ 2566865994 DseIxBenf_3_EngUse 3;
BA_ "GenSigTimeoutTime_SGW" SG_ 2566865994 DseIxBenf_3_EngUse 50000;
BA_ "CI_ParId" SG_ 2566865994 DseIxVal_3_EngUse "I777";
BA_ "CI_SigId" SG_ 2566865994 DseIxVal_3_EngUse 4938;
BA_ "CI_SigName" SG_ 2566865994 DseIxVal_3_EngUse "DSE Index - Value � 3 � Engine Use";
BA_ "GenSigSendType" SG_ 2566865994 DseIxVal_3_EngUse 3;
BA_ "GenSigTimeoutTime_SGW" SG_ 2566865994 DseIxVal_3_EngUse 50000;
BA_ "CI_ParId" SG_ 2566865994 DseIxFrzSts_3_EngUse "I767";
BA_ "CI_SigId" SG_ 2566865994 DseIxFrzSts_3_EngUse 4937;
BA_ "CI_SigName" SG_ 2566865994 DseIxFrzSts_3_EngUse "DSE Index - Freeze Status � 3 � Engine Use";
BA_ "GenSigSendType" SG_ 2566865994 DseIxFrzSts_3_EngUse 3;
BA_ "GenSigTimeoutTime_SGW" SG_ 2566865994 DseIxFrzSts_3_EngUse 50000;
BA_ "SigType" SG_ 2566865994 DseIxFrzSts_3_EngUse 4;
BA_ "CI_ParId" SG_ 2566865994 DseIxTrend_3_EngUse "I757";
BA_ "CI_SigId" SG_ 2566865994 DseIxTrend_3_EngUse 4936;
BA_ "CI_SigName" SG_ 2566865994 DseIxTrend_3_EngUse "DSE Index - Trend � 3 � Engine Use";
BA_ "GenSigSendType" SG_ 2566865994 DseIxTrend_3_EngUse 3;
BA_ "GenSigTimeoutTime_SGW" SG_ 2566865994 DseIxTrend_3_EngUse 50000;
BA_ "SigType" SG_ 2566865994 DseIxTrend_3_EngUse 4;
BA_ "CI_ParId" SG_ 2566865994 DseIxBenf_2_Decel "I786";
BA_ "CI_SigId" SG_ 2566865994 DseIxBenf_2_Decel 4935;
BA_ "CI_SigName" SG_ 2566865994 DseIxBenf_2_Decel "DSE Index - Benefit � 2 � Deceleration";
BA_ "GenSigSendType" SG_ 2566865994 DseIxBenf_2_Decel 3;
BA_ "GenSigTimeoutTime_SGW" SG_ 2566865994 DseIxBenf_2_Decel 50000;
BA_ "CI_ParId" SG_ 2566865994 DseIxVal_2_Decel "I776";
BA_ "CI_SigId" SG_ 2566865994 DseIxVal_2_Decel 4934;
BA_ "CI_SigName" SG_ 2566865994 DseIxVal_2_Decel "DSE Index - Value � 2 � Deceleration";
BA_ "GenSigSendType" SG_ 2566865994 DseIxVal_2_Decel 3;
BA_ "GenSigTimeoutTime_SGW" SG_ 2566865994 DseIxVal_2_Decel 50000;
BA_ "CI_ParId" SG_ 2566865994 DseIxFrzSts_2_Decel "I766";
BA_ "CI_SigId" SG_ 2566865994 DseIxFrzSts_2_Decel 4933;
BA_ "CI_SigName" SG_ 2566865994 DseIxFrzSts_2_Decel "DSE Index - Freeze Status � 2 � Deceleration";
BA_ "GenSigSendType" SG_ 2566865994 DseIxFrzSts_2_Decel 3;
BA_ "GenSigTimeoutTime_SGW" SG_ 2566865994 DseIxFrzSts_2_Decel 50000;
BA_ "SigType" SG_ 2566865994 DseIxFrzSts_2_Decel 4;
BA_ "CI_ParId" SG_ 2566865994 DseIxTrend_2_Decel "I756";
BA_ "CI_SigId" SG_ 2566865994 DseIxTrend_2_Decel 4932;
BA_ "CI_SigName" SG_ 2566865994 DseIxTrend_2_Decel "DSE Index - Trend � 2 � Deceleration";
BA_ "GenSigSendType" SG_ 2566865994 DseIxTrend_2_Decel 3;
BA_ "GenSigTimeoutTime_SGW" SG_ 2566865994 DseIxTrend_2_Decel 50000;
BA_ "SigType" SG_ 2566865994 DseIxTrend_2_Decel 4;
BA_ "CI_ParId" SG_ 2566865994 DseIxBenf_1_Accel "I785";
BA_ "CI_SigId" SG_ 2566865994 DseIxBenf_1_Accel 4931;
BA_ "CI_SigName" SG_ 2566865994 DseIxBenf_1_Accel "DSE Index - Benefit � 1 � Acceleration";
BA_ "GenSigSendType" SG_ 2566865994 DseIxBenf_1_Accel 3;
BA_ "GenSigTimeoutTime_SGW" SG_ 2566865994 DseIxBenf_1_Accel 50000;
BA_ "CI_ParId" SG_ 2566865994 DseIxVal_1_Accel "I775";
BA_ "CI_SigId" SG_ 2566865994 DseIxVal_1_Accel 4930;
BA_ "CI_SigName" SG_ 2566865994 DseIxVal_1_Accel "DSE Index - Value � 1 � Acceleration";
BA_ "GenSigSendType" SG_ 2566865994 DseIxVal_1_Accel 3;
BA_ "GenSigTimeoutTime_SGW" SG_ 2566865994 DseIxVal_1_Accel 50000;
BA_ "CI_ParId" SG_ 2566865994 DseIxFrzSts_1_Accel "I765";
BA_ "CI_SigId" SG_ 2566865994 DseIxFrzSts_1_Accel 4929;
BA_ "CI_SigName" SG_ 2566865994 DseIxFrzSts_1_Accel "DSE Index - Freeze Status � 1 � Acceleration";
BA_ "GenSigSendType" SG_ 2566865994 DseIxFrzSts_1_Accel 3;
BA_ "GenSigTimeoutTime_SGW" SG_ 2566865994 DseIxFrzSts_1_Accel 50000;
BA_ "SigType" SG_ 2566865994 DseIxFrzSts_1_Accel 4;
BA_ "CI_ParId" SG_ 2566865994 DseIxTrend_1_Accel "I755";
BA_ "CI_SigId" SG_ 2566865994 DseIxTrend_1_Accel 4928;
BA_ "CI_SigName" SG_ 2566865994 DseIxTrend_1_Accel "DSE Index - Trend � 1 � Acceleration";
BA_ "GenSigSendType" SG_ 2566865994 DseIxTrend_1_Accel 3;
BA_ "GenSigTimeoutTime_SGW" SG_ 2566865994 DseIxTrend_1_Accel 50000;
BA_ "SigType" SG_ 2566865994 DseIxTrend_1_Accel 4;
BA_ "CI_ParId" SG_ 2566865994 DseEvalTime "I753";
BA_ "CI_SigId" SG_ 2566865994 DseEvalTime 4927;
BA_ "CI_SigName" SG_ 2566865994 DseEvalTime "DSE Evaluated Time";
BA_ "GenSigSendType" SG_ 2566865994 DseEvalTime 3;
BA_ "GenSigTimeoutTime_SGW" SG_ 2566865994 DseEvalTime 50000;
BA_ "SigType" SG_ 2566865994 DseEvalTime 1;
BA_ "CI_ParId" SG_ 2566865994 DseEvalDist "I752";
BA_ "CI_SigId" SG_ 2566865994 DseEvalDist 4926;
BA_ "CI_SigName" SG_ 2566865994 DseEvalDist "DSE Evaluated Distance";
BA_ "GenSigSendType" SG_ 2566865994 DseEvalDist 3;
BA_ "GenSigTimeoutTime_SGW" SG_ 2566865994 DseEvalDist 50000;
BA_ "SigType" SG_ 2566865994 DseEvalDist 1;
BA_ "CI_ParId" SG_ 2566865994 DseStartMissTs "I754";
BA_ "CI_SigId" SG_ 2566865994 DseStartMissTs 4925;
BA_ "CI_SigName" SG_ 2566865994 DseStartMissTs "DSE Start Mission Timestamp";
BA_ "GenSigSendType" SG_ 2566865994 DseStartMissTs 3;
BA_ "GenSigTimeoutTime_SGW" SG_ 2566865994 DseStartMissTs 50000;
BA_ "CI_ParId" SG_ 2566865994 DsePopupIx "I751";
BA_ "CI_SigId" SG_ 2566865994 DsePopupIx 4924;
BA_ "CI_SigName" SG_ 2566865994 DsePopupIx "DSE Popup Index";
BA_ "GenSigSendType" SG_ 2566865994 DsePopupIx 3;
BA_ "GenSigTimeoutTime_SGW" SG_ 2566865994 DsePopupIx 50000;
BA_ "CI_ParId" SG_ 2566865994 DsePopupIcon "I750";
BA_ "CI_SigId" SG_ 2566865994 DsePopupIcon 4923;
BA_ "CI_SigName" SG_ 2566865994 DsePopupIcon "DSE Popup Icon";
BA_ "GenSigSendType" SG_ 2566865994 DsePopupIcon 3;
BA_ "GenSigTimeoutTime_SGW" SG_ 2566865994 DsePopupIcon 50000;
BA_ "CI_ParId" SG_ 2566865994 DseSts "I749";
BA_ "CI_SigId" SG_ 2566865994 DseSts 4922;
BA_ "CI_SigName" SG_ 2566865994 DseSts "DSE Status";
BA_ "GenSigSendType" SG_ 2566865994 DseSts 3;
BA_ "GenSigTimeoutTime_SGW" SG_ 2566865994 DseSts 50000;
BA_ "CI_ParId" SG_ 2583650122 WtEnergy "ID1565";
BA_ "CI_SigId" SG_ 2583650122 WtEnergy 39155;
BA_ "CI_SigName" SG_ 2583650122 WtEnergy "Weight Energy";
BA_ "GenSigTimeoutTime_SGW" SG_ 2583650122 WtEnergy 5000;
BA_ "CI_ParId" SG_ 2583650122 BenfEnergy "ID1564";
BA_ "CI_SigId" SG_ 2583650122 BenfEnergy 39154;
BA_ "CI_SigName" SG_ 2583650122 BenfEnergy "Benefit Energy";
BA_ "GenSigTimeoutTime_SGW" SG_ 2583650122 BenfEnergy 5000;
BA_ "SigType" SG_ 2583650122 BenfEnergy 4;
BA_ "CI_ParId" SG_ 2583650122 TrendEnergy "ID1563";
BA_ "CI_SigId" SG_ 2583650122 TrendEnergy 39153;
BA_ "CI_SigName" SG_ 2583650122 TrendEnergy "Trend Energy";
BA_ "GenSigTimeoutTime_SGW" SG_ 2583650122 TrendEnergy 5000;
BA_ "SigType" SG_ 2583650122 TrendEnergy 4;
BA_ "CI_ParId" SG_ 2583650122 ValEnergy "ID1562";
BA_ "CI_SigId" SG_ 2583650122 ValEnergy 39152;
BA_ "CI_SigName" SG_ 2583650122 ValEnergy "Valid Energy";
BA_ "GenSigStartValue" SG_ 2583650122 ValEnergy 3;
BA_ "GenSigTimeoutTime_SGW" SG_ 2583650122 ValEnergy 5000;
BA_ "SigType" SG_ 2583650122 ValEnergy 4;
BA_ "CI_ParId" SG_ 2583650122 ScoreEnergy "ID1561";
BA_ "CI_SigId" SG_ 2583650122 ScoreEnergy 39151;
BA_ "CI_SigName" SG_ 2583650122 ScoreEnergy "Score Energy";
BA_ "GenSigTimeoutTime_SGW" SG_ 2583650122 ScoreEnergy 5000;
BA_ "CI_ParId" SG_ 2566895690 TsTripStart "IS877";
BA_ "CI_SigId" SG_ 2566895690 TsTripStart 4975;
BA_ "CI_SigName" SG_ 2566895690 TsTripStart "Timestamp Trip Start";
BA_ "SigType" SG_ 2566895690 TsTripStart 1;
BA_ "CI_ParId" SG_ 2566895690 OdoTripStart "IS876";
BA_ "CI_SigId" SG_ 2566895690 OdoTripStart 4974;
BA_ "CI_SigName" SG_ 2566895690 OdoTripStart "Odometer Trip Start";
BA_ "SigType" SG_ 2566895690 OdoTripStart 1;
BA_ "CI_ParId" SG_ 2566895946 TripEndReas "IS881";
BA_ "CI_SigId" SG_ 2566895946 TripEndReas 4972;
BA_ "CI_SigName" SG_ 2566895946 TripEndReas "Trip End Reason";
BA_ "CI_ParId" SG_ 2566895946 TripActv "IS880";
BA_ "CI_SigId" SG_ 2566895946 TripActv 4971;
BA_ "CI_SigName" SG_ 2566895946 TripActv "Trip Active";
BA_ "SigType" SG_ 2566895946 TripActv 4;
BA_ "CI_ParId" SG_ 2566895946 TripEnded "IS879";
BA_ "CI_SigId" SG_ 2566895946 TripEnded 4970;
BA_ "CI_SigName" SG_ 2566895946 TripEnded "Trip Ended";
BA_ "SigType" SG_ 2566895946 TripEnded 4;
BA_ "CI_ParId" SG_ 2566895946 TripStarted "IS878";
BA_ "CI_SigId" SG_ 2566895946 TripStarted 4969;
BA_ "CI_SigName" SG_ 2566895946 TripStarted "Trip Started";
BA_ "SigType" SG_ 2566895946 TripStarted 4;
BA_ "CI_ParId" SG_ 2650777222 DsgBelowNeg20_h "MV021";
BA_ "CI_SigId" SG_ 2650777222 DsgBelowNeg20_h 44086;
BA_ "CI_SigName" SG_ 2650777222 DsgBelowNeg20_h "DsgBelowNeg20_h";
BA_ "GenSigTimeoutTime_PCM" SG_ 2650777222 DsgBelowNeg20_h 3000000;
BA_ "SigType" SG_ 2650777222 DsgBelowNeg20_h 1;
BA_ "CI_ParId" SG_ 2650777222 DsgBelowNeg10_h "MV020";
BA_ "CI_SigId" SG_ 2650777222 DsgBelowNeg10_h 44085;
BA_ "CI_SigName" SG_ 2650777222 DsgBelowNeg10_h "DsgBelowNeg10_h";
BA_ "GenSigTimeoutTime_PCM" SG_ 2650777222 DsgBelowNeg10_h 3000000;
BA_ "SigType" SG_ 2650777222 DsgBelowNeg10_h 1;
BA_ "CI_ParId" SG_ 2650777222 DsgBelow0_h "MV019";
BA_ "CI_SigId" SG_ 2650777222 DsgBelow0_h 44084;
BA_ "CI_SigName" SG_ 2650777222 DsgBelow0_h "DsgBelow0_h";
BA_ "GenSigTimeoutTime_PCM" SG_ 2650777222 DsgBelow0_h 3000000;
BA_ "SigType" SG_ 2650777222 DsgBelow0_h 1;
BA_ "CI_ParId" SG_ 2650777222 DsgOver0_h "MV018";
BA_ "CI_SigId" SG_ 2650777222 DsgOver0_h 44083;
BA_ "CI_SigName" SG_ 2650777222 DsgOver0_h "DsgOver0_h";
BA_ "GenSigTimeoutTime_PCM" SG_ 2650777222 DsgOver0_h 3000000;
BA_ "SigType" SG_ 2650777222 DsgOver0_h 1;
BA_ "CI_ParId" SG_ 2650777222 DsgOver15_h "MV017";
BA_ "CI_SigId" SG_ 2650777222 DsgOver15_h 44082;
BA_ "CI_SigName" SG_ 2650777222 DsgOver15_h "DsgOver15_h";
BA_ "GenSigTimeoutTime_PCM" SG_ 2650777222 DsgOver15_h 3000000;
BA_ "SigType" SG_ 2650777222 DsgOver15_h 1;
BA_ "CI_ParId" SG_ 2650777222 DsgOver30_h "MV016";
BA_ "CI_SigId" SG_ 2650777222 DsgOver30_h 44081;
BA_ "CI_SigName" SG_ 2650777222 DsgOver30_h "DsgOver30_h";
BA_ "GenSigTimeoutTime_PCM" SG_ 2650777222 DsgOver30_h 3000000;
BA_ "SigType" SG_ 2650777222 DsgOver30_h 1;
BA_ "CI_ParId" SG_ 2650777222 DsgOver35_h "MV015";
BA_ "CI_SigId" SG_ 2650777222 DsgOver35_h 44080;
BA_ "CI_SigName" SG_ 2650777222 DsgOver35_h "DsgOver35_h";
BA_ "GenSigTimeoutTime_PCM" SG_ 2650777222 DsgOver35_h 3000000;
BA_ "SigType" SG_ 2650777222 DsgOver35_h 1;
BA_ "CI_ParId" SG_ 2650777222 DsgOver40_h "MV014";
BA_ "CI_SigId" SG_ 2650777222 DsgOver40_h 44079;
BA_ "CI_SigName" SG_ 2650777222 DsgOver40_h "DsgOver40_h";
BA_ "GenSigTimeoutTime_PCM" SG_ 2650777222 DsgOver40_h 3000000;
BA_ "SigType" SG_ 2650777222 DsgOver40_h 1;
BA_ "CI_ParId" SG_ 2650777222 DsgOver45_h "MV013";
BA_ "CI_SigId" SG_ 2650777222 DsgOver45_h 44078;
BA_ "CI_SigName" SG_ 2650777222 DsgOver45_h "DsgOver45_h";
BA_ "GenSigTimeoutTime_PCM" SG_ 2650777222 DsgOver45_h 3000000;
BA_ "SigType" SG_ 2650777222 DsgOver45_h 1;
BA_ "CI_ParId" SG_ 2650777222 DsgOver55_h "MV012";
BA_ "CI_SigId" SG_ 2650777222 DsgOver55_h 44077;
BA_ "CI_SigName" SG_ 2650777222 DsgOver55_h "DsgOver55_h";
BA_ "GenSigTimeoutTime_PCM" SG_ 2650777222 DsgOver55_h 3000000;
BA_ "SigType" SG_ 2650777222 DsgOver55_h 1;
BA_ "CI_ParId" SG_ 2650777223 DsgBelowNeg20_h_FFA687 "MV021";
BA_ "CI_SigId" SG_ 2650777223 DsgBelowNeg20_h_FFA687 44097;
BA_ "CI_SigName" SG_ 2650777223 DsgBelowNeg20_h_FFA687 "DsgBelowNeg20_h";
BA_ "GenSigTimeoutTime_PCM" SG_ 2650777223 DsgBelowNeg20_h_FFA687 3000000;
BA_ "SigType" SG_ 2650777223 DsgBelowNeg20_h_FFA687 1;
BA_ "CI_ParId" SG_ 2650777223 DsgBelowNeg10_h_FFA687 "MV020";
BA_ "CI_SigId" SG_ 2650777223 DsgBelowNeg10_h_FFA687 44096;
BA_ "CI_SigName" SG_ 2650777223 DsgBelowNeg10_h_FFA687 "DsgBelowNeg10_h";
BA_ "GenSigTimeoutTime_PCM" SG_ 2650777223 DsgBelowNeg10_h_FFA687 3000000;
BA_ "SigType" SG_ 2650777223 DsgBelowNeg10_h_FFA687 1;
BA_ "CI_ParId" SG_ 2650777223 DsgBelow0_h_FFA687 "MV019";
BA_ "CI_SigId" SG_ 2650777223 DsgBelow0_h_FFA687 44095;
BA_ "CI_SigName" SG_ 2650777223 DsgBelow0_h_FFA687 "DsgBelow0_h";
BA_ "GenSigTimeoutTime_PCM" SG_ 2650777223 DsgBelow0_h_FFA687 3000000;
BA_ "SigType" SG_ 2650777223 DsgBelow0_h_FFA687 1;
BA_ "CI_ParId" SG_ 2650777223 DsgOver0_h_FFA687 "MV018";
BA_ "CI_SigId" SG_ 2650777223 DsgOver0_h_FFA687 44094;
BA_ "CI_SigName" SG_ 2650777223 DsgOver0_h_FFA687 "DsgOver0_h";
BA_ "GenSigTimeoutTime_PCM" SG_ 2650777223 DsgOver0_h_FFA687 3000000;
BA_ "SigType" SG_ 2650777223 DsgOver0_h_FFA687 1;
BA_ "CI_ParId" SG_ 2650777223 DsgOver15_h_FFA687 "MV017";
BA_ "CI_SigId" SG_ 2650777223 DsgOver15_h_FFA687 44093;
BA_ "CI_SigName" SG_ 2650777223 DsgOver15_h_FFA687 "DsgOver15_h";
BA_ "GenSigTimeoutTime_PCM" SG_ 2650777223 DsgOver15_h_FFA687 3000000;
BA_ "SigType" SG_ 2650777223 DsgOver15_h_FFA687 1;
BA_ "CI_ParId" SG_ 2650777223 DsgOver30_h_FFA687 "MV016";
BA_ "CI_SigId" SG_ 2650777223 DsgOver30_h_FFA687 44092;
BA_ "CI_SigName" SG_ 2650777223 DsgOver30_h_FFA687 "DsgOver30_h";
BA_ "GenSigTimeoutTime_PCM" SG_ 2650777223 DsgOver30_h_FFA687 3000000;
BA_ "SigType" SG_ 2650777223 DsgOver30_h_FFA687 1;
BA_ "CI_ParId" SG_ 2650777223 DsgOver35_h_FFA687 "MV015";
BA_ "CI_SigId" SG_ 2650777223 DsgOver35_h_FFA687 44091;
BA_ "CI_SigName" SG_ 2650777223 DsgOver35_h_FFA687 "DsgOver35_h";
BA_ "GenSigTimeoutTime_PCM" SG_ 2650777223 DsgOver35_h_FFA687 3000000;
BA_ "SigType" SG_ 2650777223 DsgOver35_h_FFA687 1;
BA_ "CI_ParId" SG_ 2650777223 DsgOver40_h_FFA687 "MV014";
BA_ "CI_SigId" SG_ 2650777223 DsgOver40_h_FFA687 44090;
BA_ "CI_SigName" SG_ 2650777223 DsgOver40_h_FFA687 "DsgOver40_h";
BA_ "GenSigTimeoutTime_PCM" SG_ 2650777223 DsgOver40_h_FFA687 3000000;
BA_ "SigType" SG_ 2650777223 DsgOver40_h_FFA687 1;
BA_ "CI_ParId" SG_ 2650777223 DsgOver45_h_FFA687 "MV013";
BA_ "CI_SigId" SG_ 2650777223 DsgOver45_h_FFA687 44089;
BA_ "CI_SigName" SG_ 2650777223 DsgOver45_h_FFA687 "DsgOver45_h";
BA_ "GenSigTimeoutTime_PCM" SG_ 2650777223 DsgOver45_h_FFA687 3000000;
BA_ "SigType" SG_ 2650777223 DsgOver45_h_FFA687 1;
BA_ "CI_ParId" SG_ 2650777223 DsgOver55_h_FFA687 "MV012";
BA_ "CI_SigId" SG_ 2650777223 DsgOver55_h_FFA687 44088;
BA_ "CI_SigName" SG_ 2650777223 DsgOver55_h_FFA687 "DsgOver55_h";
BA_ "GenSigTimeoutTime_PCM" SG_ 2650777223 DsgOver55_h_FFA687 3000000;
BA_ "SigType" SG_ 2650777223 DsgOver55_h_FFA687 1;
BA_ "CI_ParId" SG_ 2650777332 DsgBelowNeg20_h_FFA6F4 "MV021";
BA_ "CI_SigId" SG_ 2650777332 DsgBelowNeg20_h_FFA6F4 44053;
BA_ "CI_SigName" SG_ 2650777332 DsgBelowNeg20_h_FFA6F4 "DsgBelowNeg20_h";
BA_ "GenSigTimeoutTime_PCM" SG_ 2650777332 DsgBelowNeg20_h_FFA6F4 3000000;
BA_ "SigType" SG_ 2650777332 DsgBelowNeg20_h_FFA6F4 1;
BA_ "CI_ParId" SG_ 2650777332 DsgBelowNeg10_h_FFA6F4 "MV020";
BA_ "CI_SigId" SG_ 2650777332 DsgBelowNeg10_h_FFA6F4 44052;
BA_ "CI_SigName" SG_ 2650777332 DsgBelowNeg10_h_FFA6F4 "DsgBelowNeg10_h";
BA_ "GenSigTimeoutTime_PCM" SG_ 2650777332 DsgBelowNeg10_h_FFA6F4 3000000;
BA_ "SigType" SG_ 2650777332 DsgBelowNeg10_h_FFA6F4 1;
BA_ "CI_ParId" SG_ 2650777332 DsgBelow0_h_FFA6F4 "MV019";
BA_ "CI_SigId" SG_ 2650777332 DsgBelow0_h_FFA6F4 44051;
BA_ "CI_SigName" SG_ 2650777332 DsgBelow0_h_FFA6F4 "DsgBelow0_h";
BA_ "GenSigTimeoutTime_PCM" SG_ 2650777332 DsgBelow0_h_FFA6F4 3000000;
BA_ "SigType" SG_ 2650777332 DsgBelow0_h_FFA6F4 1;
BA_ "CI_ParId" SG_ 2650777332 DsgOver0_h_FFA6F4 "MV018";
BA_ "CI_SigId" SG_ 2650777332 DsgOver0_h_FFA6F4 44050;
BA_ "CI_SigName" SG_ 2650777332 DsgOver0_h_FFA6F4 "DsgOver0_h";
BA_ "GenSigTimeoutTime_PCM" SG_ 2650777332 DsgOver0_h_FFA6F4 3000000;
BA_ "SigType" SG_ 2650777332 DsgOver0_h_FFA6F4 1;
BA_ "CI_ParId" SG_ 2650777332 DsgOver15_h_FFA6F4 "MV017";
BA_ "CI_SigId" SG_ 2650777332 DsgOver15_h_FFA6F4 44049;
BA_ "CI_SigName" SG_ 2650777332 DsgOver15_h_FFA6F4 "DsgOver15_h";
BA_ "GenSigTimeoutTime_PCM" SG_ 2650777332 DsgOver15_h_FFA6F4 3000000;
BA_ "SigType" SG_ 2650777332 DsgOver15_h_FFA6F4 1;
BA_ "CI_ParId" SG_ 2650777332 DsgOver30_h_FFA6F4 "MV016";
BA_ "CI_SigId" SG_ 2650777332 DsgOver30_h_FFA6F4 44048;
BA_ "CI_SigName" SG_ 2650777332 DsgOver30_h_FFA6F4 "DsgOver30_h";
BA_ "GenSigTimeoutTime_PCM" SG_ 2650777332 DsgOver30_h_FFA6F4 3000000;
BA_ "SigType" SG_ 2650777332 DsgOver30_h_FFA6F4 1;
BA_ "CI_ParId" SG_ 2650777332 DsgOver35_h_FFA6F4 "MV015";
BA_ "CI_SigId" SG_ 2650777332 DsgOver35_h_FFA6F4 44047;
BA_ "CI_SigName" SG_ 2650777332 DsgOver35_h_FFA6F4 "DsgOver35_h";
BA_ "GenSigTimeoutTime_PCM" SG_ 2650777332 DsgOver35_h_FFA6F4 3000000;
BA_ "SigType" SG_ 2650777332 DsgOver35_h_FFA6F4 1;
BA_ "CI_ParId" SG_ 2650777332 DsgOver40_h_FFA6F4 "MV014";
BA_ "CI_SigId" SG_ 2650777332 DsgOver40_h_FFA6F4 44046;
BA_ "CI_SigName" SG_ 2650777332 DsgOver40_h_FFA6F4 "DsgOver40_h";
BA_ "GenSigTimeoutTime_PCM" SG_ 2650777332 DsgOver40_h_FFA6F4 3000000;
BA_ "SigType" SG_ 2650777332 DsgOver40_h_FFA6F4 1;
BA_ "CI_ParId" SG_ 2650777332 DsgOver45_h_FFA6F4 "MV013";
BA_ "CI_SigId" SG_ 2650777332 DsgOver45_h_FFA6F4 44045;
BA_ "CI_SigName" SG_ 2650777332 DsgOver45_h_FFA6F4 "DsgOver45_h";
BA_ "GenSigTimeoutTime_PCM" SG_ 2650777332 DsgOver45_h_FFA6F4 3000000;
BA_ "SigType" SG_ 2650777332 DsgOver45_h_FFA6F4 1;
BA_ "CI_ParId" SG_ 2650777332 DsgOver55_h_FFA6F4 "MV012";
BA_ "CI_SigId" SG_ 2650777332 DsgOver55_h_FFA6F4 44044;
BA_ "CI_SigName" SG_ 2650777332 DsgOver55_h_FFA6F4 "DsgOver55_h";
BA_ "GenSigTimeoutTime_PCM" SG_ 2650777332 DsgOver55_h_FFA6F4 3000000;
BA_ "SigType" SG_ 2650777332 DsgOver55_h_FFA6F4 1;
BA_ "CI_ParId" SG_ 2650777333 DsgBelowNeg20_h_FFA6F5 "MV021";
BA_ "CI_SigId" SG_ 2650777333 DsgBelowNeg20_h_FFA6F5 44064;
BA_ "CI_SigName" SG_ 2650777333 DsgBelowNeg20_h_FFA6F5 "DsgBelowNeg20_h";
BA_ "GenSigTimeoutTime_PCM" SG_ 2650777333 DsgBelowNeg20_h_FFA6F5 3000000;
BA_ "SigType" SG_ 2650777333 DsgBelowNeg20_h_FFA6F5 1;
BA_ "CI_ParId" SG_ 2650777333 DsgBelowNeg10_h_FFA6F5 "MV020";
BA_ "CI_SigId" SG_ 2650777333 DsgBelowNeg10_h_FFA6F5 44063;
BA_ "CI_SigName" SG_ 2650777333 DsgBelowNeg10_h_FFA6F5 "DsgBelowNeg10_h";
BA_ "GenSigTimeoutTime_PCM" SG_ 2650777333 DsgBelowNeg10_h_FFA6F5 3000000;
BA_ "SigType" SG_ 2650777333 DsgBelowNeg10_h_FFA6F5 1;
BA_ "CI_ParId" SG_ 2650777333 DsgBelow0_h_FFA6F5 "MV019";
BA_ "CI_SigId" SG_ 2650777333 DsgBelow0_h_FFA6F5 44062;
BA_ "CI_SigName" SG_ 2650777333 DsgBelow0_h_FFA6F5 "DsgBelow0_h";
BA_ "GenSigTimeoutTime_PCM" SG_ 2650777333 DsgBelow0_h_FFA6F5 3000000;
BA_ "SigType" SG_ 2650777333 DsgBelow0_h_FFA6F5 1;
BA_ "CI_ParId" SG_ 2650777333 DsgOver0_h_FFA6F5 "MV018";
BA_ "CI_SigId" SG_ 2650777333 DsgOver0_h_FFA6F5 44061;
BA_ "CI_SigName" SG_ 2650777333 DsgOver0_h_FFA6F5 "DsgOver0_h";
BA_ "GenSigTimeoutTime_PCM" SG_ 2650777333 DsgOver0_h_FFA6F5 3000000;
BA_ "SigType" SG_ 2650777333 DsgOver0_h_FFA6F5 1;
BA_ "CI_ParId" SG_ 2650777333 DsgOver15_h_FFA6F5 "MV017";
BA_ "CI_SigId" SG_ 2650777333 DsgOver15_h_FFA6F5 44060;
BA_ "CI_SigName" SG_ 2650777333 DsgOver15_h_FFA6F5 "DsgOver15_h";
BA_ "GenSigTimeoutTime_PCM" SG_ 2650777333 DsgOver15_h_FFA6F5 3000000;
BA_ "SigType" SG_ 2650777333 DsgOver15_h_FFA6F5 1;
BA_ "CI_ParId" SG_ 2650777333 DsgOver30_h_FFA6F5 "MV016";
BA_ "CI_SigId" SG_ 2650777333 DsgOver30_h_FFA6F5 44059;
BA_ "CI_SigName" SG_ 2650777333 DsgOver30_h_FFA6F5 "DsgOver30_h";
BA_ "GenSigTimeoutTime_PCM" SG_ 2650777333 DsgOver30_h_FFA6F5 3000000;
BA_ "SigType" SG_ 2650777333 DsgOver30_h_FFA6F5 1;
BA_ "CI_ParId" SG_ 2650777333 DsgOver35_h_FFA6F5 "MV015";
BA_ "CI_SigId" SG_ 2650777333 DsgOver35_h_FFA6F5 44058;
BA_ "CI_SigName" SG_ 2650777333 DsgOver35_h_FFA6F5 "DsgOver35_h";
BA_ "GenSigTimeoutTime_PCM" SG_ 2650777333 DsgOver35_h_FFA6F5 3000000;
BA_ "SigType" SG_ 2650777333 DsgOver35_h_FFA6F5 1;
BA_ "CI_ParId" SG_ 2650777333 DsgOver40_h_FFA6F5 "MV014";
BA_ "CI_SigId" SG_ 2650777333 DsgOver40_h_FFA6F5 44057;
BA_ "CI_SigName" SG_ 2650777333 DsgOver40_h_FFA6F5 "DsgOver40_h";
BA_ "GenSigTimeoutTime_PCM" SG_ 2650777333 DsgOver40_h_FFA6F5 3000000;
BA_ "SigType" SG_ 2650777333 DsgOver40_h_FFA6F5 1;
BA_ "CI_ParId" SG_ 2650777333 DsgOver45_h_FFA6F5 "MV013";
BA_ "CI_SigId" SG_ 2650777333 DsgOver45_h_FFA6F5 44056;
BA_ "CI_SigName" SG_ 2650777333 DsgOver45_h_FFA6F5 "DsgOver45_h";
BA_ "GenSigTimeoutTime_PCM" SG_ 2650777333 DsgOver45_h_FFA6F5 3000000;
BA_ "SigType" SG_ 2650777333 DsgOver45_h_FFA6F5 1;
BA_ "CI_ParId" SG_ 2650777333 DsgOver55_h_FFA6F5 "MV012";
BA_ "CI_SigId" SG_ 2650777333 DsgOver55_h_FFA6F5 44055;
BA_ "CI_SigName" SG_ 2650777333 DsgOver55_h_FFA6F5 "DsgOver55_h";
BA_ "GenSigTimeoutTime_PCM" SG_ 2650777333 DsgOver55_h_FFA6F5 3000000;
BA_ "SigType" SG_ 2650777333 DsgOver55_h_FFA6F5 1;
BA_ "CI_ParId" SG_ 2650777334 DsgBelowNeg20_h_FFA6F6 "MV021";
BA_ "CI_SigId" SG_ 2650777334 DsgBelowNeg20_h_FFA6F6 44075;
BA_ "CI_SigName" SG_ 2650777334 DsgBelowNeg20_h_FFA6F6 "DsgBelowNeg20_h";
BA_ "GenSigTimeoutTime_PCM" SG_ 2650777334 DsgBelowNeg20_h_FFA6F6 3000000;
BA_ "SigType" SG_ 2650777334 DsgBelowNeg20_h_FFA6F6 1;
BA_ "CI_ParId" SG_ 2650777334 DsgBelowNeg10_h_FFA6F6 "MV020";
BA_ "CI_SigId" SG_ 2650777334 DsgBelowNeg10_h_FFA6F6 44074;
BA_ "CI_SigName" SG_ 2650777334 DsgBelowNeg10_h_FFA6F6 "DsgBelowNeg10_h";
BA_ "GenSigTimeoutTime_PCM" SG_ 2650777334 DsgBelowNeg10_h_FFA6F6 3000000;
BA_ "SigType" SG_ 2650777334 DsgBelowNeg10_h_FFA6F6 1;
BA_ "CI_ParId" SG_ 2650777334 DsgBelow0_h_FFA6F6 "MV019";
BA_ "CI_SigId" SG_ 2650777334 DsgBelow0_h_FFA6F6 44073;
BA_ "CI_SigName" SG_ 2650777334 DsgBelow0_h_FFA6F6 "DsgBelow0_h";
BA_ "GenSigTimeoutTime_PCM" SG_ 2650777334 DsgBelow0_h_FFA6F6 3000000;
BA_ "SigType" SG_ 2650777334 DsgBelow0_h_FFA6F6 1;
BA_ "CI_ParId" SG_ 2650777334 DsgOver0_h_FFA6F6 "MV018";
BA_ "CI_SigId" SG_ 2650777334 DsgOver0_h_FFA6F6 44072;
BA_ "CI_SigName" SG_ 2650777334 DsgOver0_h_FFA6F6 "DsgOver0_h";
BA_ "GenSigTimeoutTime_PCM" SG_ 2650777334 DsgOver0_h_FFA6F6 3000000;
BA_ "SigType" SG_ 2650777334 DsgOver0_h_FFA6F6 1;
BA_ "CI_ParId" SG_ 2650777334 DsgOver15_h_FFA6F6 "MV017";
BA_ "CI_SigId" SG_ 2650777334 DsgOver15_h_FFA6F6 44071;
BA_ "CI_SigName" SG_ 2650777334 DsgOver15_h_FFA6F6 "DsgOver15_h";
BA_ "GenSigTimeoutTime_PCM" SG_ 2650777334 DsgOver15_h_FFA6F6 3000000;
BA_ "SigType" SG_ 2650777334 DsgOver15_h_FFA6F6 1;
BA_ "CI_ParId" SG_ 2650777334 DsgOver30_h_FFA6F6 "MV016";
BA_ "CI_SigId" SG_ 2650777334 DsgOver30_h_FFA6F6 44070;
BA_ "CI_SigName" SG_ 2650777334 DsgOver30_h_FFA6F6 "DsgOver30_h";
BA_ "GenSigTimeoutTime_PCM" SG_ 2650777334 DsgOver30_h_FFA6F6 3000000;
BA_ "SigType" SG_ 2650777334 DsgOver30_h_FFA6F6 1;
BA_ "CI_ParId" SG_ 2650777334 DsgOver35_h_FFA6F6 "MV015";
BA_ "CI_SigId" SG_ 2650777334 DsgOver35_h_FFA6F6 44069;
BA_ "CI_SigName" SG_ 2650777334 DsgOver35_h_FFA6F6 "DsgOver35_h";
BA_ "GenSigTimeoutTime_PCM" SG_ 2650777334 DsgOver35_h_FFA6F6 3000000;
BA_ "SigType" SG_ 2650777334 DsgOver35_h_FFA6F6 1;
BA_ "CI_ParId" SG_ 2650777334 DsgOver40_h_FFA6F6 "MV014";
BA_ "CI_SigId" SG_ 2650777334 DsgOver40_h_FFA6F6 44068;
BA_ "CI_SigName" SG_ 2650777334 DsgOver40_h_FFA6F6 "DsgOver40_h";
BA_ "GenSigTimeoutTime_PCM" SG_ 2650777334 DsgOver40_h_FFA6F6 3000000;
BA_ "SigType" SG_ 2650777334 DsgOver40_h_FFA6F6 1;
BA_ "CI_ParId" SG_ 2650777334 DsgOver45_h_FFA6F6 "MV013";
BA_ "CI_SigId" SG_ 2650777334 DsgOver45_h_FFA6F6 44067;
BA_ "CI_SigName" SG_ 2650777334 DsgOver45_h_FFA6F6 "DsgOver45_h";
BA_ "GenSigTimeoutTime_PCM" SG_ 2650777334 DsgOver45_h_FFA6F6 3000000;
BA_ "SigType" SG_ 2650777334 DsgOver45_h_FFA6F6 1;
BA_ "CI_ParId" SG_ 2650777334 DsgOver55_h_FFA6F6 "MV012";
BA_ "CI_SigId" SG_ 2650777334 DsgOver55_h_FFA6F6 44066;
BA_ "CI_SigName" SG_ 2650777334 DsgOver55_h_FFA6F6 "DsgOver55_h";
BA_ "GenSigTimeoutTime_PCM" SG_ 2650777334 DsgOver55_h_FFA6F6 3000000;
BA_ "SigType" SG_ 2650777334 DsgOver55_h_FFA6F6 1;
BA_ "CI_ParId" SG_ 2365562112 ActMaxAvRegenPcTrq "ID2511";
BA_ "CI_SigId" SG_ 2365562112 ActMaxAvRegenPcTrq 45392;
BA_ "CI_SigName" SG_ 2365562112 ActMaxAvRegenPcTrq "Actual Maximum Available Regeneration - Percent Torque";
BA_ "GenSigTimeoutTime_PCM" SG_ 2365562112 ActMaxAvRegenPcTrq 500;
BA_ "SigType" SG_ 2365562112 ActMaxAvRegenPcTrq 1;
BA_ "CI_ParId" SG_ 2365562112 EcmTrqCtrlRdySts "ID2483";
BA_ "CI_SigId" SG_ 2365562112 EcmTrqCtrlRdySts 44593;
BA_ "CI_SigName" SG_ 2365562112 EcmTrqCtrlRdySts "ECM Torque Control Readiness Status ";
BA_ "GenSigTimeoutTime_PCM" SG_ 2365562112 EcmTrqCtrlRdySts 500;
BA_ "SigType" SG_ 2365562112 EcmTrqCtrlRdySts 4;
BA_ "CI_ParId" SG_ 2365562112 TransmCurGear_F9D00 "ID2305";
BA_ "CI_SigId" SG_ 2365562112 TransmCurGear_F9D00 42726;
BA_ "CI_SigName" SG_ 2365562112 TransmCurGear_F9D00 "Transmission Current Gear";
BA_ "GenSigTimeoutTime_PCM" SG_ 2365562112 TransmCurGear_F9D00 500;
BA_ "CI_ParId" SG_ 2365562112 EngRefTrq_F9D00 "544";
BA_ "CI_SigId" SG_ 2365562112 EngRefTrq_F9D00 42222;
BA_ "CI_SigName" SG_ 2365562112 EngRefTrq_F9D00 "Engine Reference Torque";
BA_ "GenSigTimeoutTime_PCM" SG_ 2365562112 EngRefTrq_F9D00 500;
BA_ "SPN" SG_ 2365562112 EngRefTrq_F9D00 544;
BA_ "SigType" SG_ 2365562112 EngRefTrq_F9D00 1;
BA_ "CI_ParId" SG_ 2365562112 DSig "ID0329";
BA_ "CI_SigId" SG_ 2365562112 DSig 40398;
BA_ "CI_SigName" SG_ 2365562112 DSig "D Signal";
BA_ "GenSigTimeoutTime_PCM" SG_ 2365562112 DSig 500;
BA_ "CI_ParId" SG_ 2365562112 NeutrSensInfo "ID0973";
BA_ "CI_SigId" SG_ 2365562112 NeutrSensInfo 42391;
BA_ "CI_SigName" SG_ 2365562112 NeutrSensInfo "Neutral Sensor Information";
BA_ "GenSigTimeoutTime_PCM" SG_ 2365562112 NeutrSensInfo 500;
BA_ "SigType" SG_ 2365562112 NeutrSensInfo 4;
BA_ "CI_ParId" SG_ 2365562112 EngSts "ID2187";
BA_ "CI_SigId" SG_ 2365562112 EngSts 42194;
BA_ "CI_SigName" SG_ 2365562112 EngSts "Engine Status";
BA_ "GenSigTimeoutTime_PCM" SG_ 2365562112 EngSts 500;
BA_ "SigType" SG_ 2365562112 EngSts 4;
BA_ "CI_ParId" SG_ 2365562112 StartRelayBcmCmd "ID2186";
BA_ "CI_SigId" SG_ 2365562112 StartRelayBcmCmd 42193;
BA_ "CI_SigName" SG_ 2365562112 StartRelayBcmCmd "Start Relay BCM Command";
BA_ "GenSigTimeoutTime_PCM" SG_ 2365562112 StartRelayBcmCmd 500;
BA_ "SigType" SG_ 2365562112 StartRelayBcmCmd 4;
BA_ "CI_ParId" SG_ 2365562112 BrkPedNcSw "ID2038";
BA_ "CI_SigId" SG_ 2365562112 BrkPedNcSw 39851;
BA_ "CI_SigName" SG_ 2365562112 BrkPedNcSw "Brake Pedal NC Switch";
BA_ "GenSigTimeoutTime_PCM" SG_ 2365562112 BrkPedNcSw 500;
BA_ "SigType" SG_ 2365562112 BrkPedNcSw 4;
BA_ "CI_ParId" SG_ 2365562112 BrkPedNoSw "ID2037";
BA_ "CI_SigId" SG_ 2365562112 BrkPedNoSw 39850;
BA_ "CI_SigName" SG_ 2365562112 BrkPedNoSw "Brake Pedal NO Switch";
BA_ "GenSigTimeoutTime_PCM" SG_ 2365562112 BrkPedNoSw 500;
BA_ "SigType" SG_ 2365562112 BrkPedNoSw 4;
BA_ "CI_ParId" SG_ 2365562112 CltOpenSw_F9D00 "ID0162";
BA_ "CI_SigId" SG_ 2365562112 CltOpenSw_F9D00 35249;
BA_ "CI_SigName" SG_ 2365562112 CltOpenSw_F9D00 "Clutch Open Switch";
BA_ "GenSigTimeoutTime_PCM" SG_ 2365562112 CltOpenSw_F9D00 500;
BA_ "SigType" SG_ 2365562112 CltOpenSw_F9D00 4;
BA_ "CI_ParId" SG_ 2365562112 CltSw_F9D00 "598";
BA_ "CI_SigId" SG_ 2365562112 CltSw_F9D00 35248;
BA_ "CI_SigName" SG_ 2365562112 CltSw_F9D00 "Clutch Switch";
BA_ "GenSigTimeoutTime_PCM" SG_ 2365562112 CltSw_F9D00 500;
BA_ "SPN" SG_ 2365562112 CltSw_F9D00 598;
BA_ "SigType" SG_ 2365562112 CltSw_F9D00 4;
BA_ "CI_ParId" SG_ 2566865482 SwVerField4 "I807";
BA_ "CI_SigId" SG_ 2566865482 SwVerField4 4920;
BA_ "CI_SigName" SG_ 2566865482 SwVerField4 "Software Version - Field 4";
BA_ "GenSigSendType" SG_ 2566865482 SwVerField4 3;
BA_ "GenSigTimeoutTime_SGW" SG_ 2566865482 SwVerField4 50000;
BA_ "CI_ParId" SG_ 2566865482 SwVerField3 "I806";
BA_ "CI_SigId" SG_ 2566865482 SwVerField3 4919;
BA_ "CI_SigName" SG_ 2566865482 SwVerField3 "Software Version - Field 3";
BA_ "GenSigSendType" SG_ 2566865482 SwVerField3 3;
BA_ "GenSigTimeoutTime_SGW" SG_ 2566865482 SwVerField3 50000;
BA_ "CI_ParId" SG_ 2566865482 SwVerField2 "I805";
BA_ "CI_SigId" SG_ 2566865482 SwVerField2 4918;
BA_ "CI_SigName" SG_ 2566865482 SwVerField2 "Software Version - Field 2";
BA_ "GenSigSendType" SG_ 2566865482 SwVerField2 3;
BA_ "GenSigTimeoutTime_SGW" SG_ 2566865482 SwVerField2 50000;
BA_ "CI_ParId" SG_ 2566865482 SwVerField1 "I804";
BA_ "CI_SigId" SG_ 2566865482 SwVerField1 4917;
BA_ "CI_SigName" SG_ 2566865482 SwVerField1 "Software Version - Field 1";
BA_ "GenSigSendType" SG_ 2566865482 SwVerField1 3;
BA_ "GenSigTimeoutTime_SGW" SG_ 2566865482 SwVerField1 50000;
BA_ "CI_ParId" SG_ 2566865482 SwUpdateSts "I748";
BA_ "CI_SigId" SG_ 2566865482 SwUpdateSts 4916;
BA_ "CI_SigName" SG_ 2566865482 SwUpdateSts "Software Update Status";
BA_ "GenSigSendType" SG_ 2566865482 SwUpdateSts 3;
BA_ "GenSigTimeoutTime_SGW" SG_ 2566865482 SwUpdateSts 50000;
BA_ "CI_ParId" SG_ 2583638311 TotHvacEnergyConsHeatBat "ID2140";
BA_ "CI_SigId" SG_ 2583638311 TotHvacEnergyConsHeatBat 41813;
BA_ "CI_SigName" SG_ 2583638311 TotHvacEnergyConsHeatBat "Total HVAC Energy Consumption Heating Battery";
BA_ "GenSigTimeoutTime_PCM" SG_ 2583638311 TotHvacEnergyConsHeatBat 50000;
BA_ "SigType" SG_ 2583638311 TotHvacEnergyConsHeatBat 1;
BA_ "CI_ParId" SG_ 2583638311 TotHvacEnergyConsHeatCab "ID2139";
BA_ "CI_SigId" SG_ 2583638311 TotHvacEnergyConsHeatCab 41812;
BA_ "CI_SigName" SG_ 2583638311 TotHvacEnergyConsHeatCab "Total HVAC Energy Consumption Heating Cabin";
BA_ "GenSigTimeoutTime_PCM" SG_ 2583638311 TotHvacEnergyConsHeatCab 50000;
BA_ "SigType" SG_ 2583638311 TotHvacEnergyConsHeatCab 1;
BA_ "CI_ParId" SG_ 2583638567 TotEnergyRecharged "ID2142";
BA_ "CI_SigId" SG_ 2583638567 TotEnergyRecharged 41816;
BA_ "CI_SigName" SG_ 2583638567 TotEnergyRecharged "Total Energy Recharged";
BA_ "GenSigTimeoutTime_PCM" SG_ 2583638567 TotEnergyRecharged 50000;
BA_ "SigType" SG_ 2583638567 TotEnergyRecharged 1;
BA_ "CI_ParId" SG_ 2583638567 TotHvacEnergyConsCool "ID2141";
BA_ "CI_SigId" SG_ 2583638567 TotHvacEnergyConsCool 41815;
BA_ "CI_SigName" SG_ 2583638567 TotHvacEnergyConsCool "Total HVAC Energy Consumption Cooling";
BA_ "GenSigTimeoutTime_PCM" SG_ 2583638567 TotHvacEnergyConsCool 50000;
BA_ "SigType" SG_ 2583638567 TotHvacEnergyConsCool 1;
BA_ "CI_ParId" SG_ 2365572627 AsilDConfor "ID2354";
BA_ "CI_SigId" SG_ 2365572627 AsilDConfor 43766;
BA_ "CI_SigName" SG_ 2365572627 AsilDConfor "ASIL D Conformance";
BA_ "GenSigTimeoutTime_PCM" SG_ 2365572627 AsilDConfor 500;
BA_ "SigType" SG_ 2365572627 AsilDConfor 4;
BA_ "CI_ParId" SG_ 2365572627 ActSteerColTrq "ID2368";
BA_ "CI_SigId" SG_ 2365572627 ActSteerColTrq 43063;
BA_ "CI_SigName" SG_ 2365572627 ActSteerColTrq "Actual Steering Column Torque";
BA_ "GenSigTimeoutTime_PCM" SG_ 2365572627 ActSteerColTrq 500;
BA_ "CI_ParId" SG_ 2365572627 PacTrq "ID2367";
BA_ "CI_SigId" SG_ 2365572627 PacTrq 43062;
BA_ "CI_SigName" SG_ 2365572627 PacTrq "PAC Torque";
BA_ "GenSigTimeoutTime_PCM" SG_ 2365572627 PacTrq 500;
BA_ "CI_ParId" SG_ 2365572627 ActSteerMotTrq "ID2369";
BA_ "CI_SigId" SG_ 2365572627 ActSteerMotTrq 42162;
BA_ "CI_SigName" SG_ 2365572627 ActSteerMotTrq "Actual Steering Motor Torque";
BA_ "GenSigTimeoutTime_PCM" SG_ 2365572627 ActSteerMotTrq 500;
BA_ "CI_ParId" SG_ 2365572627 LatCtrlFunctsReqSts "ID2384";
BA_ "CI_SigId" SG_ 2365572627 LatCtrlFunctsReqSts 42811;
BA_ "CI_SigName" SG_ 2365572627 LatCtrlFunctsReqSts "Lateral Control Functions Request Status";
BA_ "GenSigTimeoutTime_PCM" SG_ 2365572627 LatCtrlFunctsReqSts 500;
BA_ "SigType" SG_ 2365572627 LatCtrlFunctsReqSts 4;
BA_ "CI_ParId" SG_ 2365572627 Angle "ID2355";
BA_ "CI_SigId" SG_ 2365572627 Angle 42161;
BA_ "CI_SigName" SG_ 2365572627 Angle "Angle";
BA_ "GenSigTimeoutTime_PCM" SG_ 2365572627 Angle 500;
BA_ "CI_ParId" SG_ 2365572627 LatCtrlFunctSts "ID2357";
BA_ "CI_SigId" SG_ 2365572627 LatCtrlFunctSts 43061;
BA_ "CI_SigName" SG_ 2365572627 LatCtrlFunctSts "Lateral Control Function Status";
BA_ "GenSigTimeoutTime_PCM" SG_ 2365572627 LatCtrlFunctSts 500;
BA_ "SigType" SG_ 2365572627 LatCtrlFunctSts 4;
BA_ "CI_ParId" SG_ 2365572627 AngleCal "ID2356";
BA_ "CI_SigId" SG_ 2365572627 AngleCal 42160;
BA_ "CI_SigName" SG_ 2365572627 AngleCal "Angle Calibration";
BA_ "GenSigTimeoutTime_PCM" SG_ 2365572627 AngleCal 500;
BA_ "SigType" SG_ 2365572627 AngleCal 4;
BA_ "CI_ParId" SG_ 2566852883 SteerCtrlEcuTemp "ID2171";
BA_ "CI_SigId" SG_ 2566852883 SteerCtrlEcuTemp 42178;
BA_ "CI_SigName" SG_ 2566852883 SteerCtrlEcuTemp "Steering Controller ECU Temperature";
BA_ "GenSigTimeoutTime_PCM" SG_ 2566852883 SteerCtrlEcuTemp 500;
BA_ "SigType" SG_ 2566852883 SteerCtrlEcuTemp 1;
BA_ "CI_ParId" SG_ 2566852883 EpsSteerFrzFail "ID2485";
BA_ "CI_SigId" SG_ 2566852883 EpsSteerFrzFail 43958;
BA_ "CI_SigName" SG_ 2566852883 EpsSteerFrzFail "EPS Steering Freeze Failure";
BA_ "GenSigTimeoutTime_PCM" SG_ 2566852883 EpsSteerFrzFail 500;
BA_ "CI_ParId" SG_ 2566852883 AngleSpeed "ID2169";
BA_ "CI_SigId" SG_ 2566852883 AngleSpeed 43733;
BA_ "CI_SigName" SG_ 2566852883 AngleSpeed "Angle Speed";
BA_ "GenSigTimeoutTime_PCM" SG_ 2566852883 AngleSpeed 500;
BA_ "CI_ParId" SG_ 2566852883 DrivHandsOffConfLev "I420";
BA_ "CI_SigId" SG_ 2566852883 DrivHandsOffConfLev 6462;
BA_ "CI_SigName" SG_ 2566852883 DrivHandsOffConfLev "Driver's Hands Off Confidence Level";
BA_ "GenSigTimeoutTime_PCM" SG_ 2566852883 DrivHandsOffConfLev 500;
BA_ "CI_ParId" SG_ 2566852883 DrivHandsOffDet "I419";
BA_ "CI_SigId" SG_ 2566852883 DrivHandsOffDet 6461;
BA_ "CI_SigName" SG_ 2566852883 DrivHandsOffDet "Driver's Hands Off Detected";
BA_ "GenSigTimeoutTime_PCM" SG_ 2566852883 DrivHandsOffDet 500;
BA_ "SigType" SG_ 2566852883 DrivHandsOffDet 4;
BA_ "CI_ParId" SG_ 2566852883 CtrlDevForSteerCtrl "ID2329";
BA_ "CI_SigId" SG_ 2566852883 CtrlDevForSteerCtrl 43732;
BA_ "CI_SigName" SG_ 2566852883 CtrlDevForSteerCtrl "Controlling Device for Steering Control";
BA_ "GenSigTimeoutTime_PCM" SG_ 2566852883 CtrlDevForSteerCtrl 500;
BA_ "SigType" SG_ 2566852883 CtrlDevForSteerCtrl 4;
BA_ "CI_ParId" SG_ 2566852883 ExtVibrCtrlRdySts "I418";
BA_ "CI_SigId" SG_ 2566852883 ExtVibrCtrlRdySts 6460;
BA_ "CI_SigName" SG_ 2566852883 ExtVibrCtrlRdySts "External Vibration Control Readiness Status";
BA_ "GenSigTimeoutTime_PCM" SG_ 2566852883 ExtVibrCtrlRdySts 500;
BA_ "SigType" SG_ 2566852883 ExtVibrCtrlRdySts 4;
BA_ "CI_ParId" SG_ 2566852883 ExtAngleCtrlRdySts "I417";
BA_ "CI_SigId" SG_ 2566852883 ExtAngleCtrlRdySts 6459;
BA_ "CI_SigName" SG_ 2566852883 ExtAngleCtrlRdySts "External Angle Control Readiness Status";
BA_ "GenSigTimeoutTime_PCM" SG_ 2566852883 ExtAngleCtrlRdySts 500;
BA_ "SigType" SG_ 2566852883 ExtAngleCtrlRdySts 4;
BA_ "CI_ParId" SG_ 2566852883 ExtTrqCtrlRdySts "I416";
BA_ "CI_SigId" SG_ 2566852883 ExtTrqCtrlRdySts 6458;
BA_ "CI_SigName" SG_ 2566852883 ExtTrqCtrlRdySts "External Torque Control Readiness Status";
BA_ "GenSigTimeoutTime_PCM" SG_ 2566852883 ExtTrqCtrlRdySts 500;
BA_ "SigType" SG_ 2566852883 ExtTrqCtrlRdySts 4;
BA_ "CI_ParId" SG_ 2566852883 EpsOpSts "I415";
BA_ "CI_SigId" SG_ 2566852883 EpsOpSts 6457;
BA_ "CI_SigName" SG_ 2566852883 EpsOpSts "Electronic Power Steering Operational Status";
BA_ "GenSigTimeoutTime_PCM" SG_ 2566852883 EpsOpSts 500;
BA_ "CI_ParId" SG_ 2566852883 EpsOpMode "I414";
BA_ "CI_SigId" SG_ 2566852883 EpsOpMode 6456;
BA_ "CI_SigName" SG_ 2566852883 EpsOpMode "Electronic Power Steering Operating Mode";
BA_ "GenSigTimeoutTime_PCM" SG_ 2566852883 EpsOpMode 500;
BA_ "CI_ParId" SG_ 2583640359 Crc8_FF3927 "ID2118";
BA_ "CI_SigId" SG_ 2583640359 Crc8_FF3927 41109;
BA_ "CI_SigName" SG_ 2583640359 Crc8_FF3927 "CRC-8 ";
BA_ "GenSigTimeoutTime_PCM" SG_ 2583640359 Crc8_FF3927 1250;
BA_ "CI_ParId" SG_ 2583640359 MsgCnt_FF3927 "4206";
BA_ "CI_SigId" SG_ 2583640359 MsgCnt_FF3927 41108;
BA_ "CI_SigName" SG_ 2583640359 MsgCnt_FF3927 "Message Counter";
BA_ "GenSigTimeoutTime_PCM" SG_ 2583640359 MsgCnt_FF3927 1250;
BA_ "SPN" SG_ 2583640359 MsgCnt_FF3927 4206;
BA_ "CI_ParId" SG_ 2583640359 PeakDevCur "ID2086";
BA_ "CI_SigId" SG_ 2583640359 PeakDevCur 41105;
BA_ "CI_SigName" SG_ 2583640359 PeakDevCur "Peak deviation current";
BA_ "GenSigTimeoutTime_PCM" SG_ 2583640359 PeakDevCur 1250;
BA_ "SigType" SG_ 2583640359 PeakDevCur 4;
BA_ "CI_ParId" SG_ 2583640359 LongDevCur "ID2085";
BA_ "CI_SigId" SG_ 2583640359 LongDevCur 41104;
BA_ "CI_SigName" SG_ 2583640359 LongDevCur "Long deviation Current";
BA_ "GenSigTimeoutTime_PCM" SG_ 2583640359 LongDevCur 1250;
BA_ "SigType" SG_ 2583640359 LongDevCur 4;
BA_ "CI_ParId" SG_ 2583640359 EptoWaitingMode "ID2115";
BA_ "CI_SigId" SG_ 2583640359 EptoWaitingMode 41103;
BA_ "CI_SigName" SG_ 2583640359 EptoWaitingMode "ePTO Waiting Mode";
BA_ "GenSigTimeoutTime_PCM" SG_ 2583640359 EptoWaitingMode 1250;
BA_ "CI_ParId" SG_ 2583640359 EngCons "ID2079";
BA_ "CI_SigId" SG_ 2583640359 EngCons 41102;
BA_ "CI_SigName" SG_ 2583640359 EngCons "Engagement Consent";
BA_ "GenSigTimeoutTime_PCM" SG_ 2583640359 EngCons 1250;
BA_ "SigType" SG_ 2583640359 EngCons 4;
BA_ "CI_ParId" SG_ 2583640359 OperativeEptoSts "ID2078";
BA_ "CI_SigId" SG_ 2583640359 OperativeEptoSts 41101;
BA_ "CI_SigName" SG_ 2583640359 OperativeEptoSts "Operative ePTO State";
BA_ "GenSigTimeoutTime_PCM" SG_ 2583640359 OperativeEptoSts 1250;
BA_ "CI_ParId" SG_ 2583640359 MaxCurLim "ID2084";
BA_ "CI_SigId" SG_ 2583640359 MaxCurLim 41100;
BA_ "CI_SigName" SG_ 2583640359 MaxCurLim "Maximum Current Limitation";
BA_ "GenSigTimeoutTime_PCM" SG_ 2583640359 MaxCurLim 1250;
BA_ "SigType" SG_ 2583640359 MaxCurLim 1;
BA_ "CI_ParId" SG_ 2583640359 MinSocLim "ID2083";
BA_ "CI_SigId" SG_ 2583640359 MinSocLim 41099;
BA_ "CI_SigName" SG_ 2583640359 MinSocLim "Minimum SOC limitation";
BA_ "GenSigTimeoutTime_PCM" SG_ 2583640359 MinSocLim 1250;
BA_ "SigType" SG_ 2583640359 MinSocLim 1;
BA_ "CI_ParId" SG_ 2583640359 LowSocLim "ID2082";
BA_ "CI_SigId" SG_ 2583640359 LowSocLim 41098;
BA_ "CI_SigName" SG_ 2583640359 LowSocLim "Lower SOC limitation";
BA_ "GenSigTimeoutTime_PCM" SG_ 2583640359 LowSocLim 1250;
BA_ "SigType" SG_ 2583640359 LowSocLim 1;
BA_ "CI_ParId" SG_ 2583640359 MaxAllwPwr "ID2081";
BA_ "CI_SigId" SG_ 2583640359 MaxAllwPwr 41097;
BA_ "CI_SigName" SG_ 2583640359 MaxAllwPwr "Maximum Allowed Power";
BA_ "GenSigTimeoutTime_PCM" SG_ 2583640359 MaxAllwPwr 1250;
BA_ "SigType" SG_ 2583640359 MaxAllwPwr 1;
BA_ "CI_ParId" SG_ 2583640359 ActPwr "ID2080";
BA_ "CI_SigId" SG_ 2583640359 ActPwr 41096;
BA_ "CI_SigName" SG_ 2583640359 ActPwr "Actual Power";
BA_ "GenSigTimeoutTime_PCM" SG_ 2583640359 ActPwr 1250;
BA_ "SigType" SG_ 2583640359 ActPwr 1;
BA_ "CI_ParId" SG_ 2583639079 OperativeEptoSts_FF3427 "ID2078";
BA_ "CI_SigId" SG_ 2583639079 OperativeEptoSts_FF3427 45663;
BA_ "CI_SigName" SG_ 2583639079 OperativeEptoSts_FF3427 "Operative ePTO State";
BA_ "GenSigTimeoutTime_PCM" SG_ 2583639079 OperativeEptoSts_FF3427 1250;
BA_ "CI_ParId" SG_ 2583639079 SecEptoEnergyCons "ID2607";
BA_ "CI_SigId" SG_ 2583639079 SecEptoEnergyCons 45662;
BA_ "CI_SigName" SG_ 2583639079 SecEptoEnergyCons "Secondary ePTO Energy Consumption";
BA_ "GenSigTimeoutTime_PCM" SG_ 2583639079 SecEptoEnergyCons 1250;
BA_ "SigType" SG_ 2583639079 SecEptoEnergyCons 1;
BA_ "CI_ParId" SG_ 2583639079 ActPwr_FF3427 "ID2080";
BA_ "CI_SigId" SG_ 2583639079 ActPwr_FF3427 45661;
BA_ "CI_SigName" SG_ 2583639079 ActPwr_FF3427 "Actual Power";
BA_ "GenSigTimeoutTime_PCM" SG_ 2583639079 ActPwr_FF3427 1250;
BA_ "SigType" SG_ 2583639079 ActPwr_FF3427 1;
BA_ "CI_ParId" SG_ 2566893315 EtcVehMovTypeOfErr "ID2551";
BA_ "CI_SigId" SG_ 2566893315 EtcVehMovTypeOfErr 44898;
BA_ "CI_SigName" SG_ 2566893315 EtcVehMovTypeOfErr "ETC Vehicle Movement Type Of Error";
BA_ "GenSigTimeoutTime_PCM" SG_ 2566893315 EtcVehMovTypeOfErr 500;
BA_ "CI_ParId" SG_ 2566893315 EtcVehMovSts "ID2550";
BA_ "CI_SigId" SG_ 2566893315 EtcVehMovSts 44897;
BA_ "CI_SigName" SG_ 2566893315 EtcVehMovSts "ETC Vehicle Movement Status";
BA_ "GenSigTimeoutTime_PCM" SG_ 2566893315 EtcVehMovSts 500;
BA_ "SigType" SG_ 2566893315 EtcVehMovSts 4;
BA_ "CI_ParId" SG_ 2566893315 EcoLckGear "ID2530";
BA_ "CI_SigId" SG_ 2566893315 EcoLckGear 44769;
BA_ "CI_SigName" SG_ 2566893315 EcoLckGear "Eco Lock Gear";
BA_ "GenSigTimeoutTime_PCM" SG_ 2566893315 EcoLckGear 500;
BA_ "SigType" SG_ 2566893315 EcoLckGear 4;
BA_ "CI_ParId" SG_ 2566893315 TransmCurGearAsilBConfor "ID2274";
BA_ "CI_SigId" SG_ 2566893315 TransmCurGearAsilBConfor 42628;
BA_ "CI_SigName" SG_ 2566893315 TransmCurGearAsilBConfor "Transmission Current Gear ASIL B Conformance";
BA_ "GenSigTimeoutTime_PCM" SG_ 2566893315 TransmCurGearAsilBConfor 500;
BA_ "SigType" SG_ 2566893315 TransmCurGearAsilBConfor 4;
BA_ "CI_ParId" SG_ 2566893315 TransmSelGear_FFAF03 "ID2189";
BA_ "CI_SigId" SG_ 2566893315 TransmSelGear_FFAF03 42200;
BA_ "CI_SigName" SG_ 2566893315 TransmSelGear_FFAF03 "Transmission Selected Gear";
BA_ "GenSigTimeoutTime_PCM" SG_ 2566893315 TransmSelGear_FFAF03 500;
BA_ "CI_ParId" SG_ 2566893315 TransmCurGear_FFAF03 "523";
BA_ "CI_SigId" SG_ 2566893315 TransmCurGear_FFAF03 33413;
BA_ "CI_SigName" SG_ 2566893315 TransmCurGear_FFAF03 "Transmission Current Gear";
BA_ "GenSigTimeoutTime_PCM" SG_ 2566893315 TransmCurGear_FFAF03 500;
BA_ "SPN" SG_ 2566893315 TransmCurGear_FFAF03 523;
BA_ "SigType" SG_ 2566893315 TransmCurGear_FFAF03 1;
BA_ "CI_ParId" SG_ 2566893315 PossTrqTransm "ID2190";
BA_ "CI_SigId" SG_ 2566893315 PossTrqTransm 42208;
BA_ "CI_SigName" SG_ 2566893315 PossTrqTransm "Possible Torque Transmission";
BA_ "GenSigTimeoutTime_PCM" SG_ 2566893315 PossTrqTransm 500;
BA_ "SigType" SG_ 2566893315 PossTrqTransm 4;
BA_ "CI_ParId" SG_ 2566893315 SplitShaftPtoDrvlEngd "ID0974";
BA_ "CI_SigId" SG_ 2566893315 SplitShaftPtoDrvlEngd 33412;
BA_ "CI_SigName" SG_ 2566893315 SplitShaftPtoDrvlEngd "Split Shaft PTO Driveline Engaged";
BA_ "GenSigTimeoutTime_PCM" SG_ 2566893315 SplitShaftPtoDrvlEngd 500;
BA_ "SigType" SG_ 2566893315 SplitShaftPtoDrvlEngd 4;
BA_ "CI_ParId" SG_ 2566893315 TransmDrvlEngd_FFAF03 "560";
BA_ "CI_SigId" SG_ 2566893315 TransmDrvlEngd_FFAF03 33411;
BA_ "CI_SigName" SG_ 2566893315 TransmDrvlEngd_FFAF03 "Transmission Driveline Engaged";
BA_ "GenSigTimeoutTime_PCM" SG_ 2566893315 TransmDrvlEngd_FFAF03 500;
BA_ "SPN" SG_ 2566893315 TransmDrvlEngd_FFAF03 560;
BA_ "SigType" SG_ 2566893315 TransmDrvlEngd_FFAF03 4;
BA_ "CI_ParId" SG_ 2566893315 TransmEngCrkEna_FFAF03 "2900";
BA_ "CI_SigId" SG_ 2566893315 TransmEngCrkEna_FFAF03 33410;
BA_ "CI_SigName" SG_ 2566893315 TransmEngCrkEna_FFAF03 "Transmission Engine Crank Enable";
BA_ "GenSigTimeoutTime_PCM" SG_ 2566893315 TransmEngCrkEna_FFAF03 500;
BA_ "SPN" SG_ 2566893315 TransmEngCrkEna_FFAF03 2900;
BA_ "SigType" SG_ 2566893315 TransmEngCrkEna_FFAF03 4;
BA_ "CI_ParId" SG_ 2566894119 TimeLeftToFullChg "I692";
BA_ "CI_SigId" SG_ 2566894119 TimeLeftToFullChg 4070;
BA_ "CI_SigName" SG_ 2566894119 TimeLeftToFullChg "Time Left to Full Charge";
BA_ "GenSigSendType" SG_ 2566894119 TimeLeftToFullChg 3;
BA_ "GenSigTimeoutTime_PCM" SG_ 2566894119 TimeLeftToFullChg 5000;
BA_ "SigType" SG_ 2566894119 TimeLeftToFullChg 1;
BA_ "CI_ParId" SG_ 2566894119 FullChgRngMin "I691";
BA_ "CI_SigId" SG_ 2566894119 FullChgRngMin 4069;
BA_ "CI_SigName" SG_ 2566894119 FullChgRngMin "Full Charge Range (min)";
BA_ "GenSigSendType" SG_ 2566894119 FullChgRngMin 3;
BA_ "GenSigTimeoutTime_PCM" SG_ 2566894119 FullChgRngMin 5000;
BA_ "SigType" SG_ 2566894119 FullChgRngMin 1;
BA_ "CI_ParId" SG_ 2566894119 CurRngMin "I690";
BA_ "CI_SigId" SG_ 2566894119 CurRngMin 4068;
BA_ "CI_SigName" SG_ 2566894119 CurRngMin "Current Range (min)";
BA_ "GenSigSendType" SG_ 2566894119 CurRngMin 3;
BA_ "GenSigTimeoutTime_PCM" SG_ 2566894119 CurRngMin 5000;
BA_ "SigType" SG_ 2566894119 CurRngMin 1;
BA_ "CI_ParId" SG_ 2566894119 FullChgRngKm "I689";
BA_ "CI_SigId" SG_ 2566894119 FullChgRngKm 4067;
BA_ "CI_SigName" SG_ 2566894119 FullChgRngKm "Full Charge Range (km)";
BA_ "GenSigSendType" SG_ 2566894119 FullChgRngKm 3;
BA_ "GenSigTimeoutTime_PCM" SG_ 2566894119 FullChgRngKm 5000;
BA_ "CI_ParId" SG_ 2566894119 CurRngKm "I688";
BA_ "CI_SigId" SG_ 2566894119 CurRngKm 4066;
BA_ "CI_SigName" SG_ 2566894119 CurRngKm "Current Range (km)";
BA_ "GenSigSendType" SG_ 2566894119 CurRngKm 3;
BA_ "GenSigTimeoutTime_PCM" SG_ 2566894119 CurRngKm 5000;
BA_ "CI_ParId" SG_ 2566886730 FmsIAccMan_AutoCfg "ID2463";
BA_ "CI_SigId" SG_ 2566886730 FmsIAccMan_AutoCfg 44546;
BA_ "CI_SigName" SG_ 2566886730 FmsIAccMan_AutoCfg "FMS i-ACC Manual/Automatic Configuration";
BA_ "CI_ParId" SG_ 2566886730 FmsIsaAcousticWarnCfg "ID2462";
BA_ "CI_SigId" SG_ 2566886730 FmsIsaAcousticWarnCfg 44545;
BA_ "CI_SigName" SG_ 2566886730 FmsIsaAcousticWarnCfg "FMS ISA Acoustic Warning Configuration";
BA_ "SigType" SG_ 2566886730 FmsIsaAcousticWarnCfg 4;
BA_ "CI_ParId" SG_ 2566886730 FmsISACfg "ID2461";
BA_ "CI_SigId" SG_ 2566886730 FmsISACfg 44544;
BA_ "CI_SigName" SG_ 2566886730 FmsISACfg "FMS Intelligent Speed Assistant Configuration";
BA_ "SigType" SG_ 2566886730 FmsISACfg 4;
BA_ "CI_ParId" SG_ 2566886730 FmsLkaCfg "ID2460";
BA_ "CI_SigId" SG_ 2566886730 FmsLkaCfg 44543;
BA_ "CI_SigName" SG_ 2566886730 FmsLkaCfg "FMS Lane Keep Assist Configuration";
BA_ "SigType" SG_ 2566886730 FmsLkaCfg 4;
BA_ "CI_ParId" SG_ 2566886730 FmsAhbcCfg "ID2459";
BA_ "CI_SigId" SG_ 2566886730 FmsAhbcCfg 44542;
BA_ "CI_SigName" SG_ 2566886730 FmsAhbcCfg "FMS Automatic High Beam Control Configuration";
BA_ "SigType" SG_ 2566886730 FmsAhbcCfg 4;
BA_ "CI_ParId" SG_ 2566886730 FmsIsaSpeedLimCfg "ID2516";
BA_ "CI_SigId" SG_ 2566886730 FmsIsaSpeedLimCfg 44753;
BA_ "CI_SigName" SG_ 2566886730 FmsIsaSpeedLimCfg "FMS ISA Speed Limiter Configuration";
BA_ "CI_ParId" SG_ 2566886730 FmsAebsSensCfg "ID2458";
BA_ "CI_SigId" SG_ 2566886730 FmsAebsSensCfg 44541;
BA_ "CI_SigName" SG_ 2566886730 FmsAebsSensCfg "FMS AEBS Sensitivity Configuration";
BA_ "CI_ParId" SG_ 2566886730 FmsDistWarnCfg "ID2457";
BA_ "CI_SigId" SG_ 2566886730 FmsDistWarnCfg 44540;
BA_ "CI_SigName" SG_ 2566886730 FmsDistWarnCfg "FMS Distance Warning Configuration";
BA_ "SigType" SG_ 2566886730 FmsDistWarnCfg 4;
BA_ "CI_ParId" SG_ 2566886730 FmsAEBSCfg "ID2456";
BA_ "CI_SigId" SG_ 2566886730 FmsAEBSCfg 44539;
BA_ "CI_SigName" SG_ 2566886730 FmsAEBSCfg "FMS AEBS Configuration";
BA_ "SigType" SG_ 2566886730 FmsAEBSCfg 4;
BA_ "CI_ParId" SG_ 2566886730 FmsDdawSensCfg "ID2455";
BA_ "CI_SigId" SG_ 2566886730 FmsDdawSensCfg 44538;
BA_ "CI_SigName" SG_ 2566886730 FmsDdawSensCfg "FMS DDAW Sensitivity Configuration";
BA_ "SigType" SG_ 2566886730 FmsDdawSensCfg 4;
BA_ "CI_ParId" SG_ 2566886730 FmsDdawWarnCfg "ID2454";
BA_ "CI_SigId" SG_ 2566886730 FmsDdawWarnCfg 44537;
BA_ "CI_SigName" SG_ 2566886730 FmsDdawWarnCfg "FMS DDAW Warning Configuration";
BA_ "SigType" SG_ 2566886730 FmsDdawWarnCfg 4;
BA_ "CI_ParId" SG_ 2566886730 FmsDoorOpenWarnFunctCfg "ID2453";
BA_ "CI_SigId" SG_ 2566886730 FmsDoorOpenWarnFunctCfg 44536;
BA_ "CI_SigName" SG_ 2566886730 FmsDoorOpenWarnFunctCfg "FMS Door Open Warning Function Configuration";
BA_ "SigType" SG_ 2566886730 FmsDoorOpenWarnFunctCfg 4;
BA_ "CI_ParId" SG_ 2566886730 FmsBsisAcousticWarnCfg "ID2452";
BA_ "CI_SigId" SG_ 2566886730 FmsBsisAcousticWarnCfg 44535;
BA_ "CI_SigName" SG_ 2566886730 FmsBsisAcousticWarnCfg "FMS BSIS Acoustic Warning Configuration";
BA_ "SigType" SG_ 2566886730 FmsBsisAcousticWarnCfg 4;
BA_ "CI_ParId" SG_ 2566886730 FmsMoisFunctCfg "ID2451";
BA_ "CI_SigId" SG_ 2566886730 FmsMoisFunctCfg 44534;
BA_ "CI_SigName" SG_ 2566886730 FmsMoisFunctCfg "FMS MOIS Function Configuration";
BA_ "SigType" SG_ 2566886730 FmsMoisFunctCfg 4;
BA_ "CI_ParId" SG_ 2566886730 FmsRCTFunctCfg "ID2450";
BA_ "CI_SigId" SG_ 2566886730 FmsRCTFunctCfg 44533;
BA_ "CI_SigName" SG_ 2566886730 FmsRCTFunctCfg "FMS Rear Cross Traffic Alert Function Configuration";
BA_ "SigType" SG_ 2566886730 FmsRCTFunctCfg 4;
BA_ "CI_ParId" SG_ 2566886730 FmsRCTAcousticWarnCfg "ID2449";
BA_ "CI_SigId" SG_ 2566886730 FmsRCTAcousticWarnCfg 44532;
BA_ "CI_SigName" SG_ 2566886730 FmsRCTAcousticWarnCfg "FMS Rear Cross Traffic Alert Acoustic Warning Configuration";
BA_ "SigType" SG_ 2566886730 FmsRCTAcousticWarnCfg 4;
BA_ "CI_ParId" SG_ 2566886730 FmsBlindSpotFunctCfg "ID2448";
BA_ "CI_SigId" SG_ 2566886730 FmsBlindSpotFunctCfg 44531;
BA_ "CI_SigName" SG_ 2566886730 FmsBlindSpotFunctCfg "FMS Blind Spot Function Configuration";
BA_ "SigType" SG_ 2566886730 FmsBlindSpotFunctCfg 4;
BA_ "CI_ParId" SG_ 2566886730 FmsBlindSpotAcousticWarnCfg "ID2447";
BA_ "CI_SigId" SG_ 2566886730 FmsBlindSpotAcousticWarnCfg 44530;
BA_ "CI_SigName" SG_ 2566886730 FmsBlindSpotAcousticWarnCfg "FMS Blind Spot Acoustic Warning Configuration";
BA_ "SigType" SG_ 2566886730 FmsBlindSpotAcousticWarnCfg 4;
BA_ "CI_ParId" SG_ 2566886935 IsaSpeedLimCfgFmsFdbk "ID2517";
BA_ "CI_SigId" SG_ 2566886935 IsaSpeedLimCfgFmsFdbk 44754;
BA_ "CI_SigName" SG_ 2566886935 IsaSpeedLimCfgFmsFdbk "ISA Speed Limiter Configuration FMS Feedback";
BA_ "GenSigSendType" SG_ 2566886935 IsaSpeedLimCfgFmsFdbk 3;
BA_ "GenSigTimeoutTime_PCM" SG_ 2566886935 IsaSpeedLimCfgFmsFdbk 5000;
BA_ "SigType" SG_ 2566886935 IsaSpeedLimCfgFmsFdbk 4;
BA_ "CI_ParId" SG_ 2566886935 IAccCfgFmsFdbk "ID2481";
BA_ "CI_SigId" SG_ 2566886935 IAccCfgFmsFdbk 44567;
BA_ "CI_SigName" SG_ 2566886935 IAccCfgFmsFdbk "i-ACC Configuration FMS Feedback";
BA_ "GenSigSendType" SG_ 2566886935 IAccCfgFmsFdbk 3;
BA_ "GenSigTimeoutTime_PCM" SG_ 2566886935 IAccCfgFmsFdbk 5000;
BA_ "SigType" SG_ 2566886935 IAccCfgFmsFdbk 4;
BA_ "CI_ParId" SG_ 2566886935 IsaAcousticWarnCfgFmsFdbk "ID2480";
BA_ "CI_SigId" SG_ 2566886935 IsaAcousticWarnCfgFmsFdbk 44566;
BA_ "CI_SigName" SG_ 2566886935 IsaAcousticWarnCfgFmsFdbk "ISA Acoustic Warning Configuration FMS Feedback";
BA_ "GenSigSendType" SG_ 2566886935 IsaAcousticWarnCfgFmsFdbk 3;
BA_ "GenSigTimeoutTime_PCM" SG_ 2566886935 IsaAcousticWarnCfgFmsFdbk 5000;
BA_ "SigType" SG_ 2566886935 IsaAcousticWarnCfgFmsFdbk 4;
BA_ "CI_ParId" SG_ 2566886935 ISACfgFmsFdbk "ID2479";
BA_ "CI_SigId" SG_ 2566886935 ISACfgFmsFdbk 44565;
BA_ "CI_SigName" SG_ 2566886935 ISACfgFmsFdbk "Intelligent Speed Assistant Configuration FMS Feedback";
BA_ "GenSigSendType" SG_ 2566886935 ISACfgFmsFdbk 3;
BA_ "GenSigTimeoutTime_PCM" SG_ 2566886935 ISACfgFmsFdbk 5000;
BA_ "SigType" SG_ 2566886935 ISACfgFmsFdbk 4;
BA_ "CI_ParId" SG_ 2566886935 LkaCfgFmsFdbk "ID2478";
BA_ "CI_SigId" SG_ 2566886935 LkaCfgFmsFdbk 44564;
BA_ "CI_SigName" SG_ 2566886935 LkaCfgFmsFdbk "Lane Keep Assist Configuration FMS Feedback";
BA_ "GenSigSendType" SG_ 2566886935 LkaCfgFmsFdbk 3;
BA_ "GenSigTimeoutTime_PCM" SG_ 2566886935 LkaCfgFmsFdbk 5000;
BA_ "SigType" SG_ 2566886935 LkaCfgFmsFdbk 4;
BA_ "CI_ParId" SG_ 2566886935 AhbcCfgFmsFdbk "ID2477";
BA_ "CI_SigId" SG_ 2566886935 AhbcCfgFmsFdbk 44563;
BA_ "CI_SigName" SG_ 2566886935 AhbcCfgFmsFdbk "Automatic High Beam Control Configuration FMS Feedback";
BA_ "GenSigSendType" SG_ 2566886935 AhbcCfgFmsFdbk 3;
BA_ "GenSigTimeoutTime_PCM" SG_ 2566886935 AhbcCfgFmsFdbk 5000;
BA_ "SigType" SG_ 2566886935 AhbcCfgFmsFdbk 4;
BA_ "CI_ParId" SG_ 2566886935 DistWarnCfgFmsFdbk "ID2476";
BA_ "CI_SigId" SG_ 2566886935 DistWarnCfgFmsFdbk 44562;
BA_ "CI_SigName" SG_ 2566886935 DistWarnCfgFmsFdbk "Distance Warning Configuration FMS Feedback";
BA_ "GenSigSendType" SG_ 2566886935 DistWarnCfgFmsFdbk 3;
BA_ "GenSigTimeoutTime_PCM" SG_ 2566886935 DistWarnCfgFmsFdbk 5000;
BA_ "SigType" SG_ 2566886935 DistWarnCfgFmsFdbk 4;
BA_ "CI_ParId" SG_ 2566886935 AebsSensCfgFmsFdbk "ID2475";
BA_ "CI_SigId" SG_ 2566886935 AebsSensCfgFmsFdbk 44561;
BA_ "CI_SigName" SG_ 2566886935 AebsSensCfgFmsFdbk "AEBS Sensitivity Configuration FMS Feedback";
BA_ "GenSigSendType" SG_ 2566886935 AebsSensCfgFmsFdbk 3;
BA_ "GenSigTimeoutTime_PCM" SG_ 2566886935 AebsSensCfgFmsFdbk 5000;
BA_ "SigType" SG_ 2566886935 AebsSensCfgFmsFdbk 4;
BA_ "CI_ParId" SG_ 2566886935 AEBSCfgFmsFdbk "ID2474";
BA_ "CI_SigId" SG_ 2566886935 AEBSCfgFmsFdbk 44560;
BA_ "CI_SigName" SG_ 2566886935 AEBSCfgFmsFdbk "AEBS Configuration FMS Feedback";
BA_ "GenSigSendType" SG_ 2566886935 AEBSCfgFmsFdbk 3;
BA_ "GenSigTimeoutTime_PCM" SG_ 2566886935 AEBSCfgFmsFdbk 5000;
BA_ "SigType" SG_ 2566886935 AEBSCfgFmsFdbk 4;
BA_ "CI_ParId" SG_ 2566886935 DdawSensCfgFmsFdbk "ID2473";
BA_ "CI_SigId" SG_ 2566886935 DdawSensCfgFmsFdbk 44559;
BA_ "CI_SigName" SG_ 2566886935 DdawSensCfgFmsFdbk "DDAW Sensitivity Configuration FMS Feedback";
BA_ "GenSigSendType" SG_ 2566886935 DdawSensCfgFmsFdbk 3;
BA_ "GenSigTimeoutTime_PCM" SG_ 2566886935 DdawSensCfgFmsFdbk 5000;
BA_ "SigType" SG_ 2566886935 DdawSensCfgFmsFdbk 4;
BA_ "CI_ParId" SG_ 2566886935 DdawWarnCfgFmsFdbk "ID2472";
BA_ "CI_SigId" SG_ 2566886935 DdawWarnCfgFmsFdbk 44558;
BA_ "CI_SigName" SG_ 2566886935 DdawWarnCfgFmsFdbk "DDAW Warning Configuration FMS Feedback";
BA_ "GenSigSendType" SG_ 2566886935 DdawWarnCfgFmsFdbk 3;
BA_ "GenSigTimeoutTime_PCM" SG_ 2566886935 DdawWarnCfgFmsFdbk 5000;
BA_ "SigType" SG_ 2566886935 DdawWarnCfgFmsFdbk 4;
BA_ "CI_ParId" SG_ 2566886935 DoorOpenWarnFunctCfgFmsFdbk "ID2471";
BA_ "CI_SigId" SG_ 2566886935 DoorOpenWarnFunctCfgFmsFdbk 44557;
BA_ "CI_SigName" SG_ 2566886935 DoorOpenWarnFunctCfgFmsFdbk "Door Open Warning Function Configuration FMS Feedback";
BA_ "GenSigSendType" SG_ 2566886935 DoorOpenWarnFunctCfgFmsFdbk 3;
BA_ "GenSigTimeoutTime_PCM" SG_ 2566886935 DoorOpenWarnFunctCfgFmsFdbk 5000;
BA_ "SigType" SG_ 2566886935 DoorOpenWarnFunctCfgFmsFdbk 4;
BA_ "CI_ParId" SG_ 2566886935 BsisAcousticWarnCfgFmsFdbk "ID2470";
BA_ "CI_SigId" SG_ 2566886935 BsisAcousticWarnCfgFmsFdbk 44556;
BA_ "CI_SigName" SG_ 2566886935 BsisAcousticWarnCfgFmsFdbk "BSIS Acoustic Warning Configuration FMS Feedback";
BA_ "GenSigSendType" SG_ 2566886935 BsisAcousticWarnCfgFmsFdbk 3;
BA_ "GenSigTimeoutTime_PCM" SG_ 2566886935 BsisAcousticWarnCfgFmsFdbk 5000;
BA_ "SigType" SG_ 2566886935 BsisAcousticWarnCfgFmsFdbk 4;
BA_ "CI_ParId" SG_ 2566886935 MoisFunctCfgFmsFdbk "ID2469";
BA_ "CI_SigId" SG_ 2566886935 MoisFunctCfgFmsFdbk 44555;
BA_ "CI_SigName" SG_ 2566886935 MoisFunctCfgFmsFdbk "MOIS Function Configuration FMS Feedback";
BA_ "GenSigSendType" SG_ 2566886935 MoisFunctCfgFmsFdbk 3;
BA_ "GenSigTimeoutTime_PCM" SG_ 2566886935 MoisFunctCfgFmsFdbk 5000;
BA_ "SigType" SG_ 2566886935 MoisFunctCfgFmsFdbk 4;
BA_ "CI_ParId" SG_ 2566886935 RCTAFunctCfgFmsFdbk "ID2468";
BA_ "CI_SigId" SG_ 2566886935 RCTAFunctCfgFmsFdbk 44554;
BA_ "CI_SigName" SG_ 2566886935 RCTAFunctCfgFmsFdbk "Rear Cross Traffic Alert Function Configuration FMS Feedback";
BA_ "GenSigSendType" SG_ 2566886935 RCTAFunctCfgFmsFdbk 3;
BA_ "GenSigTimeoutTime_PCM" SG_ 2566886935 RCTAFunctCfgFmsFdbk 5000;
BA_ "SigType" SG_ 2566886935 RCTAFunctCfgFmsFdbk 4;
BA_ "CI_ParId" SG_ 2566886935 RCTAcousticWarnCfgFmsFdbk "ID2467";
BA_ "CI_SigId" SG_ 2566886935 RCTAcousticWarnCfgFmsFdbk 44553;
BA_ "CI_SigName" SG_ 2566886935 RCTAcousticWarnCfgFmsFdbk "Rear Cross Traffic Alert Acoustic Warning Configuration FMS Feedback ";
BA_ "GenSigSendType" SG_ 2566886935 RCTAcousticWarnCfgFmsFdbk 3;
BA_ "GenSigTimeoutTime_PCM" SG_ 2566886935 RCTAcousticWarnCfgFmsFdbk 5000;
BA_ "SigType" SG_ 2566886935 RCTAcousticWarnCfgFmsFdbk 4;
BA_ "CI_ParId" SG_ 2566886935 BlindSpotFunctCfgFmsFdbk "ID2466";
BA_ "CI_SigId" SG_ 2566886935 BlindSpotFunctCfgFmsFdbk 44552;
BA_ "CI_SigName" SG_ 2566886935 BlindSpotFunctCfgFmsFdbk "Blind Spot Function Configuration FMS Feedback ";
BA_ "GenSigSendType" SG_ 2566886935 BlindSpotFunctCfgFmsFdbk 3;
BA_ "GenSigTimeoutTime_PCM" SG_ 2566886935 BlindSpotFunctCfgFmsFdbk 5000;
BA_ "SigType" SG_ 2566886935 BlindSpotFunctCfgFmsFdbk 4;
BA_ "CI_ParId" SG_ 2566886935 BlindSpotAcousticWarnCfgFmsFdbk "ID2465";
BA_ "CI_SigId" SG_ 2566886935 BlindSpotAcousticWarnCfgFmsFdbk 44551;
BA_ "CI_SigName" SG_ 2566886935 BlindSpotAcousticWarnCfgFmsFdbk "Blind Spot Acoustic Warning Configuration FMS Feedback ";
BA_ "GenSigSendType" SG_ 2566886935 BlindSpotAcousticWarnCfgFmsFdbk 3;
BA_ "GenSigTimeoutTime_PCM" SG_ 2566886935 BlindSpotAcousticWarnCfgFmsFdbk 5000;
BA_ "SigType" SG_ 2566886935 BlindSpotAcousticWarnCfgFmsFdbk 4;
BA_ "CI_ParId" SG_ 2583655201 WndLifterLeftSts "ID2537";
BA_ "CI_SigId" SG_ 2583655201 WndLifterLeftSts 44797;
BA_ "CI_SigName" SG_ 2583655201 WndLifterLeftSts "Window Lifter Left Status";
BA_ "GenSigSendType" SG_ 2583655201 WndLifterLeftSts 3;
BA_ "GenSigTimeoutTime_PCM" SG_ 2583655201 WndLifterLeftSts 500;
BA_ "CI_ParId" SG_ 2583655201 WndLifterRightSts "ID2536";
BA_ "CI_SigId" SG_ 2583655201 WndLifterRightSts 44796;
BA_ "CI_SigName" SG_ 2583655201 WndLifterRightSts "Window Lifter Right Status";
BA_ "GenSigSendType" SG_ 2583655201 WndLifterRightSts 3;
BA_ "GenSigTimeoutTime_PCM" SG_ 2583655201 WndLifterRightSts 500;
BA_ "CI_ParId" SG_ 2583655201 LowBatDev "ID1533";
BA_ "CI_SigId" SG_ 2583655201 LowBatDev 41953;
BA_ "CI_SigName" SG_ 2583655201 LowBatDev "Low-battery Device";
BA_ "GenSigSendType" SG_ 2583655201 LowBatDev 3;
BA_ "GenSigTimeoutTime_PCM" SG_ 2583655201 LowBatDev 500;
BA_ "SigType" SG_ 2583655201 LowBatDev 4;
BA_ "CI_ParId" SG_ 2583655201 TurnSigSw_FF7321 "2876";
BA_ "CI_SigId" SG_ 2583655201 TurnSigSw_FF7321 42395;
BA_ "CI_SigName" SG_ 2583655201 TurnSigSw_FF7321 "Turn Signal Switch";
BA_ "GenSigSendType" SG_ 2583655201 TurnSigSw_FF7321 3;
BA_ "GenSigTimeoutTime_PCM" SG_ 2583655201 TurnSigSw_FF7321 500;
BA_ "SPN" SG_ 2583655201 TurnSigSw_FF7321 2876;
BA_ "CI_ParId" SG_ 2583655201 HandBrkSts "ID2251";
BA_ "CI_SigId" SG_ 2583655201 HandBrkSts 42394;
BA_ "CI_SigName" SG_ 2583655201 HandBrkSts "Hand Brake Status";
BA_ "GenSigSendType" SG_ 2583655201 HandBrkSts 3;
BA_ "GenSigTimeoutTime_PCM" SG_ 2583655201 HandBrkSts 500;
BA_ "SigType" SG_ 2583655201 HandBrkSts 4;
BA_ "CI_ParId" SG_ 2583655201 LckUnlckReqSrc "ID2553";
BA_ "CI_SigId" SG_ 2583655201 LckUnlckReqSrc 41954;
BA_ "CI_SigName" SG_ 2583655201 LckUnlckReqSrc "Lock Unlock Request Source";
BA_ "GenSigSendType" SG_ 2583655201 LckUnlckReqSrc 3;
BA_ "GenSigTimeoutTime_PCM" SG_ 2583655201 LckUnlckReqSrc 500;
BA_ "SigType" SG_ 2583655201 LckUnlckReqSrc 4;
BA_ "CI_ParId" SG_ 2583655201 ParkBrkCmd "5630";
BA_ "CI_SigId" SG_ 2583655201 ParkBrkCmd 45403;
BA_ "CI_SigName" SG_ 2583655201 ParkBrkCmd "Park Brake Command";
BA_ "GenSigSendType" SG_ 2583655201 ParkBrkCmd 3;
BA_ "GenSigTimeoutTime_PCM" SG_ 2583655201 ParkBrkCmd 500;
BA_ "SPN" SG_ 2583655201 ParkBrkCmd 5630;
BA_ "SigType" SG_ 2583655201 ParkBrkCmd 4;
BA_ "CI_ParId" SG_ 2583655201 DevSts "ID1542";
BA_ "CI_SigId" SG_ 2583655201 DevSts 41952;
BA_ "CI_SigName" SG_ 2583655201 DevSts "Device Status";
BA_ "GenSigSendType" SG_ 2583655201 DevSts 3;
BA_ "GenSigTimeoutTime_PCM" SG_ 2583655201 DevSts 500;
BA_ "CI_ParId" SG_ 2583655201 KeyCylSts "ID1524";
BA_ "CI_SigId" SG_ 2583655201 KeyCylSts 41951;
BA_ "CI_SigName" SG_ 2583655201 KeyCylSts "Key Cylinder Status";
BA_ "GenSigSendType" SG_ 2583655201 KeyCylSts 3;
BA_ "GenSigTimeoutTime_PCM" SG_ 2583655201 KeyCylSts 500;
BA_ "SigType" SG_ 2583655201 KeyCylSts 4;
BA_ "CI_ParId" SG_ 2583655201 OpenStsOfDoor7 "3431";
BA_ "CI_SigId" SG_ 2583655201 OpenStsOfDoor7 41950;
BA_ "CI_SigName" SG_ 2583655201 OpenStsOfDoor7 "Open Status of Door 7";
BA_ "GenSigSendType" SG_ 2583655201 OpenStsOfDoor7 3;
BA_ "GenSigTimeoutTime_PCM" SG_ 2583655201 OpenStsOfDoor7 500;
BA_ "SPN" SG_ 2583655201 OpenStsOfDoor7 3431;
BA_ "SigType" SG_ 2583655201 OpenStsOfDoor7 4;
BA_ "CI_ParId" SG_ 2583655201 LckStsOfDoor7 "3430";
BA_ "CI_SigId" SG_ 2583655201 LckStsOfDoor7 41949;
BA_ "CI_SigName" SG_ 2583655201 LckStsOfDoor7 "Lock Status of Door 7";
BA_ "GenSigSendType" SG_ 2583655201 LckStsOfDoor7 3;
BA_ "GenSigTimeoutTime_PCM" SG_ 2583655201 LckStsOfDoor7 500;
BA_ "SPN" SG_ 2583655201 LckStsOfDoor7 3430;
BA_ "SigType" SG_ 2583655201 LckStsOfDoor7 4;
BA_ "CI_ParId" SG_ 2583655201 OpenStsOfDoor6 "3428";
BA_ "CI_SigId" SG_ 2583655201 OpenStsOfDoor6 41948;
BA_ "CI_SigName" SG_ 2583655201 OpenStsOfDoor6 "Open Status of Door 6";
BA_ "GenSigSendType" SG_ 2583655201 OpenStsOfDoor6 3;
BA_ "GenSigTimeoutTime_PCM" SG_ 2583655201 OpenStsOfDoor6 500;
BA_ "SPN" SG_ 2583655201 OpenStsOfDoor6 3428;
BA_ "SigType" SG_ 2583655201 OpenStsOfDoor6 4;
BA_ "CI_ParId" SG_ 2583655201 OpenStsOfDoor5 "3425";
BA_ "CI_SigId" SG_ 2583655201 OpenStsOfDoor5 41947;
BA_ "CI_SigName" SG_ 2583655201 OpenStsOfDoor5 "Open Status of Door 5";
BA_ "GenSigSendType" SG_ 2583655201 OpenStsOfDoor5 3;
BA_ "GenSigTimeoutTime_PCM" SG_ 2583655201 OpenStsOfDoor5 500;
BA_ "SPN" SG_ 2583655201 OpenStsOfDoor5 3425;
BA_ "SigType" SG_ 2583655201 OpenStsOfDoor5 4;
BA_ "CI_ParId" SG_ 2583655201 OpenStsOfDoor4 "3422";
BA_ "CI_SigId" SG_ 2583655201 OpenStsOfDoor4 41946;
BA_ "CI_SigName" SG_ 2583655201 OpenStsOfDoor4 "Open Status of Door 4";
BA_ "GenSigSendType" SG_ 2583655201 OpenStsOfDoor4 3;
BA_ "GenSigTimeoutTime_PCM" SG_ 2583655201 OpenStsOfDoor4 500;
BA_ "SPN" SG_ 2583655201 OpenStsOfDoor4 3422;
BA_ "SigType" SG_ 2583655201 OpenStsOfDoor4 4;
BA_ "CI_ParId" SG_ 2583655201 OpenStsOfDoor3 "3419";
BA_ "CI_SigId" SG_ 2583655201 OpenStsOfDoor3 41945;
BA_ "CI_SigName" SG_ 2583655201 OpenStsOfDoor3 "Open Status of Door 3";
BA_ "GenSigSendType" SG_ 2583655201 OpenStsOfDoor3 3;
BA_ "GenSigTimeoutTime_PCM" SG_ 2583655201 OpenStsOfDoor3 500;
BA_ "SPN" SG_ 2583655201 OpenStsOfDoor3 3419;
BA_ "SigType" SG_ 2583655201 OpenStsOfDoor3 4;
BA_ "CI_ParId" SG_ 2583655201 OpenStsOfDoor2 "3416";
BA_ "CI_SigId" SG_ 2583655201 OpenStsOfDoor2 41944;
BA_ "CI_SigName" SG_ 2583655201 OpenStsOfDoor2 "Open Status of Door 2";
BA_ "GenSigSendType" SG_ 2583655201 OpenStsOfDoor2 3;
BA_ "GenSigTimeoutTime_PCM" SG_ 2583655201 OpenStsOfDoor2 500;
BA_ "SPN" SG_ 2583655201 OpenStsOfDoor2 3416;
BA_ "SigType" SG_ 2583655201 OpenStsOfDoor2 4;
BA_ "CI_ParId" SG_ 2583655201 OpenStsOfDoor1 "3413";
BA_ "CI_SigId" SG_ 2583655201 OpenStsOfDoor1 41943;
BA_ "CI_SigName" SG_ 2583655201 OpenStsOfDoor1 "Open Status of Door 1";
BA_ "GenSigSendType" SG_ 2583655201 OpenStsOfDoor1 3;
BA_ "GenSigTimeoutTime_PCM" SG_ 2583655201 OpenStsOfDoor1 500;
BA_ "SPN" SG_ 2583655201 OpenStsOfDoor1 3413;
BA_ "SigType" SG_ 2583655201 OpenStsOfDoor1 4;
BA_ "CI_ParId" SG_ 2583655201 LckStsOfDoor5 "3424";
BA_ "CI_SigId" SG_ 2583655201 LckStsOfDoor5 41942;
BA_ "CI_SigName" SG_ 2583655201 LckStsOfDoor5 "Lock Status of Door 5";
BA_ "GenSigSendType" SG_ 2583655201 LckStsOfDoor5 3;
BA_ "GenSigTimeoutTime_PCM" SG_ 2583655201 LckStsOfDoor5 500;
BA_ "SPN" SG_ 2583655201 LckStsOfDoor5 3424;
BA_ "SigType" SG_ 2583655201 LckStsOfDoor5 4;
BA_ "CI_ParId" SG_ 2583655201 LckStsOfDoor4 "3421";
BA_ "CI_SigId" SG_ 2583655201 LckStsOfDoor4 41941;
BA_ "CI_SigName" SG_ 2583655201 LckStsOfDoor4 "Lock Status of Door 4";
BA_ "GenSigSendType" SG_ 2583655201 LckStsOfDoor4 3;
BA_ "GenSigTimeoutTime_PCM" SG_ 2583655201 LckStsOfDoor4 500;
BA_ "SPN" SG_ 2583655201 LckStsOfDoor4 3421;
BA_ "SigType" SG_ 2583655201 LckStsOfDoor4 4;
BA_ "CI_ParId" SG_ 2583655201 LckStsOfDoor3 "3418";
BA_ "CI_SigId" SG_ 2583655201 LckStsOfDoor3 41940;
BA_ "CI_SigName" SG_ 2583655201 LckStsOfDoor3 "Lock Status of Door 3";
BA_ "GenSigSendType" SG_ 2583655201 LckStsOfDoor3 3;
BA_ "GenSigTimeoutTime_PCM" SG_ 2583655201 LckStsOfDoor3 500;
BA_ "SPN" SG_ 2583655201 LckStsOfDoor3 3418;
BA_ "SigType" SG_ 2583655201 LckStsOfDoor3 4;
BA_ "CI_ParId" SG_ 2583655201 LckStsOfDoor2 "3415";
BA_ "CI_SigId" SG_ 2583655201 LckStsOfDoor2 41939;
BA_ "CI_SigName" SG_ 2583655201 LckStsOfDoor2 "Lock Status of Door 2";
BA_ "GenSigSendType" SG_ 2583655201 LckStsOfDoor2 3;
BA_ "GenSigTimeoutTime_PCM" SG_ 2583655201 LckStsOfDoor2 500;
BA_ "SPN" SG_ 2583655201 LckStsOfDoor2 3415;
BA_ "SigType" SG_ 2583655201 LckStsOfDoor2 4;
BA_ "CI_ParId" SG_ 2583655201 LckStsOfDoor1 "3412";
BA_ "CI_SigId" SG_ 2583655201 LckStsOfDoor1 41938;
BA_ "CI_SigName" SG_ 2583655201 LckStsOfDoor1 "Lock Status of Door 1";
BA_ "GenSigSendType" SG_ 2583655201 LckStsOfDoor1 3;
BA_ "GenSigTimeoutTime_PCM" SG_ 2583655201 LckStsOfDoor1 500;
BA_ "SPN" SG_ 2583655201 LckStsOfDoor1 3412;
BA_ "SigType" SG_ 2583655201 LckStsOfDoor1 4;
VAL_ 2566890251 BsmRctbFail 0 "No RCTB failure" 1 "RCTB failure" 2 "BSM RCTB function error" 3 "RCTB function N/A on BSM" ;
VAL_ 2566890251 BsmAebFail 0 "No AEB failure" 1 "AEB failure" 2 "BSM AEB function error" 3 "AEB function N/A on BSM" ;
VAL_ 2566890251 BsmBtnSts 0 "Not Pressed" 1 "Pressed" ;
VAL_ 2566890251 RollerbenchActvSts 0 "Not active" 1 "Active" 2 "Error" 3 "Not Available" ;
VAL_ 2566890251 HbaSts 0 "Fully Oper/Passive but Installed" 1 "Fully Oper/Active-Intervention" 2 "Not Fully Operational/Error" 3 "Not available/Not Installed" ;
VAL_ 2566890251 CwaSts 0 "Fully Oper/Passive but Installed" 1 "Fully Oper/Active-Intervention" 2 "Not Fully Operational/Error" 3 "Not available/Not Installed" ;
VAL_ 2566890251 MsrSts 0 "Fully Oper/Passive but Installed" 1 "Fully Oper/Active-Intervention" 2 "Not Fully Operational/Error" 3 "Not available/Not Installed" ;
VAL_ 2566890251 HhSts 0 "Fully Oper/Passive but Installed" 1 "Fully Oper/Active-Intervention" 2 "Not Fully Operational/Error" 3 "Not available/Not Installed" ;
VAL_ 2566890251 VdcSts 0 "Fully Oper/Passive but Installed" 1 "Fully Oper/Active-Intervention" 2 "Not Fully Operational/Error" 3 "Not available/Not Installed" ;
VAL_ 2566890251 AsrSts 0 "Fully Oper/Passive but Installed" 1 "Fully Oper/Active-Intervention" 2 "Not Fully Operational/Error" 3 "Not available/Not Installed" ;
VAL_ 2566890251 AbsSts 0 "Fully Oper/Passive but Installed" 1 "Fully Oper/Active-Intervention" 2 "Not Fully Operational/Error" 3 "Not available/Not Installed" ;
VAL_ 2566890251 EbdSts 0 "Fully Oper/Passive but Installed" 1 "Fully Oper/Active-Intervention" 2 "Not Fully Operational/Error" 3 "Not available/Not Installed" ;
VAL_ 2566890251 Hdc 0 "Off" 1 "Enable" 2 "Active" 6 "Error Indicator" 7 "Not Available / Do not change" ;
VAL_ 2566890251 BrkSig 0 "Off" 1 "On" 2 "Reserved" 3 "Not Available" ;
VAL_ 2566890251 VehSoftStop 0 "Off" 1 "On" 2 "Error Indicator" 3 "Not Available / No Action" ;
VAL_ 2566890251 Eol 0 "No EOLProgramming" 1 "EOL Programming" ;
VAL_ 2566890251 VehMov 0 "Off" 1 "On" 2 "Error Indicator" 3 "Not Available" ;
VAL_ 2566890251 ParkBrkSw 0 "Not set" 1 "Set" 2 "Error" 3 "Not Available" ;
VAL_ 2566890251 ParkBrkRelsInhSts 0 "Not inhibited" 1 "Inhibited" 2 "Error" ;
VAL_ 2566890251 ParkBrkAct 0 "Parking brake actuator inactive" 1 "Parking brake actuator active" 2 "Error" 3 "Not Available" ;
VAL_ 2566890251 XbrSysSts_FFA30B 0 "Any demand will be accepted" 1 "Only highest Prio dem accepted" 2 "No demand will be accepted" 3 "Not Available" ;
VAL_ 2566890251 ParkBrkActFullyActv_FFA30B 0 "Not fully activated" 1 "Fully activated" 2 "Error" 3 "Not Available" ;
VAL_ 2566887435 EpbBtnRawSts 0 "Button Released" 1 "Button Pushed" 2 "Button Pulled" 3 "Res" 4 "Res" 5 "Res" 6 "Button Error" 7 "Button Not Available" ;
VAL_ 2566854382 LoadType 0 "Undefined load type" 1 "Goods" 2 "Passengers" ;
VAL_ 2566854382 LastOpPlaceRecAuthenticationSts 0 "Not authenticated" 1 "Authenticated" 255 "RFU" ;
VAL_ 2566854382 LastOpPlaceRecLong 8388607 "Not Available" ;
VAL_ 2566854382 LastOpPlaceRecLat 8388607 "Not Available" ;
VAL_ 2566854382 LastOpType 0 "RFU" 1 "Load operation" 2 "Unload operation" 3 "Simult load/unload op" 255 "RFU" ;
VAL_ 2566854382 LastBorderCrossingPlaceRecAuthen 0 "Not authenticated" 1 "Authenticated" 255 "RFU" ;
VAL_ 2566854382 LastBorderCrossingPlaceRecLong 8388607 "Not Available" ;
VAL_ 2566854382 LastBorderCrossingPlaceRecLat 8388607 "Not Available" ;
VAL_ 2566854382 LastCntryEntered 0 "No information available" 1 "Austria" 2 "Albania" 3 "Andorra" 4 "Armenia" 5 "Azerbaijan" 6 "Belgium" 7 "Bulgaria" 8 "Bosnia and Herzegovina" 9 "Belarus" 10 "Switzerland" 11 "Cyprus" 12 "Czech Republic" 13 "Germany" 14 "Denmark" 15 "Spain" 16 "Estonia" 17 "France" 18 "Finland" 19 "Liechtenstein" 20 "Faeroe Islands" 21 "United Kingdom" 22 "Georgia" 23 "Greece" 24 "Hungary" 25 "Croatia" 26 "Italy" 27 "Ireland" 28 "Iceland" 29 "Kazakhstan" 30 "Luxembourg" 31 "Lithuania" 32 "Latvia" 33 "Malta" 34 "Monaco" 35 "Republic of Moldova" 36 "Macedonia" 37 "Norway" 38 "Netherlands" 39 "Portugal" 40 "Poland" 41 "Romania" 42 "San Marino" 43 "Russian Federation" 44 "Sweden" 45 "Slovakia" 46 "Slovenia" 47 "Turkmenistan" 48 "Turkey" 49 "Ukraine" 50 "Vatican City" 52 "Montenegro" 53 "Serbia" 54 "Uzbekistan" 55 "Tajikistan" 253 "European Community" 254 "Rest of Europe" 255 "Rest of the world" ;
VAL_ 2566854382 LastCntryLeft 0 "No information available" 1 "Austria" 2 "Albania" 3 "Andorra" 4 "Armenia" 5 "Azerbaijan" 6 "Belgium" 7 "Bulgaria" 8 "Bosnia and Herzegovina" 9 "Belarus" 10 "Switzerland" 11 "Cyprus" 12 "Czech Republic" 13 "Germany" 14 "Denmark" 15 "Spain" 16 "Estonia" 17 "France" 18 "Finland" 19 "Liechtenstein" 20 "Faeroe Islands" 21 "United Kingdom" 22 "Georgia" 23 "Greece" 24 "Hungary" 25 "Croatia" 26 "Italy" 27 "Ireland" 28 "Iceland" 29 "Kazakhstan" 30 "Luxembourg" 31 "Lithuania" 32 "Latvia" 33 "Malta" 34 "Monaco" 35 "Republic of Moldova" 36 "Macedonia" 37 "Norway" 38 "Netherlands" 39 "Portugal" 40 "Poland" 41 "Romania" 42 "San Marino" 43 "Russian Federation" 44 "Sweden" 45 "Slovakia" 46 "Slovenia" 47 "Turkmenistan" 48 "Turkey" 49 "Ukraine" 50 "Vatican City" 52 "Montenegro" 53 "Serbia" 54 "Uzbekistan" 55 "Tajikistan" 253 "European Community" 254 "Rest of Europe" 255 "Rest of the world" ;
VAL_ 2566897985 CallLogIx10Type 0 "Empty Log Item" 1 "Rx Call" 2 "Rx Missed Call" 3 "Rx Cancelled Call" 4 "Tx Call" 5 "Tx Missed Call" 6 "Tx Cancelled Call" 7 "Reserved" 8 "Reserved" 9 "Reserved" 10 "Rx Message" 11 "TxMessage" 12 "Reserved" 13 "Reserved" 14 "Error Indicator" 15 "Not Available" ;
VAL_ 2566897985 CallLogIx9Type 0 "Empty Log Item" 1 "Rx Call" 2 "Rx Missed Call" 3 "Rx Cancelled Call" 4 "Tx Call" 5 "Tx Missed Call" 6 "Tx Cancelled Call" 7 "Reserved" 8 "Reserved" 9 "Reserved" 10 "Rx Message" 11 "TxMessage" 12 "Reserved" 13 "Reserved" 14 "Error Indicator" 15 "Not Available" ;
VAL_ 2566897985 CallLogIx8Type 0 "Empty Log Item" 1 "Rx Call" 2 "Rx Missed Call" 3 "Rx Cancelled Call" 4 "Tx Call" 5 "Tx Missed Call" 6 "Tx Cancelled Call" 7 "Reserved" 8 "Reserved" 9 "Reserved" 10 "Rx Message" 11 "TxMessage" 12 "Reserved" 13 "Reserved" 14 "Error Indicator" 15 "Not Available" ;
VAL_ 2566897985 CallLogIx7Type 0 "Empty Log Item" 1 "Rx Call" 2 "Rx Missed Call" 3 "Rx Cancelled Call" 4 "Tx Call" 5 "Tx Missed Call" 6 "Tx Cancelled Call" 7 "Reserved" 8 "Reserved" 9 "Reserved" 10 "Rx Message" 11 "TxMessage" 12 "Reserved" 13 "Reserved" 14 "Error Indicator" 15 "Not Available" ;
VAL_ 2566897985 CallLogIx6Type 0 "Empty Log Item" 1 "Rx Call" 2 "Rx Missed Call" 3 "Rx Cancelled Call" 4 "Tx Call" 5 "Tx Missed Call" 6 "Tx Cancelled Call" 7 "Reserved" 8 "Reserved" 9 "Reserved" 10 "Rx Message" 11 "TxMessage" 12 "Reserved" 13 "Reserved" 14 "Error Indicator" 15 "Not Available" ;
VAL_ 2566897985 CallLogIx5Type 0 "Empty Log Item" 1 "Rx Call" 2 "Rx Missed Call" 3 "Rx Cancelled Call" 4 "Tx Call" 5 "Tx Missed Call" 6 "Tx Cancelled Call" 7 "Reserved" 8 "Reserved" 9 "Reserved" 10 "Rx Message" 11 "TxMessage" 12 "Reserved" 13 "Reserved" 14 "Error Indicator" 15 "Not Available" ;
VAL_ 2566897985 CallLogIx4Type 0 "Empty Log Item" 1 "Rx Call" 2 "Rx Missed Call" 3 "Rx Cancelled Call" 4 "Tx Call" 5 "Tx Missed Call" 6 "Tx Cancelled Call" 7 "Reserved" 8 "Reserved" 9 "Reserved" 10 "Rx Message" 11 "TxMessage" 12 "Reserved" 13 "Reserved" 14 "Error Indicator" 15 "Not Available" ;
VAL_ 2566897985 CallLogIx3Type 0 "Empty Log Item" 1 "Rx Call" 2 "Rx Missed Call" 3 "Rx Cancelled Call" 4 "Tx Call" 5 "Tx Missed Call" 6 "Tx Cancelled Call" 7 "Reserved" 8 "Reserved" 9 "Reserved" 10 "Rx Message" 11 "TxMessage" 12 "Reserved" 13 "Reserved" 14 "Error Indicator" 15 "Not Available" ;
VAL_ 2566897985 CallLogIx2Type 0 "Empty Log Item" 1 "Rx Call" 2 "Rx Missed Call" 3 "Rx Cancelled Call" 4 "Tx Call" 5 "Tx Missed Call" 6 "Tx Cancelled Call" 7 "Reserved" 8 "Reserved" 9 "Reserved" 10 "Rx Message" 11 "TxMessage" 12 "Reserved" 13 "Reserved" 14 "Error Indicator" 15 "Not Available" ;
VAL_ 2566897985 CallLogIx1Type 0 "Empty Log Item" 1 "Rx Call" 2 "Rx Missed Call" 3 "Rx Cancelled Call" 4 "Tx Call" 5 "Tx Missed Call" 6 "Tx Cancelled Call" 7 "Reserved" 8 "Reserved" 9 "Reserved" 10 "Rx Message" 11 "TxMessage" 12 "Reserved" 13 "Reserved" 14 "Error Indicator" 15 "Not Available" ;
VAL_ 2566897985 CallLogEntriesNum 13 "Download in progress" 14 "Error Indicator" 15 "Not Available" ;
VAL_ 2566897985 DevIx 0 "Device 1" 1 "Device 2" 2 "Error" 3 "No Device Connected" ;
VAL_ 2566897985 TelephoneConn 0 "Not connected" 1 "Connected" 2 "Error Indicator" 3 "Not Available" ;
VAL_ 2566882327 AewhSchedulingSts 0 "No Schedule" 1 "Schedule Active" 2 "Error" 3 "Not Available" ;
VAL_ 2566882327 ClimaCtrlVentilMode 0 "Low" 1 "Medium" 2 "High" 3 "Not Available" ;
VAL_ 2566882327 ClimaCtrlMode 0 "Off" 1 "Heating Status/Command" 2 "Cooling Status/Command" 3 "Ventilation Status/Command" 4 "AWH Status/Command" 5 "AWH + Heating Status/Command" 10 "Immediate Heating Setting" 11 "Immediate Cooling Setting" 12 "Immediate Ventilation Setting" 14 "Error Condition" 15 "Not Available / No Action" ;
VAL_ 2566882337 AewhFunctSts 0 "N/A due to Low Battery" 1 "N/A due to Low Fuel" 2 "N/A due to low Fuel and Battery" 3 "N/A due to Engine On" 4 "Available and Active" 5 "Available and Not Active" 6 "Error" 7 "Not Available" ;
VAL_ 2566882337 ClimaCtrlMode_FF8421 0 "Off" 1 "Heating Status/Command" 2 "Cooling Status/Command" 3 "Ventilation Status/Command" 4 "AWH Status/Command" 5 "AWH + Heating Status/Command" 10 "Immediate Heating Setting" 11 "Immediate Cooling Setting" 12 "Immediate Ventilation Setting" 14 "Error Condition" 15 "Not Available / No Action" ;
VAL_ 2566882337 EcoMode 0 "Off" 1 "On (Eco Mode)" 2 "Power Mode" 3 "Not Available / No Action" ;
VAL_ 2566882378 AewhSchedulingSts_FF844A 0 "No Schedule" 1 "Schedule Active" 2 "Error" 3 "Not Available" ;
VAL_ 2566882378 ClimaCtrlVentilMode_FF844A 0 "Low" 1 "Medium" 2 "High" 3 "Not Available" ;
VAL_ 2566882378 ClimaCtrlMode_FF844A 0 "Off" 1 "Heating Status/Command" 2 "Cooling Status/Command" 3 "Ventilation Status/Command" 4 "AWH Status/Command" 5 "AWH + Heating Status/Command" 10 "Immediate Heating Setting" 11 "Immediate Cooling Setting" 12 "Immediate Ventilation Setting" 14 "Error Condition" 15 "Not Available / No Action" ;
VAL_ 2583654960 CdcActvMode 0 "Mode #1 / Auto" 1 "Mode #2 / High load" 2 "Mode #3 / Comfort" 3 "Mode #4 / White road" 4 "Mode #5" 5 "Mode #6" 6 "Mode #7" 7 "Mode #8" 8 "Mode #9" 9 "Mode #10" 10 "Mode #11" 11 "Reserved" 14 "Error" 15 "Not available" ;
VAL_ 2566895393 ParkBrkCfg 0 "Handlever" 1 "EPB" 2 "Not used" 3 "Not used" ;
VAL_ 2566895393 HydrSysType 0 "Unknown/Not Programmed/Invalid" 1 "X Circuit" 2 "H Circuit" 3 "Reserved" ;
VAL_ 2566895393 BodyType 0 "Unknown/Not programmed/Invalid" 1 "BT1, Box type truck, Van" 2 "BT2, Platform truck, Pick-up" 3 "BT3, Transf. truck, Recreat. box" ;
VAL_ 2566895393 RetCfg 0 "Absent" 1 "Present" ;
VAL_ 2566895393 ParkBrkType 0 "Invalid/Not Programmed" 1 "Drum in Hat 190" 2 "Drum in Hat 172" 3 "PFC 52" 4 "PFC 60" ;
VAL_ 2566895393 EngTypeVar4 0 "Reserved" 1 "Reserved" 2 "F1A 106/116WG" 3 "F1A/156VGT" 4 "F1A 126/130WG" 5 "F1A 146/136VGT" 6 "F1C 146/150WG" 7 "F1C 170/180VGT E6" 8 "F1C 170/180VGT EVI" 9 "F1C 110/136 Bi-Fuel" 10 "F1C 205/210 DS" 11 "F1C 146WG E4 extra EU" 12 "F1C 146/150WG EVI" 13 "Reserved" 14 "Electric 100 kW" 15 "Electric 140 kW" ;
VAL_ 2566895393 SuspFront 0 "Unknown/Not Programmed/Invalid" 1 "Normal" 2 "Torsion" 3 "Air - VB" ;
VAL_ 2566895393 SuspRear 0 "Unknown/Not Programmed/Invalid" 1 "Spring" 2 "Air" 3 "Air - VB" ;
VAL_ 2566895393 WhCircumf3 0 "Not Programmed" ;
VAL_ 2566895393 WhBase2 0 "Invalid/Not Programmed" 1 "3000mm" 2 "3300/3450mm" 3 "3750/3950mm" 4 "4100mm" 5 "4350mm" 6 "4750mm" 7 "3520mm" 8 "3050mm (4x4)" 9 "3400mm (4x4)" 10 "5000/5500mm" 11 "5500mm" 12 "Reserved1" 13 "Reserved2" 14 "Reserved3" 15 "Reserved4" ;
VAL_ 2566895393 MaxVehCap 0 "Invalid/Not Programmed" 1 "3.0-3.3t Single wheel" 2 "3.5t Single wheel" 3 "3.5t Twin wheels" 4 "3.8-4.0t Single wheel" 5 "4.0-4.5t Twin wheels" 6 "5.0-5.5t Twin wheels" 7 "6.0-6.5t Twin wheels" 8 "7.0-7.5t Twin wheels" 9 "4.3t Single Wheels" ;
VAL_ 2566895393 ElnBrkSysTypeVar 0 "Absent, not programmed" 1 "ABS" 3 "VDC, Hill Holder, ASR" ;
VAL_ 2566895393 GbxTypeVar2 0 "Invalid" 1 "FIAT gearbox" 2 "FIAT gearbox" 3 "FIAT gearbox" 4 "FIAT gearbox" 5 "Manual 2830.5" 6 "Manual 2840.6" 7 "Manual 2850.6" 8 "Robotic 6AS400" 9 "Manual 2835.6" 10 "Automated ZF8HP" 11 "Allison 1000" ;
VAL_ 2566910273 DevIx_FFF141 0 "Device 1" 1 "Device 2" 2 "Error" 3 "No Device Connected" ;
VAL_ 2566883879 RngDeterminationRstFdbk 0 "OK" 1 "NOK" 2 "Error" 3 "Not Available" ;
VAL_ 2566883879 DrivProfIdFdbk 0 "No Profile Selection" 1 "Profile 1" 2 "Profile 2" 3 "Profile 3" 4 "Profile 4" 5 "Profile 5" 6 "Error" 7 "Not Available" ;
VAL_ 2566883914 RegenBrkModeProf 0 "No Selection" 1 "Regenerative" 2 "One Pedal Drive" 3 "Coasting" 4 "Not Used" 5 "Not Used" 6 "Error" 7 "Not Available" ;
VAL_ 2566883914 TractModeProf 0 "No Selection" 1 "Normal" 2 "Eco" 3 "Performance" 4 "Not Used" 5 "Not Used" 6 "Error" 7 "Not Available" ;
VAL_ 2566883914 RngDeterminationRst 0 "No Reset" 1 "Reset Request" 2 "Error" 3 "Not Available" ;
VAL_ 2566883914 DrivProfId 0 "No Profile Selection" 1 "Profile 1" 2 "Profile 2" 3 "Profile 3" 4 "Profile 4" 5 "Profile 5" 6 "Error" 7 "Not Available" ;
VAL_ 2566849774 CodriverVdoPersDataCons 0 "Refused" 1 "Permitted" ;
VAL_ 2566849774 DrivVdoPersDataCons 0 "Refused" 1 "Permitted" ;
VAL_ 2566849774 CodriverItsPersDataCons 0 "Refused" 1 "Permitted" ;
VAL_ 2566849774 DrivItsPersDataCons 0 "Refused" 1 "Permitted" ;
VAL_ 2566865994 DseIxBenf_10 254 "Error" 255 "Not Available" ;
VAL_ 2566865994 DseIxVal_10 254 "Error" 255 "Not Available" ;
VAL_ 2566865994 DseIxFrzSts_10 0 "Running" 1 "Freeze" 2 "Error Indicator" 3 "Not Available" ;
VAL_ 2566865994 DseIxTrend_10 0 "Negative Trend" 1 "Stationary rend" 2 "PositiveTrend" 3 "Not Available" ;
VAL_ 2566865994 DseIxBenf_9 254 "Error" 255 "Not Available" ;
VAL_ 2566865994 DseIxVal_9 254 "Error" 255 "Not Available" ;
VAL_ 2566865994 DseIxFrzSts_9 0 "Running" 1 "Freeze" 2 "Error Indicator" 3 "Not Available" ;
VAL_ 2566865994 DseIxTrend_9 0 "Negative Trend" 1 "Stationary rend" 2 "PositiveTrend" 3 "Not Available" ;
VAL_ 2566865994 DseIxBenf_8 254 "Error" 255 "Not Available" ;
VAL_ 2566865994 DseIxVal_8 254 "Error" 255 "Not Available" ;
VAL_ 2566865994 DseIxFrzSts_8 0 "Running" 1 "Freeze" 2 "Error Indicator" 3 "Not Available" ;
VAL_ 2566865994 DseIxTrend_8 0 "Negative Trend" 1 "Stationary rend" 2 "PositiveTrend" 3 "Not Available" ;
VAL_ 2566865994 DseIxBenf_7 254 "Error" 255 "Not Available" ;
VAL_ 2566865994 DseIxVal_7 254 "Error" 255 "Not Available" ;
VAL_ 2566865994 DseIxFrzSts_7 0 "Running" 1 "Freeze" 2 "Error Indicator" 3 "Not Available" ;
VAL_ 2566865994 DseIxTrend_7 0 "Negative Trend" 1 "Stationary rend" 2 "PositiveTrend" 3 "Not Available" ;
VAL_ 2566865994 DseIxBenf_6 254 "Error" 255 "Not Available" ;
VAL_ 2566865994 DseIxVal_6 254 "Error" 255 "Not Available" ;
VAL_ 2566865994 DseIxFrzSts_6 0 "Running" 1 "Freeze" 2 "Error Indicator" 3 "Not Available" ;
VAL_ 2566865994 DseIxTrend_6 0 "Negative Trend" 1 "Stationary rend" 2 "PositiveTrend" 3 "Not Available" ;
VAL_ 2566865994 DseIxBenf_5 254 "Error" 255 "Not Available" ;
VAL_ 2566865994 DseIxVal_5 254 "Error" 255 "Not Available" ;
VAL_ 2566865994 DseIxFrzSts_5 0 "Running" 1 "Freeze" 2 "Error Indicator" 3 "Not Available" ;
VAL_ 2566865994 DseIxTrend_5 0 "Negative Trend" 1 "Stationary rend" 2 "PositiveTrend" 3 "Not Available" ;
VAL_ 2566865994 DseIxBenf_4 254 "Error" 255 "Not Available" ;
VAL_ 2566865994 DseIxVal_4 254 "Error" 255 "Not Available" ;
VAL_ 2566865994 DseIxFrzSts_4 0 "Running" 1 "Freeze" 2 "Error Indicator" 3 "Not Available" ;
VAL_ 2566865994 DseIxTrend_4 0 "Negative Trend" 1 "Stationary rend" 2 "PositiveTrend" 3 "Not Available" ;
VAL_ 2566865994 DseIxBenf_3_EngUse 254 "Error" 255 "Not Available" ;
VAL_ 2566865994 DseIxVal_3_EngUse 254 "Error" 255 "Not Available" ;
VAL_ 2566865994 DseIxFrzSts_3_EngUse 0 "Running" 1 "Freeze" 2 "Error Indicator" 3 "Not Available" ;
VAL_ 2566865994 DseIxTrend_3_EngUse 0 "Negative Trend" 1 "Stationary rend" 2 "PositiveTrend" 3 "Not Available" ;
VAL_ 2566865994 DseIxBenf_2_Decel 254 "Error" 255 "Not Available" ;
VAL_ 2566865994 DseIxVal_2_Decel 254 "Error" 255 "Not Available" ;
VAL_ 2566865994 DseIxFrzSts_2_Decel 0 "Running" 1 "Freeze" 2 "Error Indicator" 3 "Not Available" ;
VAL_ 2566865994 DseIxTrend_2_Decel 0 "Negative Trend" 1 "Stationary rend" 2 "PositiveTrend" 3 "Not Available" ;
VAL_ 2566865994 DseIxBenf_1_Accel 254 "Error" 255 "Not Available" ;
VAL_ 2566865994 DseIxVal_1_Accel 254 "Error" 255 "Not Available" ;
VAL_ 2566865994 DseIxFrzSts_1_Accel 0 "Running" 1 "Freeze" 2 "Error Indicator" 3 "Not Available" ;
VAL_ 2566865994 DseIxTrend_1_Accel 0 "Negative Trend" 1 "Stationary rend" 2 "PositiveTrend" 3 "Not Available" ;
VAL_ 2566865994 DseEvalTime 64256 "Overflow" 65535 "Not Available" ;
VAL_ 2566865994 DseEvalDist 64256 "Overflow" 65535 "Not Available" ;
VAL_ 2566865994 DseStartMissTs -1 "Not Available" ;
VAL_ 2566865994 DsePopupIx 0 "Not Available" ;
VAL_ 2566865994 DsePopupIcon 0 "No Icon" 1 "Good" 2 "Bad" 3 "Bonus" 4 "Info" 15 "Not Available" ;
VAL_ 2566865994 DseSts 0 "Off" 1 "Standby (Vehicle Not Supported)" 2 "Running" 3 "Busy" 14 "Error Indicator" 15 "Not Available" ;
VAL_ 2583650122 BenfEnergy 0 "False" 1 "True" 2 "Reserved" 3 "not available" ;
VAL_ 2583650122 TrendEnergy 0 "Not available" 1 "Negative Trend" 2 "Stationary Trend" 3 "Positive Trend" ;
VAL_ 2583650122 ValEnergy 0 "False" 1 "True" 2 "Reserved" 3 "not available" ;
VAL_ 2583650122 ScoreEnergy 0 ": Score not calculated" 1 ": Valid Score (Worst)" 101 ": Valid Score (Best)" ;
VAL_ 2566895946 TripEndReas 0 "Not Ended" 1 "Key Off" 2 "Driver Id Changed" 3 "User Reset" 4 "Telematic App Reset" ;
VAL_ 2566895946 TripActv 0 "False" 1 "True" 2 "Reserved" 3 "Not available" ;
VAL_ 2566895946 TripEnded 0 "False" 1 "True" 2 "Reserved" 3 "Not available" ;
VAL_ 2566895946 TripStarted 0 "False" 1 "True" 2 "Reserved" 3 "Not available" ;
VAL_ 2365562112 EcmTrqCtrlRdySts 0 "Not Ready" 1 "Ready" 2 "Error" 3 "Not Available" ;
VAL_ 2365562112 TransmCurGear_F9D00 0 "N" 1 "1 Gear" 2 "2 Gear" 3 "3 Gear" 4 "4 Gear" 5 "5 Gear" 6 "6 Gear" 7 "7 Gear" 8 "8 Gear" 12 "Reverse" 13 "Parking" 14 "Error" 15 "Not Available" ;
VAL_ 2365562112 DSig 0 "Normal operation" 1 "Fault" ;
VAL_ 2365562112 NeutrSensInfo 0 "Neutral not engaged" 1 "Neutral engaged" 2 "Error" 3 "Not Available" ;
VAL_ 2365562112 EngSts 0 "Off" 1 "Cranking" 2 "On" 3 "Not Available" ;
VAL_ 2365562112 StartRelayBcmCmd 0 "Not Active" 1 "Active" 2 "Error" 3 "Not available" ;
VAL_ 2365562112 BrkPedNcSw 0 "Not Active" 1 "Active" 2 "Error" 3 "Not available" ;
VAL_ 2365562112 BrkPedNoSw 0 "Not Active" 1 "Active" 2 "Error" 3 "Not available" ;
VAL_ 2365562112 CltOpenSw_F9D00 0 "Not fully pressed" 1 "Fully pressed" 2 "Error" 3 "Not Available" ;
VAL_ 2365562112 CltSw_F9D00 0 "Released" 1 "Depressed" 2 "Error" 3 "Not Available" ;
VAL_ 2566865482 SwVerField4 255 "Not Available" ;
VAL_ 2566865482 SwVerField3 255 "Not Available" ;
VAL_ 2566865482 SwVerField2 255 "Not Available" ;
VAL_ 2566865482 SwVerField1 255 "Not Available" ;
VAL_ 2566865482 SwUpdateSts 0 "Idlle" 1 "Update available" 2 "Downloading" 3 "Installing" 4 "Completed" 14 "Error" 15 "Not Available" ;
VAL_ 2365572627 AsilDConfor 0 "Does not conform (Permanently)" 1 "Conforms to ASIL D" 2 "Does not conform (Temporarily)" 3 "Not Available" ;
VAL_ 2365572627 ActSteerColTrq 4094 "Error" 4095 "Not Available" ;
VAL_ 2365572627 PacTrq 510 "Error" 511 "Not Available" ;
VAL_ 2365572627 ActSteerMotTrq 510 "Error" 511 "Not Available" ;
VAL_ 2365572627 LatCtrlFunctsReqSts 0 "Rejected or Not Received" 1 "Accepted/Int Open and Active" 2 "Reserved1" 3 "Reserved2" ;
VAL_ 2365572627 Angle 16382 "Error" 16383 "Not Available" ;
VAL_ 2365572627 LatCtrlFunctSts 0 "System available/no EPS Fault" 1 "EPS internal failure" 2 "LCF request failure" 3 "System N.A" ;
VAL_ 2365572627 AngleCal 0 "Not Calibrated" 1 "Calibrated" 2 "Error/Reserved" 3 "Not Available" ;
VAL_ 2566852883 SteerCtrlEcuTemp 254 "Error" 255 "Not Available" ;
VAL_ 2566852883 EpsSteerFrzFail 0 "No Freezing Issue" 1 "Freezing Fault" 2 "Severe Freezing Fault" 3 "EPS freezing logic Failure" 4 "Not Used1" 5 "Not Used2" 6 "Error" 7 "Not Available" ;
VAL_ 2566852883 AngleSpeed 2046 "Error" 2047 "Not Available" ;
VAL_ 2566852883 DrivHandsOffConfLev 0 "Level 0 (lower confidence)" 1 "Level 1" 2 "Level 2" 3 "Level 3" 4 "Level 4" 5 "Level 5" 6 "Level 6" 7 "Level 7" 8 "Level 8" 9 "Level 9" 10 "Level 10" 11 "Level 11" 12 "Level 12" 13 "Level 13" 14 "Level 14 (higher confidence" 15 "Not Available" ;
VAL_ 2566852883 DrivHandsOffDet 0 "Not detected" 1 "Detected" 2 "Error" 3 "Not Available" ;
VAL_ 2566852883 CtrlDevForSteerCtrl 0 "EPS/Driver" 1 "Camera" 2 "Park" 3 "Not Available/Not Valid" ;
VAL_ 2566852883 ExtVibrCtrlRdySts 0 "Off, not configured" 1 "On, ready" 2 "Error, not ready" 3 "Not Available / Not Supported" ;
VAL_ 2566852883 ExtAngleCtrlRdySts 0 "Off, not configured" 1 "On, ready" 2 "Error, not ready" 3 "Not Available / Not Supported" ;
VAL_ 2566852883 ExtTrqCtrlRdySts 0 "Off, not configured" 1 "On, ready" 2 "Error, not ready" 3 "Not Available / Not Supported" ;
VAL_ 2566852883 EpsOpSts 0 "Normal operation" 1 "Degraded operation" 2 "Limp Home" 3 "Assist Off" 7 "Not Available" ;
VAL_ 2566852883 EpsOpMode 0 "No request" 1 "EPS Internal Request 1" 2 "EPS Internal Request 2" 3 "EPS Internal Request 3" 4 "EPS Internal Request 4" 5 "Device 1 Torque Request" 6 "Device 1 Angle Request" 7 "Device 1 Vibration Request" 8 "Device 2 Torque Request" 9 "Device 2 Angle Request" 10 "Device 2 Vibration Reques" 11 "Device 3 Torque Request" 12 "Device 3 Angle Request" 13 "Device 3 Vibration Request" 14 "Other" 15 "Not Available" ;
VAL_ 2583640359 MsgCnt_FF3927 8 "Reserved1" 9 "Reserved2" 10 "Reserved3" 11 "Reserved4" 12 "Reserved5" 13 "Reserved6" 14 "Reserved7" 15 "Not Available, request honored" ;
VAL_ 2583640359 PeakDevCur 0 "Not active" 1 "Active" 2 "Error" 3 "Not available" ;
VAL_ 2583640359 LongDevCur 0 "Not active" 1 "Active" 2 "Error" 3 "Not available" ;
VAL_ 2583640359 EptoWaitingMode 0 "Off" 1 "Waiting mode active" 2 "Waiting mode not available" 3 "not used" 4 "not used" 5 "not used" 6 "Error" 7 "Not available" ;
VAL_ 2583640359 EngCons 0 "Consent not given" 1 "Consent given" 2 "Error" 3 "Not available" ;
VAL_ 2583640359 OperativeEptoSts 0 "Off" 1 "Ready" 2 "Engagement" 3 "Engaged" 4 "Disengagement" 5 "Suspended" 6 "Error" 7 "Not available" ;
VAL_ 2583639079 OperativeEptoSts_FF3427 0 "Off" 1 "Ready" 2 "Engagement" 3 "Engaged" 4 "Disengagement" 5 "Suspended" 6 "Error" 7 "Not available" ;
VAL_ 2566893315 EtcVehMovTypeOfErr 0 "No Fail" 1 "CryptDataNotOk" 2 "Missing Authentication" 4 "Internal Failure" ;
VAL_ 2566893315 EtcVehMovSts 0 "Not Inhibited" 1 "Inhibited" 2 "Error" 3 "Not Available/No Action" ;
VAL_ 2566893315 EcoLckGear 0 "No Eco Lock" 1 "Eco Lock" 2 "Error" 3 "Not Available" ;
VAL_ 2566893315 TransmCurGearAsilBConfor 0 "Does not conform (Permanently)" 1 "Conforms to ASIL B" 2 "Does not conform (Temporarily)" 3 "Not Available" ;
VAL_ 2566893315 TransmSelGear_FFAF03 0 "N" 1 "1 Gear" 2 "2 Gear" 3 "3 Gear" 4 "4 Gear" 5 "5 Gear" 6 "6 Gear" 7 "7 Gear" 8 "8 Gear" 12 "Reverse" 13 "Parking" 14 "Error" 15 "Not Available" ;
VAL_ 2566893315 TransmCurGear_FFAF03 124 "Reverse" 125 "Neutral" 126 "1st Gear" 127 "2nd Gear" 128 "3rd Gear" 129 "4th Gear" 130 "5th Gear" 131 "6th Gear" 132 "7th Gear" 133 "8th Gear" 251 "Park" 254 "Error" 255 "Not Available" ;
VAL_ 2566893315 PossTrqTransm 0 "Possible" 1 "Not Possible" 2 "Error" 3 "Not Available" ;
VAL_ 2566893315 SplitShaftPtoDrvlEngd 0 "Disengaged" 1 "Engaged" 2 "Error" 3 "Not Available" ;
VAL_ 2566893315 TransmDrvlEngd_FFAF03 0 "Driveline disengaged" 1 "Driveline engaged" 2 "Error" 3 "Not Available" ;
VAL_ 2566893315 TransmEngCrkEna_FFAF03 0 "Cranking disabled" 1 "Cranking enabled" 2 "Error" 3 "Not Available" ;
VAL_ 2566886730 FmsIAccMan_AutoCfg 0 "Off" 1 "Manual" 2 "Auto" 6 "Error" 7 "Not Available" ;
VAL_ 2566886730 FmsIsaAcousticWarnCfg 0 "Disable" 1 "Enable" 2 "Error" 3 "Not Available" ;
VAL_ 2566886730 FmsISACfg 0 "Off" 1 "On" 2 "Error" 3 "Not Available" ;
VAL_ 2566886730 FmsLkaCfg 0 "Off" 1 "On" 2 "Error Indicator" 3 "Not Available / Do not change" ;
VAL_ 2566886730 FmsAhbcCfg 0 "Not enabled" 1 "Enabled" 2 "Error Indicator" 3 "Not Available / Take no action" ;
VAL_ 2566886730 FmsIsaSpeedLimCfg 0 "Off" 1 "Manual" 2 "Automatic" 3 "Not Used1" 4 "Not Used2" 5 "Not Used3" 6 "Error" 7 "Not Available" ;
VAL_ 2566886730 FmsAebsSensCfg 0 "Mode #1, Lowest" 1 "Mode #2" 2 "Mode #3" 3 "Mode #4" 4 "Mode #5, Highest" 6 "Error condition" 7 "Not Available / Not valid" ;
VAL_ 2566886730 FmsDistWarnCfg 0 "Distance Warning Off" 1 "Distance Warning On" 2 "Error" 3 "Not Available" ;
VAL_ 2566886730 FmsAEBSCfg 0 "Deactivation of system" 1 "No deactivation of system" 2 "Reserved" 3 "Don�t' care / Take no action" ;
VAL_ 2566886730 FmsDdawSensCfg 0 "Low" 1 "Medium" 2 "High" 3 "Not Available" ;
VAL_ 2566886730 FmsDdawWarnCfg 0 "Visual + Acoustic Enabling" 1 "Visual Enabling" 2 "Error" 3 "Not available" ;
VAL_ 2566886730 FmsDoorOpenWarnFunctCfg 0 "Not Enabled" 1 "Enabled" 2 "Error" 3 "Not available" ;
VAL_ 2566886730 FmsBsisAcousticWarnCfg 0 "Disable" 1 "Enable" 2 "Error" 3 "Not Available" ;
VAL_ 2566886730 FmsMoisFunctCfg 0 "Disable" 1 "Enable" 2 "Error" 3 "Not Available" ;
VAL_ 2566886730 FmsRCTFunctCfg 0 "Disable" 1 "Enable" 2 "Error" 3 "Not Available" ;
VAL_ 2566886730 FmsRCTAcousticWarnCfg 0 "Disable" 1 "Enable" 2 "Error" 3 "Not Available" ;
VAL_ 2566886730 FmsBlindSpotFunctCfg 0 "Disable" 1 "Enable" 2 "Error" 3 "Not Available" ;
VAL_ 2566886730 FmsBlindSpotAcousticWarnCfg 0 "Disable" 1 "Enable" 2 "Error" 3 "Not Available" ;
VAL_ 2566886935 IsaSpeedLimCfgFmsFdbk 0 "Unlock (Def)" 1 "Lock" 2 "ACK" 3 "Not Available" ;
VAL_ 2566886935 IAccCfgFmsFdbk 0 "Unlock (Def)" 1 "Lock" 2 "ACK" 3 "Not Available" ;
VAL_ 2566886935 IsaAcousticWarnCfgFmsFdbk 0 "Unlock (Def)" 1 "Lock" 2 "ACK" 3 "Not Available" ;
VAL_ 2566886935 ISACfgFmsFdbk 0 "Unlock (Def)" 1 "Lock" 2 "ACK" 3 "Not Available" ;
VAL_ 2566886935 LkaCfgFmsFdbk 0 "Unlock (Def)" 1 "Lock" 2 "ACK" 3 "Not Available" ;
VAL_ 2566886935 AhbcCfgFmsFdbk 0 "Unlock (Def)" 1 "Lock" 2 "ACK" 3 "Not Available" ;
VAL_ 2566886935 DistWarnCfgFmsFdbk 0 "Unlock (Def)" 1 "Lock" 2 "ACK" 3 "Not Available" ;
VAL_ 2566886935 AebsSensCfgFmsFdbk 0 "Unlock (Def)" 1 "Lock" 2 "ACK" 3 "Not Available" ;
VAL_ 2566886935 AEBSCfgFmsFdbk 0 "Unlock (Def)" 1 "Lock" 2 "ACK" 3 "Not Available" ;
VAL_ 2566886935 DdawSensCfgFmsFdbk 0 "Unlock (Def)" 1 "Lock" 2 "ACK" 3 "Not Available" ;
VAL_ 2566886935 DdawWarnCfgFmsFdbk 0 "Unlock (Def)" 1 "Lock" 2 "ACK" 3 "Not Available" ;
VAL_ 2566886935 DoorOpenWarnFunctCfgFmsFdbk 0 "Unlock (Def)" 1 "Lock" 2 "ACK" 3 "Not Available" ;
VAL_ 2566886935 BsisAcousticWarnCfgFmsFdbk 0 "Unlock (Def)" 1 "Lock" 2 "ACK" 3 "Not Available" ;
VAL_ 2566886935 MoisFunctCfgFmsFdbk 0 "Unlock (Def)" 1 "Lock" 2 "ACK" 3 "Not Available" ;
VAL_ 2566886935 RCTAFunctCfgFmsFdbk 0 "Unlock (Def)" 1 "Lock" 2 "ACK" 3 "Not Available" ;
VAL_ 2566886935 RCTAcousticWarnCfgFmsFdbk 0 "Unlock (Def)" 1 "Lock" 2 "ACK" 3 "Not Available" ;
VAL_ 2566886935 BlindSpotFunctCfgFmsFdbk 0 "Unlock (Def)" 1 "Lock" 2 "ACK" 3 "Not Available" ;
VAL_ 2566886935 BlindSpotAcousticWarnCfgFmsFdbk 0 "Unlock (Def)" 1 "Lock" 2 "ACK" 3 "Not Available" ;
VAL_ 2583655201 WndLifterLeftSts 0 "Open" 1 "Closed" 2 "Stopped in intermediate position" 3 "Running Up" 4 "Running Down" 5 "Reverse" 6 "Error" 7 "Not Available" ;
VAL_ 2583655201 WndLifterRightSts 0 "Open" 1 "Closed" 2 "Stopped in intermediate position" 3 "Running Up" 4 "Running Down" 5 "Reverse" 6 "Error" 7 "Not Available" ;
VAL_ 2583655201 LowBatDev 0 "battery normal" 1 "battery low" 2 "error" 3 "not availble" ;
VAL_ 2583655201 TurnSigSw_FF7321 0 "No Turn being signaled" 1 "Left Turn to be Flashing" 2 "Right turn to be Flashing" 14 "Error, left + right sel. simult." 15 "Not Available (do not change)" ;
VAL_ 2583655201 HandBrkSts 0 "Not Set" 1 "Set" 2 "Error" 3 "Not Available" ;
VAL_ 2583655201 LckUnlckReqSrc 0 "Internal" 1 "External" 2 "Error" 3 "Not Available" ;
VAL_ 2583655201 ParkBrkCmd 0 "Apply not requested" 1 "Apply requested" 2 "Reserved" 3 "Don�t Care / Take no action" ;
VAL_ 2583655201 DevSts 0 "Present & not valid" 1 "Key Valid to crank" 2 "KeyValid/no crank-Lck/Unlck zone" 3 "KeyValid/no crank-Welcome zone" 4 "Not Used 1" 5 "Not Used 2" 6 "Error" 7 "Not Available/Not present" ;
VAL_ 2583655201 KeyCylSts 0 "unlock" 1 "lock" 2 "error" 3 "not available/no action" ;
VAL_ 2583655201 OpenStsOfDoor7 0 "Door closed" 1 "Door opened" 2 "Error" 3 "Not Available" ;
VAL_ 2583655201 LckStsOfDoor7 0 "Unlocked" 1 "Locked" 2 "Error" 3 "Not Available" ;
VAL_ 2583655201 OpenStsOfDoor6 0 "Door closed" 1 "Door opened" 2 "Error" 3 "Not Available" ;
VAL_ 2583655201 OpenStsOfDoor5 0 "Door closed" 1 "Door opened" 2 "Error" 3 "Not Available" ;
VAL_ 2583655201 OpenStsOfDoor4 0 "Door closed" 1 "Door opened" 2 "Error" 3 "Not Available" ;
VAL_ 2583655201 OpenStsOfDoor3 0 "Door closed" 1 "Door opened" 2 "Error" 3 "Not Available" ;
VAL_ 2583655201 OpenStsOfDoor2 0 "Door closed" 1 "Door opened" 2 "Error" 3 "Not Available" ;
VAL_ 2583655201 OpenStsOfDoor1 0 "Door closed" 1 "Door opened" 2 "Error" 3 "Not Available" ;
VAL_ 2583655201 LckStsOfDoor5 0 "Unlocked" 1 "Locked" 2 "Error" 3 "Not Available" ;
VAL_ 2583655201 LckStsOfDoor4 0 "Unlocked" 1 "Locked" 2 "Error" 3 "Not Available" ;
VAL_ 2583655201 LckStsOfDoor3 0 "Unlocked" 1 "Locked" 2 "Error" 3 "Not Available" ;
VAL_ 2583655201 LckStsOfDoor2 0 "Unlocked" 1 "Locked" 2 "Error" 3 "Not Available" ;
VAL_ 2583655201 LckStsOfDoor1 0 "Unlocked" 1 "Locked" 2 "Error" 3 "Not Available" ;
